VERSION "created by canmatrix"

NS_ :

BS_:

BU_: BDC_Body CHC DME1 EME FLA NiVi ZGW Kombi Kombi_Basis Diagnosetool_FA_CAN CDC_ZGW DME2 ELV Gliwa_T1_Host FA_CAN_Dummy

BO_ 672 CTR_ZV: 8 ZGW
 SG_ CTR_CLSY_DRD : 0|4@1+ (1,0) [0|15] "" EME
 SG_ CTR_CLSY_BTL : 16|4@1+ (1,0) [0|15] "" EME

BO_ 1942 ComponentTheftProtectionRequestK: 8 BDC_Body

BO_ 1943 ComponentTheftProtectionResponse: 8 Kombi

BO_ 1069 ConfigurationHUD2: 8 Kombi
 SG_ ListEntryAdditionalDisplayHUD : 56|8@1+ (1,0) [0|255] "" ZGW

BO_ 622 ConfigurationSChargeRemoteComman: 2 ZGW
 SG_ OperationChargeControlPlugRemote : 4|2@1+ (1,0) [0|3] "" EME

BO_ 439 ControlDisplayDrift: 8 ZGW
 SG_ ControlDriftAssistLampFrequency : 0|4@1+ (0.25,0.5) [0.625|1.375] "Hz" Kombi
 SG_ ControlDriftAssist : 6|2@1+ (1,0) [0|3] "" Kombi

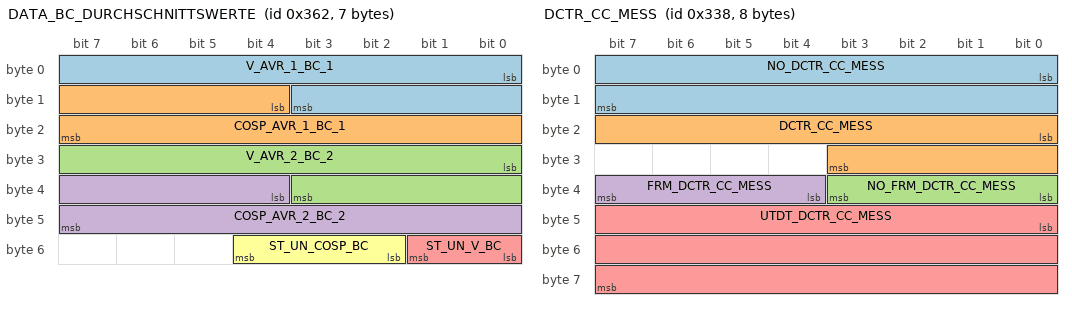
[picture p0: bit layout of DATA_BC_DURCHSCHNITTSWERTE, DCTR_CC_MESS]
BO_ 866 DATA_BC_DURCHSCHNITTSWERTE: 7 Kombi
 SG_ V_AVR_1_BC_1 : 0|12@1+ (0.1,0) [0|40.94] "This unit fulfills the required AUTOSAR reference to a unit. No real unit is defined." ZGW
 SG_ COSP_AVR_1_BC_1 : 12|12@1+ (0.1,0) [0|40.94] "This unit fulfills the required AUTOSAR reference to a unit. No real unit is defined." ZGW
 SG_ V_AVR_2_BC_2 : 24|12@1+ (0.1,0) [0|40.94] "This unit fulfills the required AUTOSAR reference to a unit. No real unit is defined." ZGW
 SG_ COSP_AVR_2_BC_2 : 36|12@1+ (0.1,0) [0|40.94] "This unit fulfills the required AUTOSAR reference to a unit. No real unit is defined." ZGW
 SG_ ST_UN_V_BC : 48|2@1+ (1,0) [0|3] "" ZGW
 SG_ ST_UN_COSP_BC : 50|3@1+ (1,0) [0|7] "" ZGW

BO_ 864 DATA_BC_FAHRTBEGINN: 7 Kombi
 SG_ HR_DPRT_BC : 0|8@1+ (1,0) [0|254] "h" ZGW
 SG_ MN_DPRT_BC : 8|8@1+ (1,0) [0|254] "min" ZGW
 SG_ DAY_DPRT_BC : 24|8@1+ (1,0) [1|254] "This unit fulfills the required AUTOSAR reference to a unit. No real unit is defined." ZGW
 SG_ MON_DPRT_BC : 36|4@1+ (1,0) [1|14] "This unit fulfills the required AUTOSAR reference to a unit. No real unit is defined." ZGW
 SG_ YR_DPRT_BC : 40|16@1+ (1,0) [0|65534] "This unit fulfills the required AUTOSAR reference to a unit. No real unit is defined." ZGW

BO_ 862 DATA_BC_REISEDATEN: 8 Kombi
 SG_ RDDUR_HRS : 0|12@1+ (1,0) [0|4094] "h" ZGW
 SG_ RDDUR_MNTS : 16|8@1+ (1,0) [0|254] "min" ZGW
 SG_ WAY_PSSD : 24|16@1+ (1,0) [0|65534] "This unit fulfills the required AUTOSAR reference to a unit. No real unit is defined." ZGW

BO_ 824 DCTR_CC_MESS: 8 Kombi_Basis
 SG_ NO_DCTR_CC_MESS : 0|16@1+ (1,0) [0|65534] "This unit fulfills the required AUTOSAR reference to a unit. No real unit is defined." ZGW
 SG_ DCTR_CC_MESS : 16|12@1+ (1,0) [0|4095] "" ZGW
 SG_ NO_FRM_DCTR_CC_MESS : 32|4@1+ (1,0) [0|14] "This unit fulfills the required AUTOSAR reference to a unit. No real unit is defined." ZGW
 SG_ FRM_DCTR_CC_MESS : 36|4@1+ (1,0) [0|14] "This unit fulfills the required AUTOSAR reference to a unit. No real unit is defined." ZGW
 SG_ UTDT_DCTR_CC_MESS : 40|24@1+ (1,0) [0|16777215] "This unit fulfills the required AUTOSAR reference to a unit. No real unit is defined." ZGW

BO_ 1022 DCTR_EOI_1: 8 DME1
 SG_ SU_PREV : 0|8@1+ (1,0) [0|255] "" ZGW
 SG_ SU_ST : 8|8@1+ (1,0) [0|255] "" ZGW
 SG_ SU_MEASMT : 16|8@1+ (1,0) [0|255] "" ZGW
 SG_ SU_RSLT : 24|8@1+ (1,0) [0|255] "" ZGW
 SG_ SU_FRC : 32|8@1+ (1,0) [0|255] "" ZGW

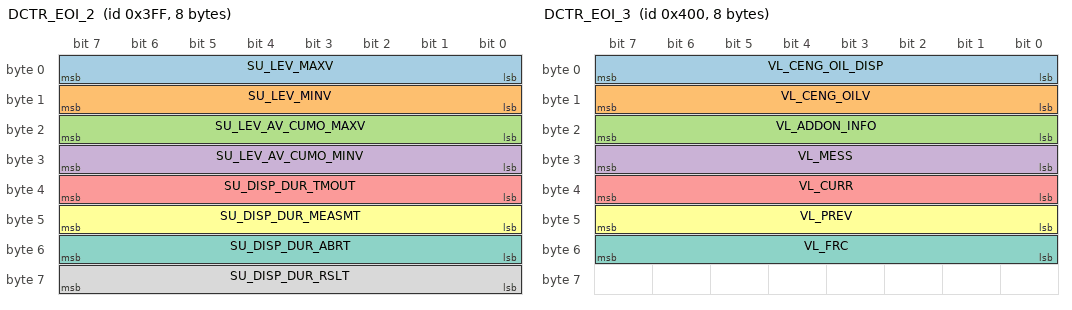
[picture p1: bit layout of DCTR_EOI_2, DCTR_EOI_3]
BO_ 1023 DCTR_EOI_2: 8 DME1
 SG_ SU_LEV_MAXV : 0|8@1+ (1,0) [0|250] "This unit fulfills the required AUTOSAR reference to a unit. No real unit is defined." ZGW
 SG_ SU_LEV_MINV : 8|8@1+ (1,0) [0|250] "This unit fulfills the required AUTOSAR reference to a unit. No real unit is defined." ZGW
 SG_ SU_LEV_AV_CUMO_MAXV : 16|8@1+ (1,0) [0|250] "This unit fulfills the required AUTOSAR reference to a unit. No real unit is defined." ZGW
 SG_ SU_LEV_AV_CUMO_MINV : 24|8@1+ (1,0) [0|250] "This unit fulfills the required AUTOSAR reference to a unit. No real unit is defined." ZGW
 SG_ SU_DISP_DUR_TMOUT : 32|8@1+ (1,0) [0|250] "s" ZGW
 SG_ SU_DISP_DUR_MEASMT : 40|8@1+ (1,0) [0|250] "s" ZGW
 SG_ SU_DISP_DUR_ABRT : 48|8@1+ (1,0) [0|250] "min" ZGW
 SG_ SU_DISP_DUR_RSLT : 56|8@1+ (1,0) [0|250] "min" ZGW

BO_ 1024 DCTR_EOI_3: 8 DME1
 SG_ VL_CENG_OIL_DISP : 0|8@1+ (1,0) [0|255] "" ZGW
 SG_ VL_CENG_OILV : 8|8@1+ (1,0) [0|250] "This unit fulfills the required AUTOSAR reference to a unit. No real unit is defined." ZGW
 SG_ VL_ADDON_INFO : 16|8@1+ (1,0) [0|250] "This unit fulfills the required AUTOSAR reference to a unit. No real unit is defined." ZGW
 SG_ VL_MESS : 24|8@1+ (1,0) [0|255] "" ZGW
 SG_ VL_CURR : 32|8@1+ (1,0) [0|250] "This unit fulfills the required AUTOSAR reference to a unit. No real unit is defined." ZGW
 SG_ VL_PREV : 40|8@1+ (1,0) [0|255] "" ZGW
 SG_ VL_FRC : 48|8@1+ (1,0) [0|250] "min" ZGW

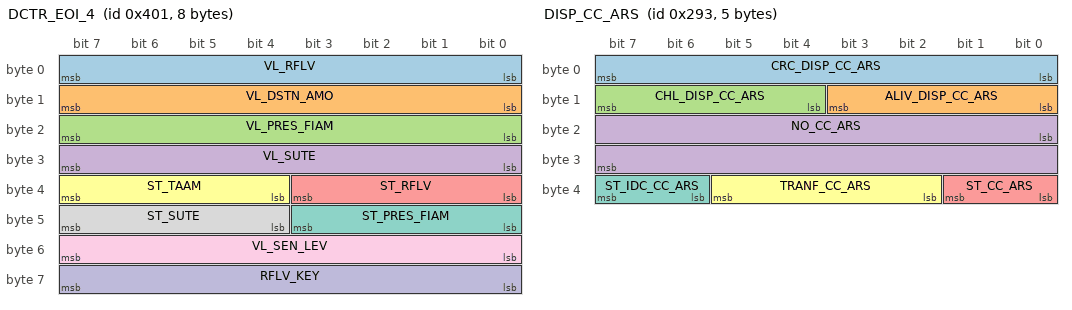
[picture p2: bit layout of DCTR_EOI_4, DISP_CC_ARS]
BO_ 1025 DCTR_EOI_4: 8 DME1
 SG_ VL_RFLV : 0|8@1+ (0.1,0) [0|2.5] "This unit fulfills the required AUTOSAR reference to a unit. No real unit is defined." ZGW
 SG_ VL_DSTN_AMO : 8|8@1+ (0.1,0) [0|2.5] "This unit fulfills the required AUTOSAR reference to a unit. No real unit is defined." ZGW
 SG_ VL_PRES_FIAM : 16|8@1+ (0.1,0) [0|2.5] "This unit fulfills the required AUTOSAR reference to a unit. No real unit is defined." ZGW
 SG_ VL_SUTE : 24|8@1+ (1,0) [0|250] "°C" ZGW
 SG_ ST_RFLV : 32|4@1+ (1,0) [0|15] "" ZGW
 SG_ ST_TAAM : 36|4@1+ (1,0) [0|15] "" ZGW
 SG_ ST_PRES_FIAM : 40|4@1+ (1,0) [0|15] "" ZGW
 SG_ ST_SUTE : 44|4@1+ (1,0) [0|15] "" ZGW
 SG_ VL_SEN_LEV : 48|8@1+ (1,0) [0|250] "mm" ZGW
 SG_ RFLV_KEY : 56|8@1+ (0.1,-12.8) [-14.08|-11.56] "l" BDC_Body

BO_ 919 DIAG_OBD_ENG: 7 ZGW
 SG_ ST_OBD_CYC : 0|6@1+ (1,0) [0|63] "" BDC_Body,CHC

BO_ 1000 DIAG_OBD_ENGMG_EL: 2 EME
 SG_ RQ_MIL_DIAG_OBD_ENGMG_EL : 0|2@1+ (1,0) [0|3] "" Vector__XXX
 SG_ RQ_RST_OBD_DIAG : 2|2@1+ (1,0) [0|3] "" ZGW

BO_ 514 DIMMUNG: 2 BDC_Body
 SG_ CTR_ILUM_SW : 0|8@1+ (1,0) [0|254] "This unit fulfills the required AUTOSAR reference to a unit. No real unit is defined." ZGW,Kombi,Kombi_Basis,DME1

BO_ 659 DISP_CC_ARS: 5 ZGW
 SG_ CRC_DISP_CC_ARS : 0|8@1+ (1,0) [0|255] "This unit fulfills the required AUTOSAR reference to a unit. No real unit is defined." Vector__XXX
 SG_ ALIV_DISP_CC_ARS : 8|4@1+ (1,0) [0|14] "This unit fulfills the required AUTOSAR reference to a unit. No real unit is defined." Vector__XXX
 SG_ CHL_DISP_CC_ARS : 12|4@1+ (1,0) [0|14] "This unit fulfills the required AUTOSAR reference to a unit. No real unit is defined." Vector__XXX
 SG_ NO_CC_ARS : 16|16@1+ (1,0) [0|65534] "This unit fulfills the required AUTOSAR reference to a unit. No real unit is defined." Vector__XXX
 SG_ ST_CC_ARS : 32|2@1+ (1,0) [0|3] "" Vector__XXX
 SG_ TRANF_CC_ARS : 34|4@1+ (1,0) [0|14] "s" Vector__XXX
 SG_ ST_IDC_CC_ARS : 38|2@1+ (1,0) [0|3] "" Vector__XXX

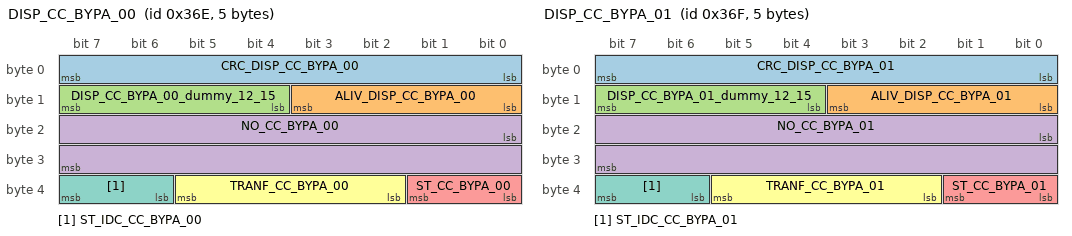
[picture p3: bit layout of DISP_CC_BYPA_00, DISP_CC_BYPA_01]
BO_ 878 DISP_CC_BYPA_00: 5 ZGW
 SG_ CRC_DISP_CC_BYPA_00 : 0|8@1+ (1,0) [0|255] "This unit fulfills the required AUTOSAR reference to a unit. No real unit is defined." Vector__XXX
 SG_ ALIV_DISP_CC_BYPA_00 : 8|4@1+ (1,0) [0|14] "This unit fulfills the required AUTOSAR reference to a unit. No real unit is defined." Vector__XXX
 SG_ DISP_CC_BYPA_00_dummy_12_15 : 12|4@1+ (1,0) [-8|7] "" Vector__XXX
 SG_ NO_CC_BYPA_00 : 16|16@1+ (1,0) [0|65534] "This unit fulfills the required AUTOSAR reference to a unit. No real unit is defined." Vector__XXX
 SG_ ST_CC_BYPA_00 : 32|2@1+ (1,0) [0|3] "" Vector__XXX
 SG_ TRANF_CC_BYPA_00 : 34|4@1+ (1,0) [0|14] "This unit fulfills the required AUTOSAR reference to a unit. No real unit is defined." Vector__XXX
 SG_ ST_IDC_CC_BYPA_00 : 38|2@1+ (1,0) [0|3] "" Vector__XXX

BO_ 879 DISP_CC_BYPA_01: 5 ZGW
 SG_ CRC_DISP_CC_BYPA_01 : 0|8@1+ (1,0) [0|255] "This unit fulfills the required AUTOSAR reference to a unit. No real unit is defined." Vector__XXX
 SG_ ALIV_DISP_CC_BYPA_01 : 8|4@1+ (1,0) [0|14] "This unit fulfills the required AUTOSAR reference to a unit. No real unit is defined." Vector__XXX
 SG_ DISP_CC_BYPA_01_dummy_12_15 : 12|4@1+ (1,0) [-8|7] "" Vector__XXX
 SG_ NO_CC_BYPA_01 : 16|16@1+ (1,0) [0|65534] "This unit fulfills the required AUTOSAR reference to a unit. No real unit is defined." Vector__XXX
 SG_ ST_CC_BYPA_01 : 32|2@1+ (1,0) [0|3] "" Vector__XXX
 SG_ TRANF_CC_BYPA_01 : 34|4@1+ (1,0) [0|14] "This unit fulfills the required AUTOSAR reference to a unit. No real unit is defined." Vector__XXX
 SG_ ST_IDC_CC_BYPA_01 : 38|2@1+ (1,0) [0|3] "" Vector__XXX

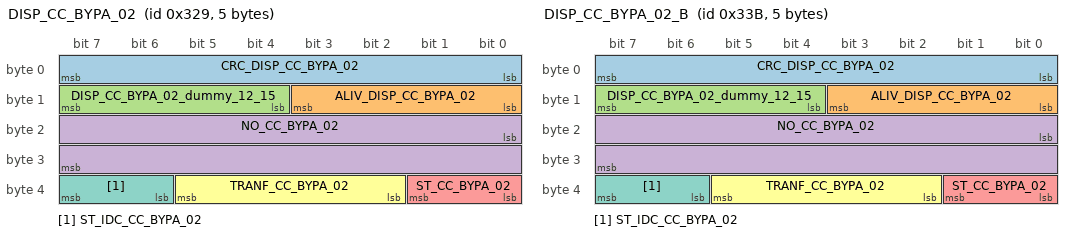
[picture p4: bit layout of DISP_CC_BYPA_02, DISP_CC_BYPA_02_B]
BO_ 809 DISP_CC_BYPA_02: 5 ZGW
 SG_ CRC_DISP_CC_BYPA_02 : 0|8@1+ (1,0) [0|255] "This unit fulfills the required AUTOSAR reference to a unit. No real unit is defined." Vector__XXX
 SG_ ALIV_DISP_CC_BYPA_02 : 8|4@1+ (1,0) [0|14] "This unit fulfills the required AUTOSAR reference to a unit. No real unit is defined." Vector__XXX
 SG_ DISP_CC_BYPA_02_dummy_12_15 : 12|4@1+ (1,0) [-8|7] "" Vector__XXX
 SG_ NO_CC_BYPA_02 : 16|16@1+ (1,0) [0|65534] "This unit fulfills the required AUTOSAR reference to a unit. No real unit is defined." Vector__XXX
 SG_ ST_CC_BYPA_02 : 32|2@1+ (1,0) [0|3] "" Vector__XXX
 SG_ TRANF_CC_BYPA_02 : 34|4@1+ (1,0) [1|14] "s" Vector__XXX
 SG_ ST_IDC_CC_BYPA_02 : 38|2@1+ (1,0) [0|3] "" Vector__XXX

BO_ 827 DISP_CC_BYPA_02_B: 5 ZGW
 SG_ CRC_DISP_CC_BYPA_02 : 0|8@1+ (1,0) [0|255] "This unit fulfills the required AUTOSAR reference to a unit. No real unit is defined." Vector__XXX
 SG_ ALIV_DISP_CC_BYPA_02 : 8|4@1+ (1,0) [0|14] "This unit fulfills the required AUTOSAR reference to a unit. No real unit is defined." Vector__XXX
 SG_ DISP_CC_BYPA_02_dummy_12_15 : 12|4@1+ (1,0) [-8|7] "" Vector__XXX
 SG_ NO_CC_BYPA_02 : 16|16@1+ (1,0) [0|65534] "This unit fulfills the required AUTOSAR reference to a unit. No real unit is defined." Vector__XXX
 SG_ ST_CC_BYPA_02 : 32|2@1+ (1,0) [0|3] "" Vector__XXX
 SG_ TRANF_CC_BYPA_02 : 34|4@1+ (1,0) [1|14] "s" Vector__XXX
 SG_ ST_IDC_CC_BYPA_02 : 38|2@1+ (1,0) [0|3] "" Vector__XXX

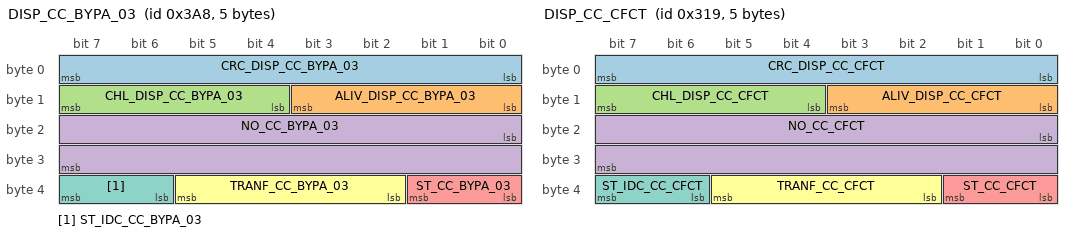
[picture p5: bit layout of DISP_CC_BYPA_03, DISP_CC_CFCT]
BO_ 936 DISP_CC_BYPA_03: 5 ZGW
 SG_ CRC_DISP_CC_BYPA_03 : 0|8@1+ (1,0) [0|255] "This unit fulfills the required AUTOSAR reference to a unit. No real unit is defined." Vector__XXX
 SG_ ALIV_DISP_CC_BYPA_03 : 8|4@1+ (1,0) [0|14] "This unit fulfills the required AUTOSAR reference to a unit. No real unit is defined." Vector__XXX
 SG_ CHL_DISP_CC_BYPA_03 : 12|4@1+ (1,0) [0|14] "This unit fulfills the required AUTOSAR reference to a unit. No real unit is defined." Vector__XXX
 SG_ NO_CC_BYPA_03 : 16|16@1+ (1,0) [0|65534] "This unit fulfills the required AUTOSAR reference to a unit. No real unit is defined." Vector__XXX
 SG_ ST_CC_BYPA_03 : 32|2@1+ (1,0) [0|3] "" Vector__XXX
 SG_ TRANF_CC_BYPA_03 : 34|4@1+ (1,0) [1|14] "s" Vector__XXX
 SG_ ST_IDC_CC_BYPA_03 : 38|2@1+ (1,0) [0|3] "" Vector__XXX

BO_ 793 DISP_CC_CFCT: 5 BDC_Body
 SG_ CRC_DISP_CC_CFCT : 0|8@1+ (1,0) [0|255] "This unit fulfills the required AUTOSAR reference to a unit. No real unit is defined." Vector__XXX
 SG_ ALIV_DISP_CC_CFCT : 8|4@1+ (1,0) [0|14] "This unit fulfills the required AUTOSAR reference to a unit. No real unit is defined." Vector__XXX
 SG_ CHL_DISP_CC_CFCT : 12|4@1+ (1,0) [0|14] "This unit fulfills the required AUTOSAR reference to a unit. No real unit is defined." Vector__XXX
 SG_ NO_CC_CFCT : 16|16@1+ (1,0) [0|65534] "This unit fulfills the required AUTOSAR reference to a unit. No real unit is defined." Vector__XXX
 SG_ ST_CC_CFCT : 32|2@1+ (1,0) [0|3] "" Vector__XXX
 SG_ TRANF_CC_CFCT : 34|4@1+ (1,0) [0|14] "This unit fulfills the required AUTOSAR reference to a unit. No real unit is defined." Vector__XXX
 SG_ ST_IDC_CC_CFCT : 38|2@1+ (1,0) [0|3] "" Vector__XXX

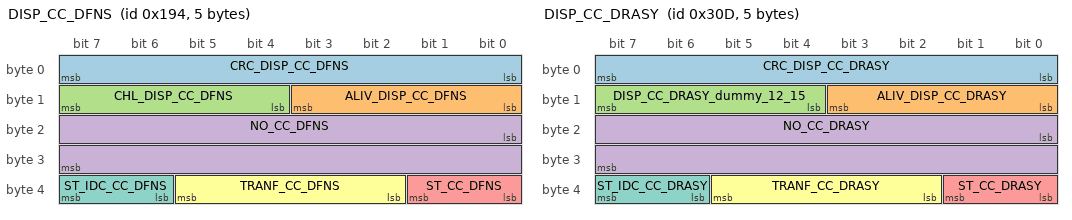
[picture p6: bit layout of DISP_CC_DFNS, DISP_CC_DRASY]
BO_ 404 DISP_CC_DFNS: 5 DME1
 SG_ CRC_DISP_CC_DFNS : 0|8@1+ (1,0) [0|255] "This unit fulfills the required AUTOSAR reference to a unit. No real unit is defined." Vector__XXX
 SG_ ALIV_DISP_CC_DFNS : 8|4@1+ (1,0) [0|14] "This unit fulfills the required AUTOSAR reference to a unit. No real unit is defined." Vector__XXX
 SG_ CHL_DISP_CC_DFNS : 12|4@1+ (1,0) [0|14] "This unit fulfills the required AUTOSAR reference to a unit. No real unit is defined." Vector__XXX
 SG_ NO_CC_DFNS : 16|16@1+ (1,0) [0|65534] "This unit fulfills the required AUTOSAR reference to a unit. No real unit is defined." Vector__XXX
 SG_ ST_CC_DFNS : 32|2@1+ (1,0) [0|3] "" Vector__XXX
 SG_ TRANF_CC_DFNS : 34|4@1+ (1,0) [0|14] "s" Vector__XXX
 SG_ ST_IDC_CC_DFNS : 38|2@1+ (1,0) [0|3] "" Vector__XXX

BO_ 781 DISP_CC_DRASY: 5 ZGW
 SG_ CRC_DISP_CC_DRASY : 0|8@1+ (1,0) [0|255] "This unit fulfills the required AUTOSAR reference to a unit. No real unit is defined." Vector__XXX
 SG_ ALIV_DISP_CC_DRASY : 8|4@1+ (1,0) [0|14] "This unit fulfills the required AUTOSAR reference to a unit. No real unit is defined." Vector__XXX
 SG_ DISP_CC_DRASY_dummy_12_15 : 12|4@1+ (1,0) [-8|7] "" Vector__XXX
 SG_ NO_CC_DRASY : 16|16@1+ (1,0) [0|65534] "This unit fulfills the required AUTOSAR reference to a unit. No real unit is defined." Vector__XXX
 SG_ ST_CC_DRASY : 32|2@1+ (1,0) [0|3] "" Vector__XXX
 SG_ TRANF_CC_DRASY : 34|4@1+ (1,0) [1|14] "s" Vector__XXX
 SG_ ST_IDC_CC_DRASY : 38|2@1+ (1,0) [0|3] "" Vector__XXX

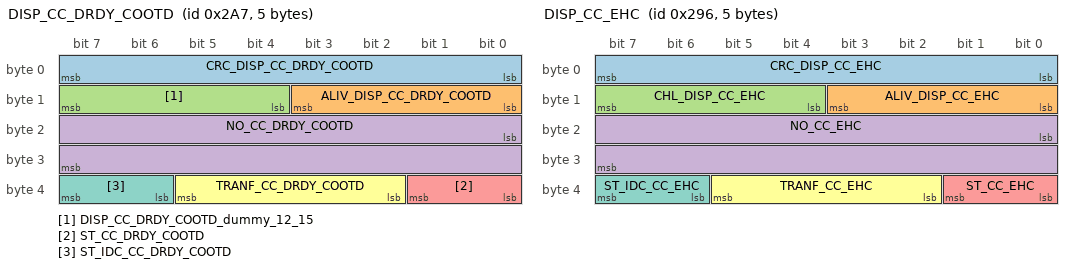
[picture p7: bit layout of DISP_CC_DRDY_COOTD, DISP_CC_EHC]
BO_ 679 DISP_CC_DRDY_COOTD: 5 ZGW
 SG_ CRC_DISP_CC_DRDY_COOTD : 0|8@1+ (1,0) [0|255] "This unit fulfills the required AUTOSAR reference to a unit. No real unit is defined." Vector__XXX
 SG_ ALIV_DISP_CC_DRDY_COOTD : 8|4@1+ (1,0) [0|14] "This unit fulfills the required AUTOSAR reference to a unit. No real unit is defined." Vector__XXX
 SG_ DISP_CC_DRDY_COOTD_dummy_12_15 : 12|4@1+ (1,0) [-8|7] "" Vector__XXX
 SG_ NO_CC_DRDY_COOTD : 16|16@1+ (1,0) [0|65534] "This unit fulfills the required AUTOSAR reference to a unit. No real unit is defined." Vector__XXX
 SG_ ST_CC_DRDY_COOTD : 32|2@1+ (1,0) [0|3] "" Vector__XXX
 SG_ TRANF_CC_DRDY_COOTD : 34|4@1+ (1,0) [0|14] "This unit fulfills the required AUTOSAR reference to a unit. No real unit is defined." Vector__XXX
 SG_ ST_IDC_CC_DRDY_COOTD : 38|2@1+ (1,0) [0|3] "" Vector__XXX

BO_ 662 DISP_CC_EHC: 5 CHC
 SG_ CRC_DISP_CC_EHC : 0|8@1+ (1,0) [0|255] "This unit fulfills the required AUTOSAR reference to a unit. No real unit is defined." Vector__XXX
 SG_ ALIV_DISP_CC_EHC : 8|4@1+ (1,0) [0|14] "This unit fulfills the required AUTOSAR reference to a unit. No real unit is defined." Vector__XXX
 SG_ CHL_DISP_CC_EHC : 12|4@1+ (1,0) [0|14] "This unit fulfills the required AUTOSAR reference to a unit. No real unit is defined." Vector__XXX
 SG_ NO_CC_EHC : 16|16@1+ (1,0) [0|65534] "This unit fulfills the required AUTOSAR reference to a unit. No real unit is defined." Vector__XXX
 SG_ ST_CC_EHC : 32|2@1+ (1,0) [0|3] "" Vector__XXX
 SG_ TRANF_CC_EHC : 34|4@1+ (1,0) [0|14] "s" Vector__XXX
 SG_ ST_IDC_CC_EHC : 38|2@1+ (1,0) [0|3] "" Vector__XXX

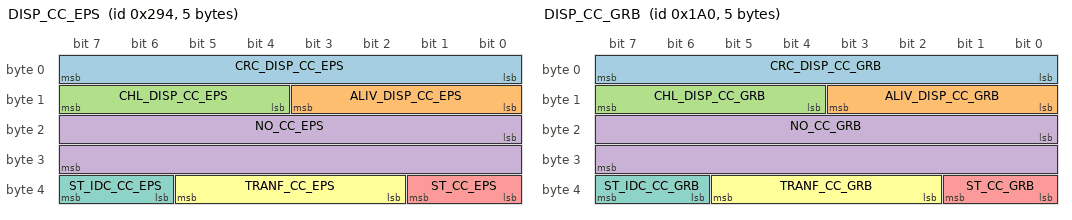
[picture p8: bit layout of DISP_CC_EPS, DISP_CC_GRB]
BO_ 660 DISP_CC_EPS: 5 ZGW
 SG_ CRC_DISP_CC_EPS : 0|8@1+ (1,0) [0|255] "This unit fulfills the required AUTOSAR reference to a unit. No real unit is defined." Vector__XXX
 SG_ ALIV_DISP_CC_EPS : 8|4@1+ (1,0) [0|14] "This unit fulfills the required AUTOSAR reference to a unit. No real unit is defined." Vector__XXX
 SG_ CHL_DISP_CC_EPS : 12|4@1+ (1,0) [0|14] "This unit fulfills the required AUTOSAR reference to a unit. No real unit is defined." Vector__XXX
 SG_ NO_CC_EPS : 16|16@1+ (1,0) [0|65534] "This unit fulfills the required AUTOSAR reference to a unit. No real unit is defined." Vector__XXX
 SG_ ST_CC_EPS : 32|2@1+ (1,0) [0|3] "" Vector__XXX
 SG_ TRANF_CC_EPS : 34|4@1+ (1,0) [0|14] "s" Vector__XXX
 SG_ ST_IDC_CC_EPS : 38|2@1+ (1,0) [0|3] "" Vector__XXX

BO_ 416 DISP_CC_GRB: 5 DME1
 SG_ CRC_DISP_CC_GRB : 0|8@1+ (1,0) [0|255] "This unit fulfills the required AUTOSAR reference to a unit. No real unit is defined." Vector__XXX
 SG_ ALIV_DISP_CC_GRB : 8|4@1+ (1,0) [0|14] "This unit fulfills the required AUTOSAR reference to a unit. No real unit is defined." Vector__XXX
 SG_ CHL_DISP_CC_GRB : 12|4@1+ (1,0) [0|14] "This unit fulfills the required AUTOSAR reference to a unit. No real unit is defined." Vector__XXX
 SG_ NO_CC_GRB : 16|16@1+ (1,0) [0|65532] "This unit fulfills the required AUTOSAR reference to a unit. No real unit is defined." Vector__XXX
 SG_ ST_CC_GRB : 32|2@1+ (1,0) [0|3] "" Vector__XXX
 SG_ TRANF_CC_GRB : 34|4@1+ (1,0) [0|12] "s" Vector__XXX
 SG_ ST_IDC_CC_GRB : 38|2@1+ (1,0) [0|3] "" Vector__XXX

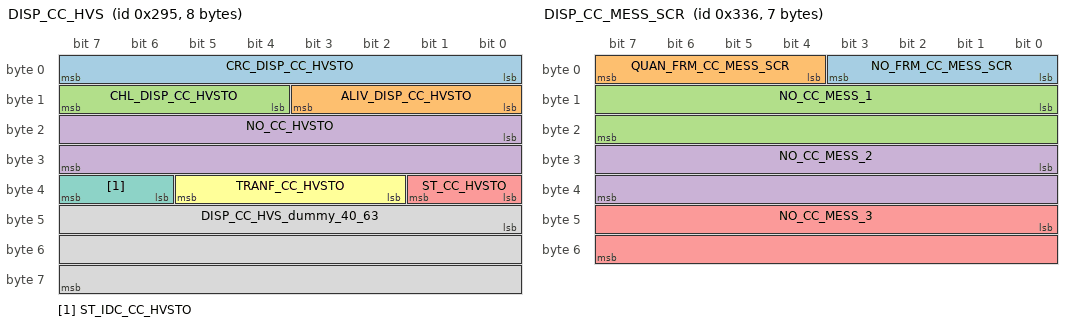
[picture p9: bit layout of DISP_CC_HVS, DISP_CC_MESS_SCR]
BO_ 661 DISP_CC_HVS: 8 EME
 SG_ CRC_DISP_CC_HVSTO : 0|8@1+ (1,0) [0|255] "This unit fulfills the required AUTOSAR reference to a unit. No real unit is defined." Vector__XXX
 SG_ ALIV_DISP_CC_HVSTO : 8|4@1+ (1,0) [0|14] "This unit fulfills the required AUTOSAR reference to a unit. No real unit is defined." Vector__XXX
 SG_ CHL_DISP_CC_HVSTO : 12|4@1+ (1,0) [0|14] "This unit fulfills the required AUTOSAR reference to a unit. No real unit is defined." Vector__XXX
 SG_ NO_CC_HVSTO : 16|16@1+ (1,0) [0|65534] "This unit fulfills the required AUTOSAR reference to a unit. No real unit is defined." Vector__XXX
 SG_ ST_CC_HVSTO : 32|2@1+ (1,0) [0|3] "" Vector__XXX
 SG_ TRANF_CC_HVSTO : 34|4@1+ (1,0) [0|14] "This unit fulfills the required AUTOSAR reference to a unit. No real unit is defined." Vector__XXX
 SG_ ST_IDC_CC_HVSTO : 38|2@1+ (1,0) [0|3] "" Vector__XXX
 SG_ DISP_CC_HVS_dummy_40_63 : 40|24@1+ (1,0) [-8388608|8388607] "" Vector__XXX

BO_ 822 DISP_CC_MESS_SCR: 7 Kombi
 SG_ NO_FRM_CC_MESS_SCR : 0|4@1+ (1,0) [0|14] "This unit fulfills the required AUTOSAR reference to a unit. No real unit is defined." ZGW
 SG_ QUAN_FRM_CC_MESS_SCR : 4|4@1+ (1,0) [0|14] "This unit fulfills the required AUTOSAR reference to a unit. No real unit is defined." ZGW
 SG_ NO_CC_MESS_1 : 8|16@1+ (1,0) [0|65534] "This unit fulfills the required AUTOSAR reference to a unit. No real unit is defined." ZGW
 SG_ NO_CC_MESS_2 : 24|16@1+ (1,0) [0|65534] "This unit fulfills the required AUTOSAR reference to a unit. No real unit is defined." ZGW
 SG_ NO_CC_MESS_3 : 40|16@1+ (1,0) [0|65534] "This unit fulfills the required AUTOSAR reference to a unit. No real unit is defined." ZGW

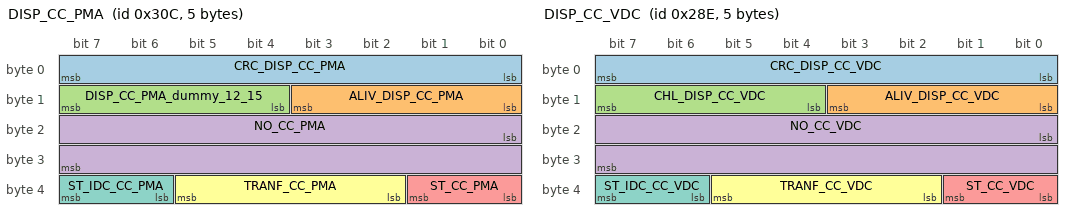
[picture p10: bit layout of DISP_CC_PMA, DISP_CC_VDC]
BO_ 780 DISP_CC_PMA: 5 ZGW
 SG_ CRC_DISP_CC_PMA : 0|8@1+ (1,0) [0|255] "This unit fulfills the required AUTOSAR reference to a unit. No real unit is defined." Vector__XXX
 SG_ ALIV_DISP_CC_PMA : 8|4@1+ (1,0) [0|14] "This unit fulfills the required AUTOSAR reference to a unit. No real unit is defined." Vector__XXX
 SG_ DISP_CC_PMA_dummy_12_15 : 12|4@1+ (1,0) [-8|7] "" Vector__XXX
 SG_ NO_CC_PMA : 16|16@1+ (1,0) [0|65534] "This unit fulfills the required AUTOSAR reference to a unit. No real unit is defined." Vector__XXX
 SG_ ST_CC_PMA : 32|2@1+ (1,0) [0|3] "" Vector__XXX
 SG_ TRANF_CC_PMA : 34|4@1+ (1,0) [1|14] "s" Vector__XXX
 SG_ ST_IDC_CC_PMA : 38|2@1+ (1,0) [0|3] "" Vector__XXX

BO_ 654 DISP_CC_VDC: 5 ZGW
 SG_ CRC_DISP_CC_VDC : 0|8@1+ (1,0) [0|255] "This unit fulfills the required AUTOSAR reference to a unit. No real unit is defined." Vector__XXX
 SG_ ALIV_DISP_CC_VDC : 8|4@1+ (1,0) [0|14] "This unit fulfills the required AUTOSAR reference to a unit. No real unit is defined." Vector__XXX
 SG_ CHL_DISP_CC_VDC : 12|4@1+ (1,0) [0|14] "This unit fulfills the required AUTOSAR reference to a unit. No real unit is defined." Vector__XXX
 SG_ NO_CC_VDC : 16|16@1+ (1,0) [0|65534] "This unit fulfills the required AUTOSAR reference to a unit. No real unit is defined." Vector__XXX
 SG_ ST_CC_VDC : 32|2@1+ (1,0) [0|3] "" Vector__XXX
 SG_ TRANF_CC_VDC : 34|4@1+ (1,0) [0|14] "s" Vector__XXX
 SG_ ST_IDC_CC_VDC : 38|2@1+ (1,0) [0|3] "" Vector__XXX

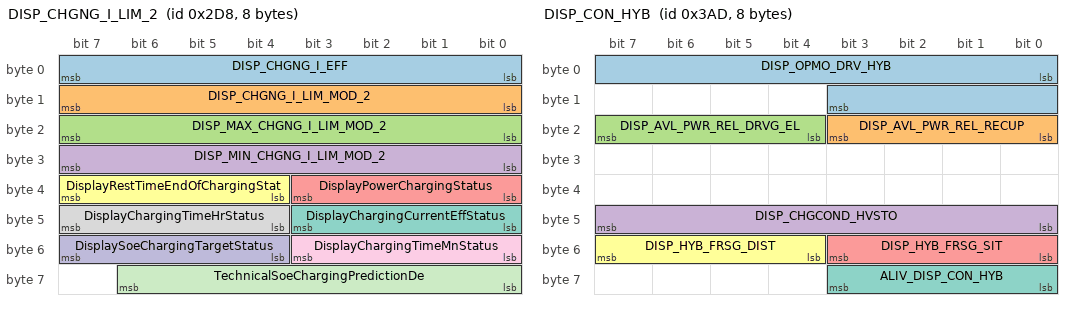
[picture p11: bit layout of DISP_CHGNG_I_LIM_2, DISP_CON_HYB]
BO_ 728 DISP_CHGNG_I_LIM_2: 8 EME
 SG_ DISP_CHGNG_I_EFF : 0|8@1+ (1,0) [0|250] "A" ZGW,Kombi,Kombi_Basis
 SG_ DISP_CHGNG_I_LIM_MOD_2 : 8|8@1+ (1,0) [0|250] "A" ZGW
 SG_ DISP_MAX_CHGNG_I_LIM_MOD_2 : 16|8@1+ (1,0) [0|250] "A" ZGW
 SG_ DISP_MIN_CHGNG_I_LIM_MOD_2 : 24|8@1+ (1,0) [0|250] "A" ZGW
 SG_ DisplayPowerChargingStatus : 32|4@1+ (1,0) [0|15] "" ZGW,Kombi
 SG_ DisplayRestTimeEndOfChargingStat : 36|4@1+ (1,0) [0|15] "" Kombi
 SG_ DisplayChargingCurrentEffStatus : 40|4@1+ (1,0) [0|15] "" Kombi
 SG_ DisplayChargingTimeHrStatus : 44|4@1+ (1,0) [0|15] "" Kombi
 SG_ DisplayChargingTimeMnStatus : 48|4@1+ (1,0) [0|15] "" Kombi
 SG_ DisplaySoeChargingTargetStatus : 52|4@1+ (1,0) [0|15] "" Kombi
 SG_ TechnicalSoeChargingPredictionDe : 56|7@1+ (1,0) [0|100] "%" Kombi

BO_ 941 DISP_CON_HYB: 8 DME1
 SG_ DISP_OPMO_DRV_HYB : 0|12@1+ (1,0) [0|4095] "" ZGW,Kombi,Kombi_Basis
 SG_ DISP_AVL_PWR_REL_RECUP : 16|4@1+ (10,0) [0|1000] "%" ZGW
 SG_ DISP_AVL_PWR_REL_DRVG_EL : 20|4@1+ (10,0) [0|1000] "%" ZGW
 SG_ DISP_CHGCOND_HVSTO : 40|8@1+ (0.5,0) [0|50] "%" CDC_ZGW,Kombi,BDC_Body,ZGW
 SG_ DISP_HYB_FRSG_SIT : 48|4@1+ (1,0) [0|15] "" ZGW
 SG_ DISP_HYB_FRSG_DIST : 52|4@1+ (1,0) [0|15] "" ZGW
 SG_ ALIV_DISP_CON_HYB : 56|4@1+ (1,0) [0|14] "This unit fulfills the required AUTOSAR reference to a unit. No real unit is defined." Kombi,Kombi_Basis

BO_ 1036 DISP_COSA_HYB: 5 EME
 SG_ DISP_EFFS_HYB : 8|8@1+ (1,0) [0|100] "%" ZGW,Kombi

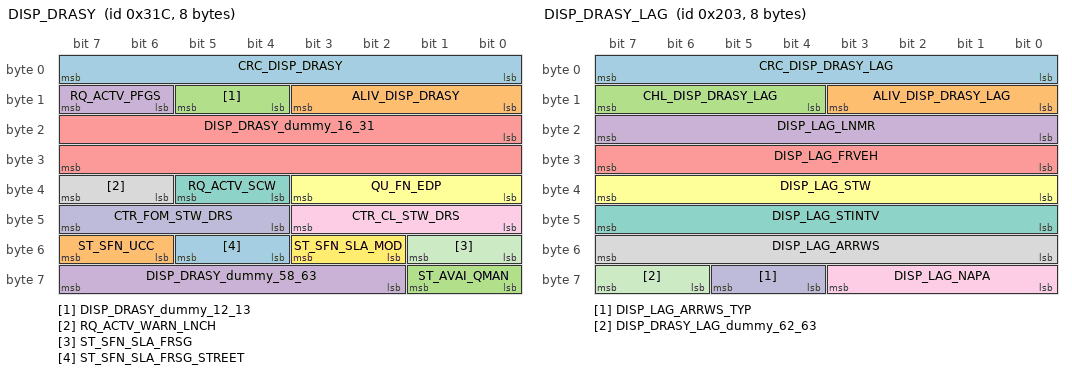
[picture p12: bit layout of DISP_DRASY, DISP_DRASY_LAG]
BO_ 796 DISP_DRASY: 8 ZGW
 SG_ CRC_DISP_DRASY : 0|8@1+ (1,0) [0|255] "This unit fulfills the required AUTOSAR reference to a unit. No real unit is defined." Vector__XXX
 SG_ ALIV_DISP_DRASY : 8|4@1+ (1,0) [0|14] "This unit fulfills the required AUTOSAR reference to a unit. No real unit is defined." Vector__XXX
 SG_ DISP_DRASY_dummy_12_13 : 12|2@1+ (1,0) [-2|1] "" Vector__XXX
 SG_ RQ_ACTV_PFGS : 14|2@1+ (1,0) [0|3] "" Vector__XXX
 SG_ DISP_DRASY_dummy_16_31 : 16|16@1+ (1,0) [-32768|32767] "" Vector__XXX
 SG_ QU_FN_EDP : 32|4@1+ (1,0) [0|15] "" Vector__XXX
 SG_ RQ_ACTV_SCW : 36|2@1+ (1,0) [0|3] "" Vector__XXX
 SG_ RQ_ACTV_WARN_LNCH : 38|2@1+ (1,0) [0|3] "" Vector__XXX
 SG_ CTR_CL_STW_DRS : 40|4@1+ (1,0) [0|15] "" Vector__XXX
 SG_ CTR_FOM_STW_DRS : 44|4@1+ (1,0) [0|15] "" Vector__XXX
 SG_ ST_SFN_SLA_FRSG : 48|2@1+ (1,0) [0|3] "" Vector__XXX
 SG_ ST_SFN_SLA_MOD : 50|2@1+ (1,0) [0|3] "" Vector__XXX
 SG_ ST_SFN_SLA_FRSG_STREET : 52|2@1+ (1,0) [0|3] "" Vector__XXX
 SG_ ST_SFN_UCC : 54|2@1+ (1,0) [0|3] "" Vector__XXX
 SG_ ST_AVAI_QMAN : 56|2@1+ (1,0) [0|3] "" Vector__XXX
 SG_ DISP_DRASY_dummy_58_63 : 58|6@1+ (1,0) [-32|31] "" Vector__XXX

BO_ 515 DISP_DRASY_LAG: 8 ZGW
 SG_ CRC_DISP_DRASY_LAG : 0|8@1+ (1,0) [0|255] "This unit fulfills the required AUTOSAR reference to a unit. No real unit is defined." Vector__XXX
 SG_ ALIV_DISP_DRASY_LAG : 8|4@1+ (1,0) [0|14] "This unit fulfills the required AUTOSAR reference to a unit. No real unit is defined." Vector__XXX
 SG_ CHL_DISP_DRASY_LAG : 12|4@1+ (1,0) [0|14] "This unit fulfills the required AUTOSAR reference to a unit. No real unit is defined." Vector__XXX
 SG_ DISP_LAG_LNMR : 16|8@1+ (1,0) [0|255] "" Vector__XXX
 SG_ DISP_LAG_FRVEH : 24|8@1+ (1,0) [0|255] "" Vector__XXX
 SG_ DISP_LAG_STW : 32|8@1+ (1,0) [0|255] "" Vector__XXX
 SG_ DISP_LAG_STINTV : 40|8@1+ (1,0) [0|255] "" Vector__XXX
 SG_ DISP_LAG_ARRWS : 48|8@1+ (1,0) [0|255] "" Vector__XXX
 SG_ DISP_LAG_NAPA : 56|4@1+ (1,0) [0|15] "" Vector__XXX
 SG_ DISP_LAG_ARRWS_TYP : 60|2@1+ (1,0) [0|3] "" Vector__XXX
 SG_ DISP_DRASY_LAG_dummy_62_63 : 62|2@1+ (1,0) [-2|1] "" Vector__XXX

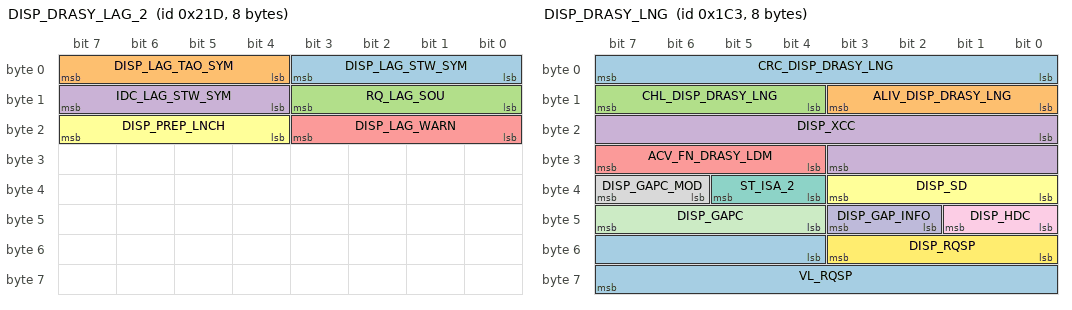
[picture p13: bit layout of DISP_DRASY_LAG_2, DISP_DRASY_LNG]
BO_ 541 DISP_DRASY_LAG_2: 8 ZGW
 SG_ DISP_LAG_STW_SYM : 0|4@1+ (1,0) [0|15] "" Kombi,Kombi_Basis
 SG_ DISP_LAG_TAO_SYM : 4|4@1+ (1,0) [0|15] "" Kombi,Kombi_Basis
 SG_ RQ_LAG_SOU : 8|4@1+ (1,0) [0|15] "" Kombi,Kombi_Basis
 SG_ IDC_LAG_STW_SYM : 12|4@1+ (1,0) [0|15] "" Kombi,Kombi_Basis
 SG_ DISP_LAG_WARN : 16|4@1+ (1,0) [0|15] "" Kombi,Kombi_Basis
 SG_ DISP_PREP_LNCH : 20|4@1+ (1,0) [0|15] "" Kombi,Kombi_Basis

BO_ 451 DISP_DRASY_LNG: 8 ZGW
 SG_ CRC_DISP_DRASY_LNG : 0|8@1+ (1,0) [0|255] "This unit fulfills the required AUTOSAR reference to a unit. No real unit is defined." Vector__XXX
 SG_ ALIV_DISP_DRASY_LNG : 8|4@1+ (1,0) [0|14] "This unit fulfills the required AUTOSAR reference to a unit. No real unit is defined." Vector__XXX
 SG_ CHL_DISP_DRASY_LNG : 12|4@1+ (1,0) [0|14] "This unit fulfills the required AUTOSAR reference to a unit. No real unit is defined." Vector__XXX
 SG_ DISP_XCC : 16|12@1+ (1,0) [0|4095] "" Vector__XXX
 SG_ ACV_FN_DRASY_LDM : 28|4@1+ (1,0) [0|15] "" Vector__XXX
 SG_ DISP_SD : 32|4@1+ (1,0) [0|15] "" Vector__XXX
 SG_ ST_ISA_2 : 36|2@1+ (1,0) [0|3] "" Vector__XXX
 SG_ DISP_GAPC_MOD : 38|2@1+ (1,0) [0|3] "" Vector__XXX
 SG_ DISP_HDC : 40|2@1+ (1,0) [0|3] "" Vector__XXX
 SG_ DISP_GAP_INFO : 42|2@1+ (1,0) [0|3] "" Vector__XXX
 SG_ DISP_GAPC : 44|4@1+ (1,0) [0|15] "" Vector__XXX
 SG_ DISP_RQSP : 48|4@1+ (1,0) [0|15] "" Vector__XXX
 SG_ VL_RQSP : 52|12@1+ (1,0) [0|350] "This unit fulfills the required AUTOSAR reference to a unit. No real unit is defined." Vector__XXX

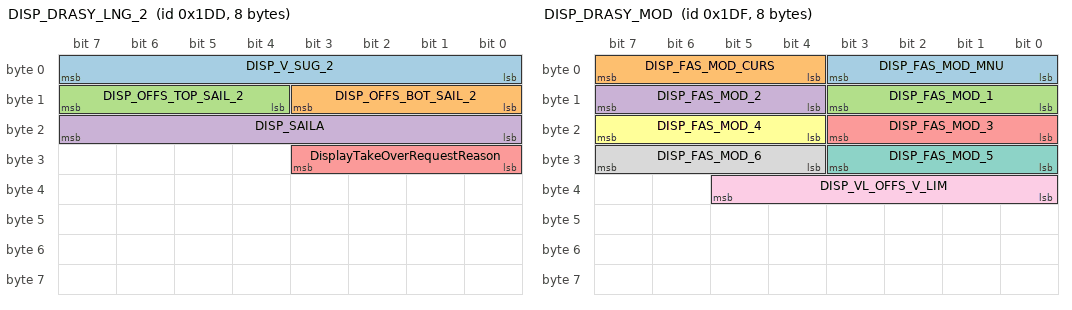
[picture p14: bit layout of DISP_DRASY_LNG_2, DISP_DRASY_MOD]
BO_ 477 DISP_DRASY_LNG_2: 8 ZGW
 SG_ DISP_V_SUG_2 : 0|8@1+ (1,0) [1|252] "This unit fulfills the required AUTOSAR reference to a unit. No real unit is defined." Kombi,Kombi_Basis
 SG_ DISP_OFFS_BOT_SAIL_2 : 8|4@1+ (1,0) [0|12] "This unit fulfills the required AUTOSAR reference to a unit. No real unit is defined." Kombi,Kombi_Basis
 SG_ DISP_OFFS_TOP_SAIL_2 : 12|4@1+ (1,0) [0|12] "This unit fulfills the required AUTOSAR reference to a unit. No real unit is defined." Kombi,Kombi_Basis
 SG_ DISP_SAILA : 16|8@1+ (1,0) [0|255] "" Kombi,Kombi_Basis
 SG_ DisplayTakeOverRequestReason : 24|4@1+ (1,0) [0|15] "" Kombi,Kombi_Basis

BO_ 479 DISP_DRASY_MOD: 8 ZGW
 SG_ DISP_FAS_MOD_MNU : 0|4@1+ (1,0) [0|15] "" Kombi,Kombi_Basis
 SG_ DISP_FAS_MOD_CURS : 4|4@1+ (1,0) [0|15] "" Kombi,Kombi_Basis
 SG_ DISP_FAS_MOD_1 : 8|4@1+ (1,0) [0|15] "" Kombi,Kombi_Basis
 SG_ DISP_FAS_MOD_2 : 12|4@1+ (1,0) [0|15] "" Kombi,Kombi_Basis
 SG_ DISP_FAS_MOD_3 : 16|4@1+ (1,0) [0|15] "" Kombi,Kombi_Basis
 SG_ DISP_FAS_MOD_4 : 20|4@1+ (1,0) [0|15] "" Kombi,Kombi_Basis
 SG_ DISP_FAS_MOD_5 : 24|4@1+ (1,0) [0|15] "" Kombi,Kombi_Basis
 SG_ DISP_FAS_MOD_6 : 28|4@1+ (1,0) [0|15] "" Kombi,Kombi_Basis
 SG_ DISP_VL_OFFS_V_LIM : 32|6@1+ (1,-30) [-60|0] "This unit fulfills the required AUTOSAR reference to a unit. No real unit is defined." Kombi,Kombi_Basis

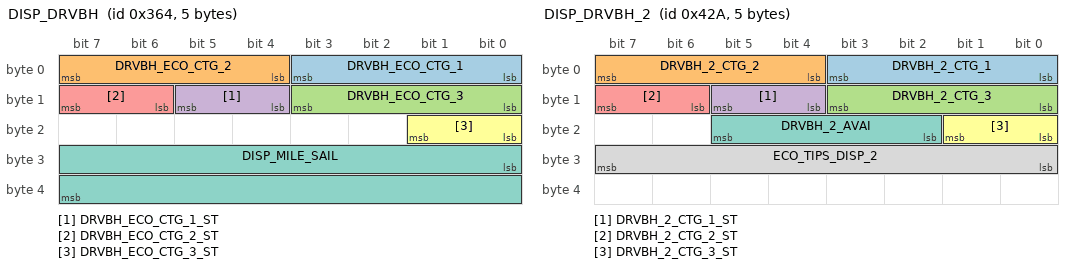
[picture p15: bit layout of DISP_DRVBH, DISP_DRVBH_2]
BO_ 868 DISP_DRVBH: 5 Kombi
 SG_ DRVBH_ECO_CTG_1 : 0|4@1+ (0.5,0) [0|2.5] "This unit fulfills the required AUTOSAR reference to a unit. No real unit is defined." ZGW
 SG_ DRVBH_ECO_CTG_2 : 4|4@1+ (0.5,0) [0|2.5] "This unit fulfills the required AUTOSAR reference to a unit. No real unit is defined." ZGW
 SG_ DRVBH_ECO_CTG_3 : 8|4@1+ (0.5,0) [0|2.5] "This unit fulfills the required AUTOSAR reference to a unit. No real unit is defined." ZGW
 SG_ DRVBH_ECO_CTG_1_ST : 12|2@1+ (1,0) [0|3] "" ZGW
 SG_ DRVBH_ECO_CTG_2_ST : 14|2@1+ (1,0) [0|3] "" ZGW
 SG_ DRVBH_ECO_CTG_3_ST : 16|2@1+ (1,0) [0|3] "" ZGW
 SG_ DISP_MILE_SAIL : 24|16@1+ (10,0) [0|6553400] "This unit fulfills the required AUTOSAR reference to a unit. No real unit is defined." ZGW

BO_ 1066 DISP_DRVBH_2: 5 Kombi
 SG_ DRVBH_2_CTG_1 : 0|4@1+ (10,0) [0|1000] "%" ZGW
 SG_ DRVBH_2_CTG_2 : 4|4@1+ (10,0) [0|1000] "%" ZGW
 SG_ DRVBH_2_CTG_3 : 8|4@1+ (10,0) [0|1000] "%" ZGW
 SG_ DRVBH_2_CTG_1_ST : 12|2@1+ (1,0) [0|3] "" ZGW
 SG_ DRVBH_2_CTG_2_ST : 14|2@1+ (1,0) [0|3] "" ZGW
 SG_ DRVBH_2_CTG_3_ST : 16|2@1+ (1,0) [0|3] "" ZGW
 SG_ DRVBH_2_AVAI : 18|4@1+ (1,0) [0|15] "" ZGW
 SG_ ECO_TIPS_DISP_2 : 24|8@1+ (1,0) [0|255] "" ZGW

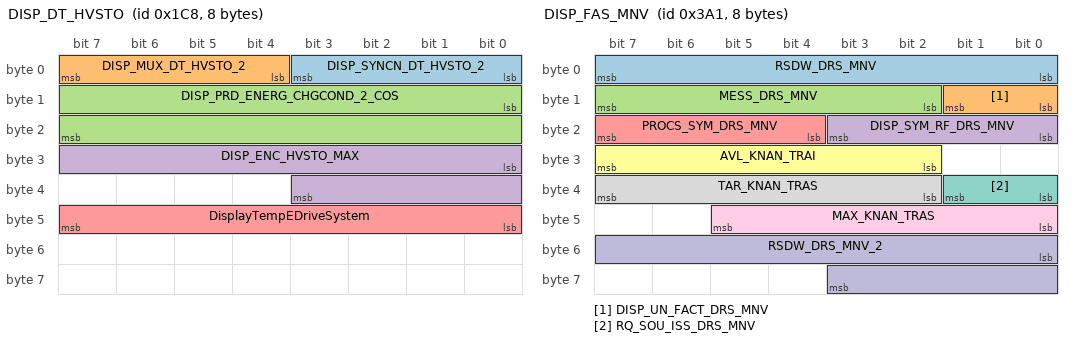
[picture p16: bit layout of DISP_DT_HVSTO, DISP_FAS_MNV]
BO_ 456 DISP_DT_HVSTO: 8 Diagnosetool_FA_CAN
 SG_ DISP_SYNCN_DT_HVSTO_2 : 0|4@1+ (1,0) [0|14] "This unit fulfills the required AUTOSAR reference to a unit. No real unit is defined." Kombi
 SG_ DISP_MUX_DT_HVSTO_2 : 4|4@1+ (1,0) [0|15] "" Kombi
 SG_ DISP_PRD_ENERG_CHGCOND_2_COS : 8|16@1+ (1,0) [0|65534] "Wh" ZGW,Kombi
 SG_ DISP_ENC_HVSTO_MAX : 24|12@1+ (0.02,0) [0.00|1.6376] "kWh" ZGW,Kombi
 SG_ DisplayTempEDriveSystem : 40|8@1+ (1,0) [0|100] "%" Kombi

BO_ 893 DISP_DT_SCR: 5 DME1
 SG_ DISP_RMMI_SCRA : 0|16@1+ (1,0) [0|65534] "This unit fulfills the required AUTOSAR reference to a unit. No real unit is defined." ZGW,BDC_Body
 SG_ DISP_RFLV_SCRA : 16|8@1+ (0.1,0) [0|2.5] "l" ZGW,BDC_Body
 SG_ DISP_FLLV_SCRA : 24|4@1+ (10,0) [0|1200] "%" ZGW,BDC_Body

BO_ 929 DISP_FAS_MNV: 8 ZGW
 SG_ RSDW_DRS_MNV : 0|8@1+ (0.25,0) [0.00|15.75] "This unit fulfills the required AUTOSAR reference to a unit. No real unit is defined." Kombi
 SG_ DISP_UN_FACT_DRS_MNV : 8|2@1+ (1,0) [0|3] "" Kombi
 SG_ MESS_DRS_MNV : 10|6@1+ (1,0) [0|63] "" Kombi
 SG_ DISP_SYM_RF_DRS_MNV : 16|4@1+ (1,0) [0|15] "" Kombi
 SG_ PROCS_SYM_DRS_MNV : 20|4@1+ (1,0) [0|15] "" Kombi
 SG_ AVL_KNAN_TRAI : 26|6@1+ (2,-60) [-180|60] "°" Kombi
 SG_ RQ_SOU_ISS_DRS_MNV : 32|2@1+ (1,0) [0|3] "" Kombi
 SG_ TAR_KNAN_TRAS : 34|6@1+ (2,-60) [-180|60] "°" Kombi
 SG_ MAX_KNAN_TRAS : 40|6@1+ (2,-60) [-180|60] "°" Kombi
 SG_ RSDW_DRS_MNV_2 : 48|12@1+ (0.1,0) [0|40.9] "This unit fulfills the required AUTOSAR reference to a unit. No real unit is defined." Kombi

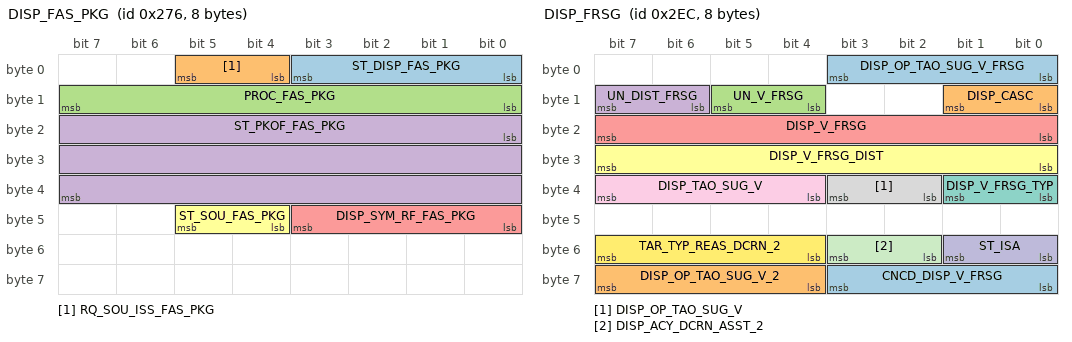
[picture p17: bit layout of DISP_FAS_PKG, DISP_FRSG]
BO_ 630 DISP_FAS_PKG: 8 ZGW
 SG_ ST_DISP_FAS_PKG : 0|4@1+ (1,0) [0|15] "" Kombi
 SG_ RQ_SOU_ISS_FAS_PKG : 4|2@1+ (1,0) [0|3] "" Kombi
 SG_ PROC_FAS_PKG : 8|8@1+ (1,0) [0|255] "" Kombi
 SG_ ST_PKOF_FAS_PKG : 16|24@1+ (1,0) [0|16777215] "" Kombi
 SG_ DISP_SYM_RF_FAS_PKG : 40|4@1+ (1,0) [0|15] "" Kombi
 SG_ ST_SOU_FAS_PKG : 44|2@1+ (1,0) [0|3] "" Kombi

BO_ 748 DISP_FRSG: 8 ZGW
 SG_ DISP_OP_TAO_SUG_V_FRSG : 0|4@1+ (1,0) [0|15] "" Kombi,Kombi_Basis
 SG_ DISP_CASC : 8|2@1+ (1,0) [0|3] "" Kombi,Kombi_Basis
 SG_ UN_V_FRSG : 12|2@1+ (1,0) [0|3] "" Kombi,Kombi_Basis
 SG_ UN_DIST_FRSG : 14|2@1+ (1,0) [0|3] "" Kombi,Kombi_Basis
 SG_ DISP_V_FRSG : 16|8@1+ (1,0) [0|255] "" Kombi,Kombi_Basis
 SG_ DISP_V_FRSG_DIST : 24|8@1+ (10,0) [0|25200] "This unit fulfills the required AUTOSAR reference to a unit. No real unit is defined." Kombi
 SG_ DISP_V_FRSG_TYP : 32|2@1+ (1,0) [0|3] "" Kombi,Kombi_Basis
 SG_ DISP_OP_TAO_SUG_V : 34|2@1+ (1,0) [0|3] "" Kombi,Kombi_Basis
 SG_ DISP_TAO_SUG_V : 36|4@1+ (1,0) [0|15] "" Kombi,Kombi_Basis
 SG_ ST_ISA : 48|2@1+ (1,0) [0|3] "" Kombi,Kombi_Basis
 SG_ DISP_ACY_DCRN_ASST_2 : 50|2@1+ (1,0) [0|3] "" Kombi,Kombi_Basis
 SG_ TAR_TYP_REAS_DCRN_2 : 52|4@1+ (1,0) [0|15] "" Kombi
 SG_ CNCD_DISP_V_FRSG : 56|4@1+ (1,0) [0|15] "" Kombi,Kombi_Basis
 SG_ DISP_OP_TAO_SUG_V_2 : 60|4@1+ (1,0) [0|15] "" Kombi,Kombi_Basis

BO_ 755 DISP_FRSG_2: 8 ZGW
 SG_ DISP_V_SUG : 0|8@1+ (1,0) [1|252] "This unit fulfills the required AUTOSAR reference to a unit. No real unit is defined." Kombi,Kombi_Basis
 SG_ DISP_OFFS_BOT_SAIL : 8|4@1+ (1,0) [0|12] "This unit fulfills the required AUTOSAR reference to a unit. No real unit is defined." Kombi,Kombi_Basis
 SG_ DISP_OFFS_TOP_SAIL : 12|4@1+ (1,0) [0|12] "This unit fulfills the required AUTOSAR reference to a unit. No real unit is defined." Kombi,Kombi_Basis
 SG_ TAR_TYP_REAS_DCRN_3 : 16|8@1+ (1,0) [0|255] "" Kombi

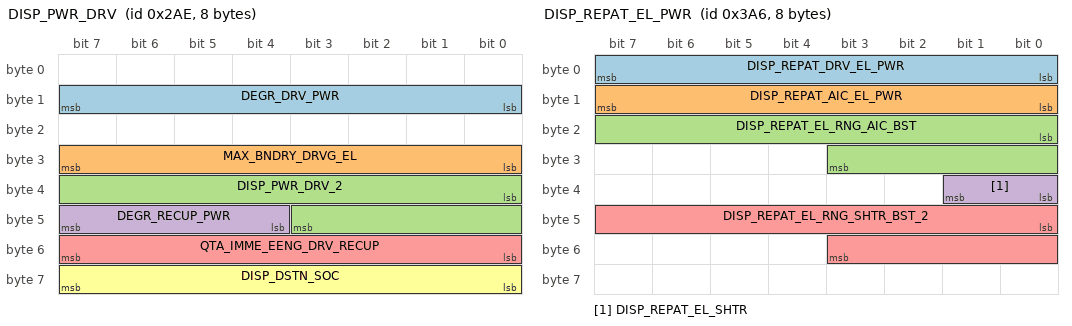
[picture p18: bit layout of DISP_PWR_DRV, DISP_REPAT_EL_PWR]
BO_ 686 DISP_PWR_DRV: 8 DME1
 SG_ DEGR_DRV_PWR : 8|8@1+ (1,0) [0|100] "%" Kombi,Kombi_Basis
 SG_ MAX_BNDRY_DRVG_EL : 24|8@1+ (1,0) [0|100] "%" Kombi,Kombi_Basis
 SG_ DISP_PWR_DRV_2 : 32|12@1+ (0.1,-100) [-110|-88] "%" ZGW,Kombi,Kombi_Basis,EME
 SG_ DEGR_RECUP_PWR : 44|4@1+ (10,-100) [-1100|-100] "%" ZGW,Kombi,Kombi_Basis
 SG_ QTA_IMME_EENG_DRV_RECUP : 48|8@1+ (1,-100) [-200|0] "%" ZGW,Kombi
 SG_ DISP_DSTN_SOC : 56|8@1+ (1,0) [0|100] "%" Kombi

BO_ 934 DISP_REPAT_EL_PWR: 8 Kombi
 SG_ DISP_REPAT_DRV_EL_PWR : 0|8@1+ (0.5,0) [0|50] "%" ZGW
 SG_ DISP_REPAT_AIC_EL_PWR : 8|8@1+ (0.5,0) [0|50] "%" ZGW
 SG_ DISP_REPAT_EL_RNG_AIC_BST : 16|12@1+ (0.1,0) [0|40.94] "This unit fulfills the required AUTOSAR reference to a unit. No real unit is defined." ZGW
 SG_ DISP_REPAT_EL_SHTR : 32|2@1+ (1,0) [0|3] "" ZGW
 SG_ DISP_REPAT_EL_RNG_SHTR_BST_2 : 40|12@1+ (0.1,0) [0|40.92] "This unit fulfills the required AUTOSAR reference to a unit. No real unit is defined." ZGW

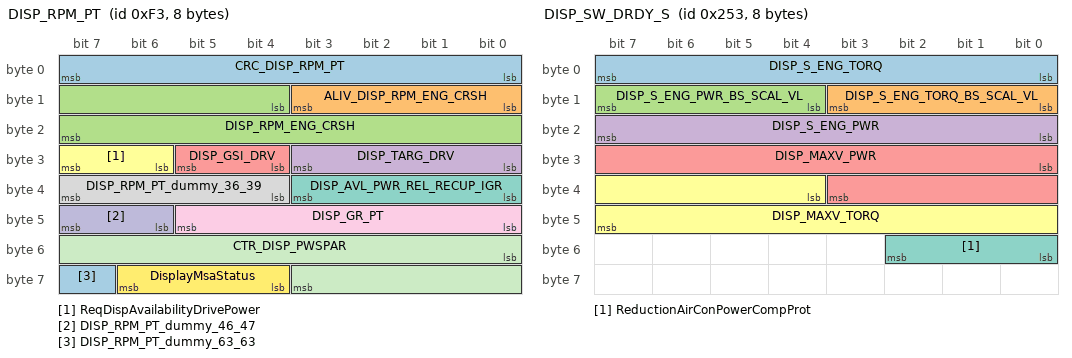
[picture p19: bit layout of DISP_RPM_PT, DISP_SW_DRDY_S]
BO_ 243 DISP_RPM_PT: 8 DME1
 SG_ CRC_DISP_RPM_PT : 0|8@1+ (1,0) [0|255] "This unit fulfills the required AUTOSAR reference to a unit. No real unit is defined." Vector__XXX
 SG_ ALIV_DISP_RPM_ENG_CRSH : 8|4@1+ (1,0) [0|14] "This unit fulfills the required AUTOSAR reference to a unit. No real unit is defined." Vector__XXX
 SG_ DISP_RPM_ENG_CRSH : 12|12@1+ (10,0) [0|120000] "1/min" Vector__XXX
 SG_ DISP_TARG_DRV : 24|4@1+ (1,0) [0|15] "" Vector__XXX
 SG_ DISP_GSI_DRV : 28|2@1+ (1,0) [0|3] "" Vector__XXX
 SG_ ReqDispAvailabilityDrivePower : 30|2@1+ (1,0) [0|3] "" Vector__XXX
 SG_ DISP_AVL_PWR_REL_RECUP_IGR : 32|4@1+ (10,0) [0|1000] "%" Vector__XXX
 SG_ DISP_RPM_PT_dummy_36_39 : 36|4@1+ (1,0) [-8|7] "" Vector__XXX
 SG_ DISP_GR_PT : 40|6@1+ (1,0) [0|63] "" Vector__XXX
 SG_ DISP_RPM_PT_dummy_46_47 : 46|2@1+ (1,0) [-2|1] "" Vector__XXX
 SG_ CTR_DISP_PWSPAR : 48|12@1+ (0.025,0) [0.000|2.500] "%" Vector__XXX
 SG_ DisplayMsaStatus : 60|3@1+ (1,0) [0|7] "" Vector__XXX
 SG_ DISP_RPM_PT_dummy_63_63 : 63|1@1+ (1,0) [-1|0] "" Vector__XXX

BO_ 595 DISP_SW_DRDY_S: 8 DME1
 SG_ DISP_S_ENG_TORQ : 0|8@1+ (1,0) [0|100] "%" ZGW
 SG_ DISP_S_ENG_TORQ_BS_SCAL_VL : 8|4@1+ (1,0) [0|15] "" ZGW
 SG_ DISP_S_ENG_PWR_BS_SCAL_VL : 12|4@1+ (1,0) [0|15] "" ZGW
 SG_ DISP_S_ENG_PWR : 16|8@1+ (1,0) [0|100] "%" ZGW
 SG_ DISP_MAXV_PWR : 24|12@1+ (1,0) [0|4094] "This unit fulfills the required AUTOSAR reference to a unit. No real unit is defined." ZGW
 SG_ DISP_MAXV_TORQ : 36|12@1+ (1,0) [0|4094] "This unit fulfills the required AUTOSAR reference to a unit. No real unit is defined." ZGW
 SG_ ReductionAirConPowerCompProt : 48|3@1+ (1,0) [0|7] "" ZGW

BO_TX_BU_ 1069 : Kombi,Kombi_Basis;
BO_TX_BU_ 866 : Kombi,Kombi_Basis;
BO_TX_BU_ 864 : Kombi,Kombi_Basis;
BO_TX_BU_ 862 : Kombi,Kombi_Basis;
BO_TX_BU_ 662 : CHC,ZGW;
BO_TX_BU_ 822 : Kombi,Kombi_Basis;
BO_TX_BU_ 941 : DME1,EME;
BO_TX_BU_ 868 : Kombi,Kombi_Basis;
BO_TX_BU_ 1066 : Kombi,Kombi_Basis;
BO_TX_BU_ 456 : Diagnosetool_FA_CAN,EME;
BO_TX_BU_ 934 : Kombi,Kombi_Basis;
CM_ BO_ 1942  "In dieser Nachricht werden Daten f�r den Request eines Prozesses (z.B. Authentisierung) im Rahmen des  Komponentendiebstahlschutzes (KDS) vom KDS Master an den KDS Client \"Kombi\" gesendet. Wegen der L�nge der Nachrichten wird ISO-TP (gem�� ISO 15765-2 bzw. CAN Transportprotokoll, LH 10000235; Kapitel 3.3.2.2.2) verwendet.
==========
In this message, data for the request of a process (e.g. authentication) is sent from the KDS master to the KDS client \"instrument cluster\" as part of the component theft protection (KDS). Due to the length of the messages, ISO-TP (in accordance with ISO�15765-2 or CAN transport protocol, LH 10000235; section 3.3.2.2.2) is used.";
CM_ BO_ 1943  "In dieser Nachricht werden Daten f�r den Response eines Prozesses (z.B. Authentisierung) im Rahmen des  Komponentendiebstahlschutzes (KDS) vom KDS Client \"Kombi\" an den KDS Master gesendet. Wegen der L�nge der Nachrichten wird ISO-TP (gem�� ISO 15765-2 bzw. CAN Transportprotokoll, LH 10000235; Kapitel 3.3.2.2.2) verwendet.
==========
In this message, data for the response of a process (e.g. authentication) is sent from the KDS client \"instrument cluster\" to the KDS master as part of the component theft protection (KDS). Due to the length of the messages, ISO-TP (in accordance with ISO�15765-2 or CAN transport protocol, LH 10000235; section 3.3.2.2.2) is used.";
CM_ BO_ 659  "Abgesicherte Checkcontrol Meldungen der ARS-Funktion an das Kombi Instrument.
Um eine Alive-�berwachung des Sendersteuerger�ts zu erm�glichen ist die Botschaft mit Alive-Z�hler und CRC ausgestattet.
Die Funktionsidentifikation \"ARS\" entspricht der Senderfunktion \"Aktive Roll�berwachung\".
Soll eine CC Meldung auf dem zyklischen Kanal versendet werden, so wird die entsprechende CC ID als NO_CC_ARS, mit dem Wert \"Setzen\" als ST_CC_ARS und mit einer im Signal TRANF_CC_ARS festgelegten \"Wiederholrate\" in Sekunden versendet. Die folgenden Botschaften bis zum Ablauf der als \"Wiederholrate\" festgelegten Zeitspanne werden mit dem Wert \"0xFFFE\" als NO_CC_ARS und dem Wert \"R�cksetzen\" als ST_CC_ARS versendet.
==========
Validated Check Control messages of the ARS function to the instrument cluster.
To enable Alive monitoring of the electronic sender ECU, the message is equipped with an Alive counter and a CRC.
The function identification \"ARS\" corresponds to the sender function \"active rolling monitoring\".
If a CC message is to be sent on the cyclical channel, the corresponding CC ID shall be sent as NO_CC_ARS, with the value \"Setzen\" as ST_CC_ARS and with a \"repetition rate\" defined in seconds in the signal TRANF_CC_ARS. The following messages up to the end of the time period defined as \"repetition rate\" shall be sent with the value \"0xFFFE\" as NO_CC_ARS and the value \"R�cksetzen\" as ST_CC_ARS.";
CM_ BO_ 662  "Abgesicherte Checkcontrol Meldungen der EHC-Funktion an das Kombi Instrument.
Um eine Alive-�berwachung des Sendersteuerger�ts zu erm�glichen ist die Botschaft mit Alive-Z�hler und CRC ausgestattet.
Die Funktionsidentifikation \"EHC\" entspricht der Senderfunktion \"Luftfeder\".
Soll eine CC Meldung auf dem zyklischen Kanal versendet werden, so wird die entsprechende CC ID als NO_CC_EHC, mit dem Wert \"Setzen\" als ST_CC_EHC und mit einer im Signal TRANF_CC_EHC festgelegten \"Wiederholrate\" in Sekunden versendet. Die folgenden Botschaften bis zum Ablauf der als \"Wiederholrate\" festgelegten Zeitspanne werden mit dem Wert \"0xFFFE\" als NO_CC_EHC und dem Wert \"R�cksetzen\" als ST_CC_EHC versendet.
Bei verbautem CHC wird die Botschaft ausschlie�lich vom CHC versendet.
==========
Validated Check Control messages of the EHC function to the instrument cluster.
To enable Alive monitoring of the electronic sender ECU, the message is equipped with an Alive counter and a CRC.
The function identification \"EHC\" corresponds to the sender function \"air spring\".
If a CC message is to be sent on the cyclical channel, the corresponding CC ID shall be sent as NO_CC_EHC, with the value \"Setzen\" as ST_CC_EHC and with a \"repetition rate\" defined in seconds in the signal TRANF_CC_EHC. The following messages up to the end of the time period defined as \"repetition rate\" are sent with the value \"0xFFFE\" as NO_CC_EHC and the value \"R�cksetzen\" as ST_CC_EHC.
If a CHC is installed, the message is exclusively sent by the CHC.";
CM_ BO_ 660  "Abgesicherte Checkcontrol Meldungen der EPS-Funktion an das Kombi Instrument.
Um eine Alive-�berwachung des Sendersteuerger�ts zu erm�glichen ist die Botschaft mit Alive-Z�hler und CRC ausgestattet.
Die Funktionsidentifikation \"EPS\" entspricht der Senderfunktion \"Elektrische Lenkung Vorderachse\".
Soll eine CC Meldung auf dem zyklischen Kanal versendet werden, so wird die entsprechende CC ID als NO_CC_EPS, mit dem Wert \"Setzen\" als ST_CC_EPS und mit einer im Signal TRANF_CC_EPS festgelegten \"Wiederholrate\" in Sekunden versendet. Die folgenden Botschaften bis zum Ablauf der als \"Wiederholrate\" festgelegten Zeitspanne werden mit dem Wert \"0xFFFE\" als NO_CC_EPS und dem Wert \"R�cksetzen\" als ST_CC_EPS versendet.
==========
Validated Check Control messages of the EPS function to the instrument cluster.
To enable Alive monitoring of the electronic sender ECU, the message is equipped with an Alive counter and a CRC.
The function identification \"EPS\" corresponds to the sender function \"electrical front axle steering\".
If a CC message is to be sent on the cyclical channel, the corresponding CC ID shall be sent as NO_CC_EPS, with the value \"Setzen\" as ST_CC_EPS and with a \"repetition rate\" defined in seconds in the signal TRANF_CC_EPS. The following messages up to the end of the time period defined as \"repetition rate\" are sent with the value \"0xFFFE\" as NO_CC_EPS and the value \"R�cksetzen\" as ST_CC_EPS.";
CM_ BO_ 654  "Abgesicherte Checkcontrol Meldungen der VDC-Funktion an das Kombi Instrument.
Um eine Alive-�berwachung des Sendersteuerger�ts zu erm�glichen ist die Botschaft mit Alive-Z�hler und CRC ausgestattet.
Die Funktionsidentifikation \"VDC\" entspricht der Senderfunktion \"Verstelld�mpfung\".
Soll eine CC Meldung auf dem zyklischen Kanal versendet werden, so wird die entsprechende CC ID als NO_CC_VDC, mit dem Wert \"Setzen\" als ST_CC_VDC und mit einer im Signal TRANF_CC_VDC festgelegten \"Wiederholrate\" in Sekunden versendet. Die folgenden Botschaften bis zum Ablauf der als \"Wiederholrate\" festgelegten Zeitspanne werden mit dem Wert \"0xFFFE\" als NO_CC_VDC und dem Wert \"R�cksetzen\" als ST_CC_VDC versendet.
==========
Validated Check Control messages of the VDC function to the instrument cluster.
To enable Alive monitoring of the electronic sender ECU, the message is equipped with an Alive counter and a CRC.
The function identification \"VDC\" corresponds to the sender function \"adjustable damping\".
If a CC message is to be sent on the cyclical channel, the corresponding CC ID shall be sent as NO_CC_VDC, with the value \"Setzen\" as ST_CC_VDC and with a \"repetition rate\" defined in seconds in the signal TRANF_CC_VDC. The following messages up to the end of the time period defined as \"repetition rate\" are sent with the value \"0xFFFE\" as NO_CC_VDC and the value \"R�cksetzen\" as ST_CC_VDC.";

BA_DEF_ BO_ "FrameTriggeringName" STRING;
BA_DEF_ BO_ "GenMsgCycleTime" INT 0 65535;
BA_DEF_ BO_ "GenMsgDelayTime" INT 0 65535;
BA_DEF_ BO_ "GenMsgSendType" ENUM  "cyclicX","spontanX","cyclicIfActiveX","spontanWithDelay","cyclicAndSpontanX","cyclicAndSpontanWithDelay","spontanWithRepitition","cyclicIfActiveAndSpontanWD","cyclicIfActiveFast","cyclicWithRepeatOnDemand","none";
BA_DEF_ BO_ "GenMsgStartValue" STRING;
BA_DEF_ BO_ "PduName" STRING;
BA_DEF_ BO_ "SystemMessageLongSymbol" STRING;
BA_DEF_ SG_ "CompuMethodName" STRING;
BA_DEF_ SG_ "GenSigStartValue" FLOAT 0 100000000000;
BA_DEF_ SG_ "ISignalName" STRING;
BA_DEF_ SG_ "LongName" STRING;
BA_DEF_ SG_ "SysSignalName" STRING;
BA_DEF_ SG_ "SystemSignalLongSymbol" STRING;
BA_ "FrameTriggeringName" BO_ 672 "frTrig_CAN_963411816_672_963402584_963411732_963424759_FA_CAN";
BA_ "GenMsgCycleTime" BO_ 672 5000;
BA_ "GenMsgDelayTime" BO_ 672 100;
BA_ "GenMsgSendType" BO_ 672 4;
BA_ "GenMsgStartValue" BO_ 672 "0000000000000000";
BA_ "PduName" BO_ 672 "CTR_ZV";
BA_ "FrameTriggeringName" BO_ 1942 "frTrig_CAN_963412122_1942_963405643_963411732_963424759_FA_CAN";
BA_ "GenMsgSendType" BO_ 1942 1;
BA_ "GenMsgStartValue" BO_ 1942 "0000000000000000";
BA_ "PduName" BO_ 1942 "ComponentTheftProtectionRequestKombi";
BA_ "SystemMessageLongSymbol" BO_ 1942 "ComponentTheftProtectionRequestKombi";
BA_ "FrameTriggeringName" BO_ 1943 "frTrig_CAN_963412123_1943_963405852_963411732_963424759_FA_CAN";
BA_ "GenMsgSendType" BO_ 1943 1;
BA_ "GenMsgStartValue" BO_ 1943 "0000000000000000";
BA_ "PduName" BO_ 1943 "ComponentTheftProtectionResponseKombi";
BA_ "SystemMessageLongSymbol" BO_ 1943 "ComponentTheftProtectionResponseKombi";
BA_ "FrameTriggeringName" BO_ 1069 "frTrig_CAN_963411850_1069_963394174_963411732_963424759_FA_CAN";
BA_ "GenMsgCycleTime" BO_ 1069 5000;
BA_ "GenMsgDelayTime" BO_ 1069 200;
BA_ "GenMsgSendType" BO_ 1069 4;
BA_ "GenMsgStartValue" BO_ 1069 "0000000000000000";
BA_ "PduName" BO_ 1069 "ConfigurationHUD2";
BA_ "FrameTriggeringName" BO_ 622 "frTrig_CAN_963411735_622_963405591_963411732_963424759_FA_CAN";
BA_ "GenMsgDelayTime" BO_ 622 100;
BA_ "GenMsgSendType" BO_ 622 1;
BA_ "GenMsgStartValue" BO_ 622 "0000";
BA_ "PduName" BO_ 622 "ConfigurationSChargeRemoteCommand";
BA_ "SystemMessageLongSymbol" BO_ 622 "ConfigurationSChargeRemoteCommand";
BA_ "FrameTriggeringName" BO_ 439 "frTrig_CAN_963411912_439_963396274_963411732_963424759_FA_CAN";
BA_ "GenMsgDelayTime" BO_ 439 40;
BA_ "GenMsgSendType" BO_ 439 1;
BA_ "GenMsgStartValue" BO_ 439 "0000000000000000";
BA_ "PduName" BO_ 439 "ControlDisplayDrift";
BA_ "FrameTriggeringName" BO_ 866 "frTrig_CAN_963411968_866_963389478_963411732_963424759_FA_CAN";
BA_ "GenMsgCycleTime" BO_ 866 5000;
BA_ "GenMsgDelayTime" BO_ 866 200;
BA_ "GenMsgSendType" BO_ 866 4;
BA_ "GenMsgStartValue" BO_ 866 "00000000000000";
BA_ "PduName" BO_ 866 "DATA_BC_DURCHSCHNITTSWERTE";
BA_ "FrameTriggeringName" BO_ 864 "frTrig_CAN_963412058_864_963403282_963411732_963424759_FA_CAN";
BA_ "GenMsgCycleTime" BO_ 864 5000;
BA_ "GenMsgDelayTime" BO_ 864 200;
BA_ "GenMsgSendType" BO_ 864 4;
BA_ "GenMsgStartValue" BO_ 864 "00000001100000";
BA_ "PduName" BO_ 864 "DATA_BC_FAHRTBEGINN";
BA_ "FrameTriggeringName" BO_ 862 "frTrig_CAN_963411844_862_963398903_963411732_963424759_FA_CAN";
BA_ "GenMsgCycleTime" BO_ 862 5000;
BA_ "GenMsgDelayTime" BO_ 862 200;
BA_ "GenMsgSendType" BO_ 862 4;
BA_ "GenMsgStartValue" BO_ 862 "0000000000000000";
BA_ "PduName" BO_ 862 "DATA_BC_REISEDATEN";
BA_ "FrameTriggeringName" BO_ 824 "frTrig_CAN_963411751_824_963401066_963411732_963424759_FA_CAN";
BA_ "GenMsgCycleTime" BO_ 824 5000;
BA_ "GenMsgDelayTime" BO_ 824 50;
BA_ "GenMsgSendType" BO_ 824 4;
BA_ "GenMsgStartValue" BO_ 824 "0000000000000000";
BA_ "PduName" BO_ 824 "DCTR_CC_MESS";
BA_ "FrameTriggeringName" BO_ 1022 "frTrig_CAN_963411871_1022_963403235_963411732_963424759_FA_CAN";
BA_ "GenMsgDelayTime" BO_ 1022 200;
BA_ "GenMsgSendType" BO_ 1022 1;
BA_ "GenMsgStartValue" BO_ 1022 "0000000000000000";
BA_ "PduName" BO_ 1022 "DCTR_EOI_1";
BA_ "FrameTriggeringName" BO_ 1023 "frTrig_CAN_963411961_1023_963401187_963411732_963424759_FA_CAN";
BA_ "GenMsgDelayTime" BO_ 1023 200;
BA_ "GenMsgSendType" BO_ 1023 1;
BA_ "GenMsgStartValue" BO_ 1023 "0000000000000000";
BA_ "PduName" BO_ 1023 "DCTR_EOI_2";
BA_ "FrameTriggeringName" BO_ 1024 "frTrig_CAN_963412017_1024_963403421_963411732_963424759_FA_CAN";
BA_ "GenMsgDelayTime" BO_ 1024 200;
BA_ "GenMsgSendType" BO_ 1024 1;
BA_ "GenMsgStartValue" BO_ 1024 "0000000000000000";
BA_ "PduName" BO_ 1024 "DCTR_EOI_3";
BA_ "FrameTriggeringName" BO_ 1025 "frTrig_CAN_963412107_1025_963399094_963411732_963424759_FA_CAN";
BA_ "GenMsgDelayTime" BO_ 1025 200;
BA_ "GenMsgSendType" BO_ 1025 1;
BA_ "GenMsgStartValue" BO_ 1025 "00000000000000f3";
BA_ "PduName" BO_ 1025 "DCTR_EOI_4";
BA_ "FrameTriggeringName" BO_ 919 "frTrig_CAN_963412060_919_963402552_963411732_963424759_FA_CAN";
BA_ "GenMsgCycleTime" BO_ 919 1000;
BA_ "GenMsgDelayTime" BO_ 919 50;
BA_ "GenMsgSendType" BO_ 919 4;
BA_ "GenMsgStartValue" BO_ 919 "00000000000000";
BA_ "PduName" BO_ 919 "DIAG_OBD_ENG";
BA_ "FrameTriggeringName" BO_ 1000 "frTrig_CAN_963411738_1000_963396469_963411732_963424759_FA_CAN";
BA_ "GenMsgCycleTime" BO_ 1000 1000;
BA_ "GenMsgDelayTime" BO_ 1000 50;
BA_ "GenMsgSendType" BO_ 1000 4;
BA_ "GenMsgStartValue" BO_ 1000 "0000";
BA_ "PduName" BO_ 1000 "DIAG_OBD_ENGMG_EL";
BA_ "FrameTriggeringName" BO_ 514 "frTrig_CAN_963411807_514_963393591_963411732_963424759_FA_CAN";
BA_ "GenMsgCycleTime" BO_ 514 5000;
BA_ "GenMsgDelayTime" BO_ 514 50;
BA_ "GenMsgSendType" BO_ 514 4;
BA_ "GenMsgStartValue" BO_ 514 "0000";
BA_ "PduName" BO_ 514 "DIMMUNG";
BA_ "FrameTriggeringName" BO_ 659 "frTrig_CAN_963412100_659_963396246_963411732_963424759_FA_CAN";
BA_ "GenMsgCycleTime" BO_ 659 320;
BA_ "GenMsgDelayTime" BO_ 659 60;
BA_ "GenMsgSendType" BO_ 659 4;
BA_ "GenMsgStartValue" BO_ 659 "0000000000";
BA_ "PduName" BO_ 659 "DISP_CC_ARS";
BA_ "FrameTriggeringName" BO_ 878 "frTrig_CAN_963412024_878_963402954_963411732_963424759_FA_CAN";
BA_ "GenMsgCycleTime" BO_ 878 160;
BA_ "GenMsgSendType" BO_ 878 0;
BA_ "GenMsgStartValue" BO_ 878 "0080000000";
BA_ "PduName" BO_ 878 "DISP_CC_BYPA_00";
BA_ "FrameTriggeringName" BO_ 879 "frTrig_CAN_963411772_879_963393894_963411732_963424759_FA_CAN";
BA_ "GenMsgCycleTime" BO_ 879 160;
BA_ "GenMsgSendType" BO_ 879 0;
BA_ "GenMsgStartValue" BO_ 879 "0080000000";
BA_ "PduName" BO_ 879 "DISP_CC_BYPA_01";
BA_ "FrameTriggeringName" BO_ 809 "frTrig_CAN_963412152_809_963395938_963411732_963424759_FA_CAN";
BA_ "GenMsgCycleTime" BO_ 809 300;
BA_ "GenMsgSendType" BO_ 809 0;
BA_ "GenMsgStartValue" BO_ 809 "0080000004";
BA_ "PduName" BO_ 809 "DISP_CC_BYPA_02";
BA_ "FrameTriggeringName" BO_ 827 "frTrig_CAN_963412115_827_963391964_963411732_963424759_FA_CAN";
BA_ "GenMsgCycleTime" BO_ 827 300;
BA_ "GenMsgSendType" BO_ 827 0;
BA_ "GenMsgStartValue" BO_ 827 "0080000004";
BA_ "PduName" BO_ 827 "DISP_CC_BYPA_02";
BA_ "FrameTriggeringName" BO_ 936 "frTrig_CAN_963412053_936_963400661_963411732_963424759_FA_CAN";
BA_ "GenMsgCycleTime" BO_ 936 1000;
BA_ "GenMsgDelayTime" BO_ 936 100;
BA_ "GenMsgSendType" BO_ 936 4;
BA_ "GenMsgStartValue" BO_ 936 "0000000004";
BA_ "PduName" BO_ 936 "DISP_CC_BYPA_03";
BA_ "FrameTriggeringName" BO_ 793 "frTrig_CAN_963412113_793_963396704_963411732_963424759_FA_CAN";
BA_ "GenMsgCycleTime" BO_ 793 5000;
BA_ "GenMsgDelayTime" BO_ 793 300;
BA_ "GenMsgSendType" BO_ 793 4;
BA_ "GenMsgStartValue" BO_ 793 "0000000000";
BA_ "PduName" BO_ 793 "DISP_CC_CFCT";
BA_ "FrameTriggeringName" BO_ 404 "frTrig_CAN_963411783_404_963396480_963411732_963424759_FA_CAN";
BA_ "GenMsgCycleTime" BO_ 404 2000;
BA_ "GenMsgDelayTime" BO_ 404 50;
BA_ "GenMsgSendType" BO_ 404 4;
BA_ "GenMsgStartValue" BO_ 404 "0000000000";
BA_ "PduName" BO_ 404 "DISP_CC_DFNS";
BA_ "FrameTriggeringName" BO_ 781 "frTrig_CAN_963411862_781_963398518_963411732_963424759_FA_CAN";
BA_ "GenMsgCycleTime" BO_ 781 160;
BA_ "GenMsgSendType" BO_ 781 0;
BA_ "GenMsgStartValue" BO_ 781 "0080000004";
BA_ "PduName" BO_ 781 "DISP_CC_DRASY";
BA_ "FrameTriggeringName" BO_ 679 "frTrig_CAN_963411849_679_963402928_963411732_963424759_FA_CAN";
BA_ "GenMsgCycleTime" BO_ 679 80;
BA_ "GenMsgSendType" BO_ 679 0;
BA_ "GenMsgStartValue" BO_ 679 "0080000000";
BA_ "PduName" BO_ 679 "DISP_CC_DRDY_COOTD";
BA_ "FrameTriggeringName" BO_ 662 "frTrig_CAN_963412129_662_963389133_963411732_963424759_FA_CAN";
BA_ "GenMsgCycleTime" BO_ 662 320;
BA_ "GenMsgDelayTime" BO_ 662 60;
BA_ "GenMsgSendType" BO_ 662 4;
BA_ "GenMsgStartValue" BO_ 662 "0000000000";
BA_ "PduName" BO_ 662 "DISP_CC_EHC";
BA_ "FrameTriggeringName" BO_ 660 "frTrig_CAN_963411992_660_963389085_963411732_963424759_FA_CAN";
BA_ "GenMsgCycleTime" BO_ 660 320;
BA_ "GenMsgDelayTime" BO_ 660 60;
BA_ "GenMsgSendType" BO_ 660 4;
BA_ "GenMsgStartValue" BO_ 660 "0000000000";
BA_ "PduName" BO_ 660 "DISP_CC_EPS";
BA_ "FrameTriggeringName" BO_ 416 "frTrig_CAN_963412125_416_963389578_963411732_963424759_FA_CAN";
BA_ "GenMsgCycleTime" BO_ 416 2000;
BA_ "GenMsgDelayTime" BO_ 416 50;
BA_ "GenMsgSendType" BO_ 416 4;
BA_ "GenMsgStartValue" BO_ 416 "0000000000";
BA_ "PduName" BO_ 416 "DISP_CC_GRB";
BA_ "FrameTriggeringName" BO_ 661 "frTrig_CAN_963411914_661_963398940_963411732_963424759_FA_CAN";
BA_ "GenMsgCycleTime" BO_ 661 1000;
BA_ "GenMsgDelayTime" BO_ 661 100;
BA_ "GenMsgSendType" BO_ 661 4;
BA_ "GenMsgStartValue" BO_ 661 "0000000000000080";
BA_ "PduName" BO_ 661 "DISP_CC_HVS";
BA_ "FrameTriggeringName" BO_ 822 "frTrig_CAN_963412031_822_963403278_963411732_963424759_FA_CAN";
BA_ "GenMsgDelayTime" BO_ 822 50;
BA_ "GenMsgSendType" BO_ 822 1;
BA_ "GenMsgStartValue" BO_ 822 "00000000000000";
BA_ "PduName" BO_ 822 "DISP_CC_MESS_SCR";
BA_ "FrameTriggeringName" BO_ 780 "frTrig_CAN_963412005_780_963393862_963411732_963424759_FA_CAN";
BA_ "GenMsgCycleTime" BO_ 780 160;
BA_ "GenMsgSendType" BO_ 780 0;
BA_ "GenMsgStartValue" BO_ 780 "0080000004";
BA_ "PduName" BO_ 780 "DISP_CC_PMA";
BA_ "FrameTriggeringName" BO_ 654 "frTrig_CAN_963411870_654_963402870_963411732_963424759_FA_CAN";
BA_ "GenMsgCycleTime" BO_ 654 320;
BA_ "GenMsgDelayTime" BO_ 654 60;
BA_ "GenMsgSendType" BO_ 654 4;
BA_ "GenMsgStartValue" BO_ 654 "0000000000";
BA_ "PduName" BO_ 654 "DISP_CC_VDC";
BA_ "FrameTriggeringName" BO_ 728 "frTrig_CAN_963411948_728_963401085_963411732_963424759_FA_CAN";
BA_ "GenMsgCycleTime" BO_ 728 1000;
BA_ "GenMsgDelayTime" BO_ 728 100;
BA_ "GenMsgSendType" BO_ 728 4;
BA_ "GenMsgStartValue" BO_ 728 "0000000000000000";
BA_ "PduName" BO_ 728 "DISP_CHGNG_I_LIM_2";
BA_ "FrameTriggeringName" BO_ 941 "frTrig_CAN_963411748_941_963389405_963411732_963424759_FA_CAN";
BA_ "GenMsgCycleTime" BO_ 941 1000;
BA_ "GenMsgDelayTime" BO_ 941 50;
BA_ "GenMsgSendType" BO_ 941 4;
BA_ "GenMsgStartValue" BO_ 941 "0000000000000000";
BA_ "PduName" BO_ 941 "DISP_CON_HYB";
BA_ "FrameTriggeringName" BO_ 1036 "frTrig_CAN_963411864_1036_963394178_963411732_963424759_FA_CAN";
BA_ "GenMsgCycleTime" BO_ 1036 1000;
BA_ "GenMsgSendType" BO_ 1036 0;
BA_ "GenMsgStartValue" BO_ 1036 "0000000000";
BA_ "PduName" BO_ 1036 "DISP_COSA_HYB";
BA_ "FrameTriggeringName" BO_ 796 "frTrig_CAN_963411910_796_963399064_963411732_963424759_FA_CAN";
BA_ "GenMsgCycleTime" BO_ 796 200;
BA_ "GenMsgDelayTime" BO_ 796 60;
BA_ "GenMsgSendType" BO_ 796 4;
BA_ "GenMsgStartValue" BO_ 796 "0020008000000080";
BA_ "PduName" BO_ 796 "DISP_DRASY";
BA_ "FrameTriggeringName" BO_ 515 "frTrig_CAN_963411954_515_963394236_963411732_963424759_FA_CAN";
BA_ "GenMsgCycleTime" BO_ 515 200;
BA_ "GenMsgDelayTime" BO_ 515 40;
BA_ "GenMsgSendType" BO_ 515 4;
BA_ "GenMsgStartValue" BO_ 515 "0000000000000080";
BA_ "PduName" BO_ 515 "DISP_DRASY_LAG";
BA_ "FrameTriggeringName" BO_ 541 "frTrig_CAN_963411887_541_963399050_963411732_963424759_FA_CAN";
BA_ "GenMsgCycleTime" BO_ 541 200;
BA_ "GenMsgDelayTime" BO_ 541 40;
BA_ "GenMsgSendType" BO_ 541 4;
BA_ "GenMsgStartValue" BO_ 541 "0000000000000000";
BA_ "PduName" BO_ 541 "DISP_DRASY_LAG_2";
BA_ "FrameTriggeringName" BO_ 451 "frTrig_CAN_963411741_451_963389402_963411732_963424759_FA_CAN";
BA_ "GenMsgCycleTime" BO_ 451 200;
BA_ "GenMsgDelayTime" BO_ 451 40;
BA_ "GenMsgSendType" BO_ 451 4;
BA_ "GenMsgStartValue" BO_ 451 "0000000000000000";
BA_ "PduName" BO_ 451 "DISP_DRASY_LNG";
BA_ "FrameTriggeringName" BO_ 477 "frTrig_CAN_963411899_477_963399057_963411732_963424759_FA_CAN";
BA_ "GenMsgCycleTime" BO_ 477 200;
BA_ "GenMsgDelayTime" BO_ 477 40;
BA_ "GenMsgSendType" BO_ 477 4;
BA_ "GenMsgStartValue" BO_ 477 "0100000000000000";
BA_ "PduName" BO_ 477 "DISP_DRASY_LNG_2";
BA_ "FrameTriggeringName" BO_ 479 "frTrig_CAN_963411965_479_963398546_963411732_963424759_FA_CAN";
BA_ "GenMsgCycleTime" BO_ 479 1000;
BA_ "GenMsgDelayTime" BO_ 479 40;
BA_ "GenMsgSendType" BO_ 479 4;
BA_ "GenMsgStartValue" BO_ 479 "000000001e000000";
BA_ "PduName" BO_ 479 "DISP_DRASY_MOD";
BA_ "FrameTriggeringName" BO_ 868 "frTrig_CAN_963412099_868_963396700_963411732_963424759_FA_CAN";
BA_ "GenMsgDelayTime" BO_ 868 500;
BA_ "GenMsgSendType" BO_ 868 1;
BA_ "GenMsgStartValue" BO_ 868 "0000000000";
BA_ "PduName" BO_ 868 "DISP_DRVBH";
BA_ "FrameTriggeringName" BO_ 1066 "frTrig_CAN_963412030_1066_963403253_963411732_963424759_FA_CAN";
BA_ "GenMsgDelayTime" BO_ 1066 100;
BA_ "GenMsgSendType" BO_ 1066 1;
BA_ "GenMsgStartValue" BO_ 1066 "0000000000";
BA_ "PduName" BO_ 1066 "DISP_DRVBH_2";
BA_ "FrameTriggeringName" BO_ 456 "frTrig_CAN_963411855_456_963394051_963411732_963424759_FA_CAN";
BA_ "GenMsgCycleTime" BO_ 456 200;
BA_ "GenMsgDelayTime" BO_ 456 40;
BA_ "GenMsgSendType" BO_ 456 4;
BA_ "GenMsgStartValue" BO_ 456 "0000000000000000";
BA_ "PduName" BO_ 456 "DISP_DT_HVSTO";
BA_ "FrameTriggeringName" BO_ 893 "frTrig_CAN_963411925_893_963389275_963411732_963424759_FA_CAN";
BA_ "GenMsgCycleTime" BO_ 893 5000;
BA_ "GenMsgDelayTime" BO_ 893 500;
BA_ "GenMsgSendType" BO_ 893 4;
BA_ "GenMsgStartValue" BO_ 893 "0000000000";
BA_ "PduName" BO_ 893 "DISP_DT_SCR";
BA_ "FrameTriggeringName" BO_ 929 "frTrig_CAN_963412173_929_963398933_963411732_963424759_FA_CAN";
BA_ "GenMsgCycleTime" BO_ 929 200;
BA_ "GenMsgDelayTime" BO_ 929 20;
BA_ "GenMsgSendType" BO_ 929 4;
BA_ "GenMsgStartValue" BO_ 929 "00000078781e0000";
BA_ "PduName" BO_ 929 "DISP_FAS_MNV";
BA_ "FrameTriggeringName" BO_ 630 "frTrig_CAN_963412174_630_963405861_963411732_963424759_FA_CAN";
BA_ "GenMsgCycleTime" BO_ 630 200;
BA_ "GenMsgDelayTime" BO_ 630 20;
BA_ "GenMsgSendType" BO_ 630 4;
BA_ "GenMsgStartValue" BO_ 630 "0000000000000000";
BA_ "PduName" BO_ 630 "DISP_FAS_PKG";
BA_ "FrameTriggeringName" BO_ 748 "frTrig_CAN_963411974_748_963391630_963411732_963424759_FA_CAN";
BA_ "GenMsgCycleTime" BO_ 748 1000;
BA_ "GenMsgDelayTime" BO_ 748 40;
BA_ "GenMsgSendType" BO_ 748 4;
BA_ "GenMsgStartValue" BO_ 748 "0000000000000000";
BA_ "PduName" BO_ 748 "DISP_FRSG";
BA_ "FrameTriggeringName" BO_ 755 "frTrig_CAN_963412004_755_963389571_963411732_963424759_FA_CAN";
BA_ "GenMsgCycleTime" BO_ 755 1000;
BA_ "GenMsgDelayTime" BO_ 755 40;
BA_ "GenMsgSendType" BO_ 755 4;
BA_ "GenMsgStartValue" BO_ 755 "0100000000000000";
BA_ "PduName" BO_ 755 "DISP_FRSG_2";
BA_ "FrameTriggeringName" BO_ 686 "frTrig_CAN_963411771_686_963394165_963411732_963424759_FA_CAN";
BA_ "GenMsgCycleTime" BO_ 686 20;
BA_ "GenMsgSendType" BO_ 686 0;
BA_ "GenMsgStartValue" BO_ 686 "000000009c4f6400";
BA_ "PduName" BO_ 686 "DISP_PWR_DRV";
BA_ "FrameTriggeringName" BO_ 934 "frTrig_CAN_963411861_934_963396513_963411732_963424759_FA_CAN";
BA_ "GenMsgDelayTime" BO_ 934 500;
BA_ "GenMsgSendType" BO_ 934 1;
BA_ "GenMsgStartValue" BO_ 934 "0000000000000000";
BA_ "PduName" BO_ 934 "DISP_REPAT_EL_PWR";
BA_ "FrameTriggeringName" BO_ 243 "frTrig_CAN_963411874_243_963398943_963411732_963424759_FA_CAN";
BA_ "GenMsgCycleTime" BO_ 243 20;
BA_ "GenMsgSendType" BO_ 243 0;
BA_ "GenMsgStartValue" BO_ 243 "0000000080800080";
BA_ "PduName" BO_ 243 "DISP_RPM_PT";
BA_ "FrameTriggeringName" BO_ 595 "frTrig_CAN_963412140_595_963405687_963411732_963424759_FA_CAN";
BA_ "GenMsgCycleTime" BO_ 595 100;
BA_ "GenMsgSendType" BO_ 595 0;
BA_ "GenMsgStartValue" BO_ 595 "0000000000000000";
BA_ "PduName" BO_ 595 "DISP_SW_DRDY_S";
BA_ "CompuMethodName" SG_ 672 CTR_CLSY_DRD "ENUM_4_noIniVal_noDflVal_15_noQuant_noOffs_typeBitField_noRng_24";
BA_ "ISignalName" SG_ 672 CTR_CLSY_DRD "CTR_CLSY_DRD";
BA_ "LongName" SG_ 672 CTR_CLSY_DRD "Steuerung_Zentralverriegelung_FAT";
BA_ "SysSignalName" SG_ 672 CTR_CLSY_DRD "CTR_CLSY_DRD";
BA_ "CompuMethodName" SG_ 672 CTR_CLSY_BTL "CTR_CLSY_BTL";
BA_ "ISignalName" SG_ 672 CTR_CLSY_BTL "CTR_CLSY_BTL";
BA_ "LongName" SG_ 672 CTR_CLSY_BTL "Steuerung_Zentralverriegelung_Heckklappe";
BA_ "SysSignalName" SG_ 672 CTR_CLSY_BTL "CTR_CLSY_BTL";
BA_ "CompuMethodName" SG_ 1069 ListEntryAdditionalDisplayHUD "ListEntryAdditionalDisplayHUD";
BA_ "ISignalName" SG_ 1069 ListEntryAdditionalDisplayHUD "ListEntryAdditionalDisplayHUD";
BA_ "LongName" SG_ 1069 ListEntryAdditionalDisplayHUD "ListEntryAdditionalDisplayHUD";
BA_ "SysSignalName" SG_ 1069 ListEntryAdditionalDisplayHUD "ListEntryAdditionalDisplayHUD";
BA_ "CompuMethodName" SG_ 622 OperationChargeControlPlugRemote "OperationChargeControlPlugRemote";
BA_ "ISignalName" SG_ 622 OperationChargeControlPlugRemote "OperationChargeControlPlugRemote";
BA_ "LongName" SG_ 622 OperationChargeControlPlugRemote "OperationChargeControlPlugRemote";
BA_ "SysSignalName" SG_ 622 OperationChargeControlPlugRemote "OperationChargeControlPlugRemote";
BA_ "CompuMethodName" SG_ 439 ControlDriftAssistLampFrequency "ControlDriftAssistLampFrequency";
BA_ "ISignalName" SG_ 439 ControlDriftAssistLampFrequency "ControlDriftAssistLampFrequency";
BA_ "LongName" SG_ 439 ControlDriftAssistLampFrequency "ControlDriftAssistLampFrequency";
BA_ "SysSignalName" SG_ 439 ControlDriftAssistLampFrequency "ControlDriftAssistLampFrequency";
BA_ "CompuMethodName" SG_ 439 ControlDriftAssist "ControlDriftAssist";
BA_ "ISignalName" SG_ 439 ControlDriftAssist "ControlDriftAssist";
BA_ "LongName" SG_ 439 ControlDriftAssist "ControlDriftAssist";
BA_ "SysSignalName" SG_ 439 ControlDriftAssist "ControlDriftAssist";
BA_ "CompuMethodName" SG_ 866 V_AVR_1_BC_1 "V_AVR_1_BC_1";
BA_ "ISignalName" SG_ 866 V_AVR_1_BC_1 "V_AVR_1_BC_1";
BA_ "LongName" SG_ 866 V_AVR_1_BC_1 "Geschwindigkeit_Durchschnitt_1_BC_1";
BA_ "SysSignalName" SG_ 866 V_AVR_1_BC_1 "V_AVR_1_BC_1";
BA_ "CompuMethodName" SG_ 866 COSP_AVR_1_BC_1 "COSP_AVR_1_BC_1";
BA_ "ISignalName" SG_ 866 COSP_AVR_1_BC_1 "COSP_AVR_1_BC_1";
BA_ "LongName" SG_ 866 COSP_AVR_1_BC_1 "Verbrauch_Durchschnitt_1_BC_1";
BA_ "SysSignalName" SG_ 866 COSP_AVR_1_BC_1 "COSP_AVR_1_BC_1";
BA_ "CompuMethodName" SG_ 866 V_AVR_2_BC_2 "V_AVR_2_BC_2";
BA_ "ISignalName" SG_ 866 V_AVR_2_BC_2 "V_AVR_2_BC_2";
BA_ "LongName" SG_ 866 V_AVR_2_BC_2 "Geschwindigkeit_Durchschnitt_2_BC_2";
BA_ "SysSignalName" SG_ 866 V_AVR_2_BC_2 "V_AVR_2_BC_2";
BA_ "CompuMethodName" SG_ 866 COSP_AVR_2_BC_2 "COSP_AVR_2_BC_2";
BA_ "ISignalName" SG_ 866 COSP_AVR_2_BC_2 "COSP_AVR_2_BC_2";
BA_ "LongName" SG_ 866 COSP_AVR_2_BC_2 "Verbrauch_Durchschnitt_2_BC_2";
BA_ "SysSignalName" SG_ 866 COSP_AVR_2_BC_2 "COSP_AVR_2_BC_2";
BA_ "CompuMethodName" SG_ 866 ST_UN_V_BC "ST_UN_V_BC";
BA_ "ISignalName" SG_ 866 ST_UN_V_BC "ST_UN_V_BC";
BA_ "LongName" SG_ 866 ST_UN_V_BC "status_unit-of-measurement_speed_BC";
BA_ "SysSignalName" SG_ 866 ST_UN_V_BC "ST_UN_V_BC";
BA_ "CompuMethodName" SG_ 866 ST_UN_COSP_BC "ST_UN_COSP_BC";
BA_ "ISignalName" SG_ 866 ST_UN_COSP_BC "ST_UN_COSP_BC";
BA_ "LongName" SG_ 866 ST_UN_COSP_BC "Status_Einheit_Verbrauch_BC";
BA_ "SysSignalName" SG_ 866 ST_UN_COSP_BC "ST_UN_COSP_BC";
BA_ "CompuMethodName" SG_ 864 HR_DPRT_BC "HR_DPRT_BC";
BA_ "ISignalName" SG_ 864 HR_DPRT_BC "HR_DPRT_BC";
BA_ "LongName" SG_ 864 HR_DPRT_BC "Stunde_Abfahrt_BC";
BA_ "SysSignalName" SG_ 864 HR_DPRT_BC "HR_DPRT_BC";
BA_ "CompuMethodName" SG_ 864 MN_DPRT_BC "MN_DPRT_BC";
BA_ "ISignalName" SG_ 864 MN_DPRT_BC "MN_DPRT_BC";
BA_ "LongName" SG_ 864 MN_DPRT_BC "minute_departure_BC";
BA_ "SysSignalName" SG_ 864 MN_DPRT_BC "MN_DPRT_BC";
BA_ "CompuMethodName" SG_ 864 DAY_DPRT_BC "DAY_DPRT_BC";
BA_ "GenSigStartValue" SG_ 864 DAY_DPRT_BC 1;
BA_ "ISignalName" SG_ 864 DAY_DPRT_BC "DAY_DPRT_BC";
BA_ "LongName" SG_ 864 DAY_DPRT_BC "Tag_Abfahrt_BC";
BA_ "SysSignalName" SG_ 864 DAY_DPRT_BC "DAY_DPRT_BC";
BA_ "CompuMethodName" SG_ 864 MON_DPRT_BC "MON_DPRT_BC";
BA_ "GenSigStartValue" SG_ 864 MON_DPRT_BC 1;
BA_ "ISignalName" SG_ 864 MON_DPRT_BC "MON_DPRT_BC";
BA_ "LongName" SG_ 864 MON_DPRT_BC "Monat_Abfahrt_BC";
BA_ "SysSignalName" SG_ 864 MON_DPRT_BC "MON_DPRT_BC";
BA_ "CompuMethodName" SG_ 864 YR_DPRT_BC "YR_DPRT_BC";
BA_ "ISignalName" SG_ 864 YR_DPRT_BC "YR_DPRT_BC";
BA_ "LongName" SG_ 864 YR_DPRT_BC "Jahr_Abfahrt_BC";
BA_ "SysSignalName" SG_ 864 YR_DPRT_BC "YR_DPRT_BC";
BA_ "CompuMethodName" SG_ 862 RDDUR_HRS "RDDUR_HRS";
BA_ "ISignalName" SG_ 862 RDDUR_HRS "RDDUR_HRS";
BA_ "LongName" SG_ 862 RDDUR_HRS "Fahrtdauer_Stunden";
BA_ "SysSignalName" SG_ 862 RDDUR_HRS "RDDUR_HRS";
BA_ "CompuMethodName" SG_ 862 RDDUR_MNTS "RDDUR_MNTS";
BA_ "ISignalName" SG_ 862 RDDUR_MNTS "RDDUR_MNTS";
BA_ "LongName" SG_ 862 RDDUR_MNTS "Fahrtdauer_Minuten";
BA_ "SysSignalName" SG_ 862 RDDUR_MNTS "RDDUR_MNTS";
BA_ "CompuMethodName" SG_ 862 WAY_PSSD "WAY_PSSD";
BA_ "ISignalName" SG_ 862 WAY_PSSD "WAY_PSSD";
BA_ "LongName" SG_ 862 WAY_PSSD "Weg_zurückliegend";
BA_ "SysSignalName" SG_ 862 WAY_PSSD "WAY_PSSD";
BA_ "CompuMethodName" SG_ 824 NO_DCTR_CC_MESS "NO_DCTR_CC_MESS";
BA_ "ISignalName" SG_ 824 NO_DCTR_CC_MESS "NO_DCTR_CC_MESS";
BA_ "LongName" SG_ 824 NO_DCTR_CC_MESS "Nummer_Anzeigesteuerung_Checkcontrol_Meldung";
BA_ "SysSignalName" SG_ 824 NO_DCTR_CC_MESS "NO_DCTR_CC_MESS";
BA_ "CompuMethodName" SG_ 824 DCTR_CC_MESS "DCTR_CC_MESS";
BA_ "ISignalName" SG_ 824 DCTR_CC_MESS "DCTR_CC_MESS";
BA_ "LongName" SG_ 824 DCTR_CC_MESS "Anzeigesteuerung_Checkcontrol_Meldung";
BA_ "SysSignalName" SG_ 824 DCTR_CC_MESS "DCTR_CC_MESS";
BA_ "CompuMethodName" SG_ 824 NO_FRM_DCTR_CC_MESS "NO_FRM_DCTR_CC_MESS";
BA_ "ISignalName" SG_ 824 NO_FRM_DCTR_CC_MESS "NO_FRM_DCTR_CC_MESS";
BA_ "LongName" SG_ 824 NO_FRM_DCTR_CC_MESS "Nummer_Rahmen_Anzeigesteuerung_Checkcontrol_Meldung";
BA_ "SysSignalName" SG_ 824 NO_FRM_DCTR_CC_MESS "NO_FRM_DCTR_CC_MESS";
BA_ "CompuMethodName" SG_ 824 FRM_DCTR_CC_MESS "FRM_DCTR_CC_MESS";
BA_ "ISignalName" SG_ 824 FRM_DCTR_CC_MESS "FRM_DCTR_CC_MESS";
BA_ "LongName" SG_ 824 FRM_DCTR_CC_MESS "Rahmen_Anzeigesteuerung_Checkcontrol_Meldung";
BA_ "SysSignalName" SG_ 824 FRM_DCTR_CC_MESS "FRM_DCTR_CC_MESS";
BA_ "CompuMethodName" SG_ 824 UTDT_DCTR_CC_MESS "UTDT_DCTR_CC_MESS";
BA_ "ISignalName" SG_ 824 UTDT_DCTR_CC_MESS "UTDT_DCTR_CC_MESS";
BA_ "LongName" SG_ 824 UTDT_DCTR_CC_MESS "Nutzdaten_Anzeigesteuerung_Checkcontrol_Meldung";
BA_ "SysSignalName" SG_ 824 UTDT_DCTR_CC_MESS "UTDT_DCTR_CC_MESS";
BA_ "CompuMethodName" SG_ 1022 SU_PREV "SU_PREV";
BA_ "ISignalName" SG_ 1022 SU_PREV "SU_PREV";
BA_ "LongName" SG_ 1022 SU_PREV "Konfiguration_Verhinderung";
BA_ "SysSignalName" SG_ 1022 SU_PREV "SU_PREV";
BA_ "CompuMethodName" SG_ 1022 SU_ST "SU_ST";
BA_ "ISignalName" SG_ 1022 SU_ST "SU_ST";
BA_ "LongName" SG_ 1022 SU_ST "Konfiguration_Status";
BA_ "SysSignalName" SG_ 1022 SU_ST "SU_ST";
BA_ "CompuMethodName" SG_ 1022 SU_MEASMT "SU_MEASMT";
BA_ "ISignalName" SG_ 1022 SU_MEASMT "SU_MEASMT";
BA_ "LongName" SG_ 1022 SU_MEASMT "Konfiguration_Messung";
BA_ "SysSignalName" SG_ 1022 SU_MEASMT "SU_MEASMT";
BA_ "CompuMethodName" SG_ 1022 SU_RSLT "SU_ST";
BA_ "ISignalName" SG_ 1022 SU_RSLT "SU_RSLT";
BA_ "LongName" SG_ 1022 SU_RSLT "Konfiguration_Ergebnis";
BA_ "SysSignalName" SG_ 1022 SU_RSLT "SU_RSLT";
BA_ "CompuMethodName" SG_ 1022 SU_FRC "SU_FRC";
BA_ "ISignalName" SG_ 1022 SU_FRC "SU_FRC";
BA_ "LongName" SG_ 1022 SU_FRC "Konfiguration_Prognose";
BA_ "SysSignalName" SG_ 1022 SU_FRC "SU_FRC";
BA_ "CompuMethodName" SG_ 1023 SU_LEV_MAXV "SU_LEV";
BA_ "ISignalName" SG_ 1023 SU_LEV_MAXV "SU_LEV_MAXV";
BA_ "LongName" SG_ 1023 SU_LEV_MAXV "Konfiguration_Niveau_Maximalwert";
BA_ "SysSignalName" SG_ 1023 SU_LEV_MAXV "SU_LEV_MAXV";
BA_ "CompuMethodName" SG_ 1023 SU_LEV_MINV "SU_LEV";
BA_ "ISignalName" SG_ 1023 SU_LEV_MINV "SU_LEV_MINV";
BA_ "LongName" SG_ 1023 SU_LEV_MINV "Konfiguration_Niveau_Minimalwert";
BA_ "SysSignalName" SG_ 1023 SU_LEV_MINV "SU_LEV_MINV";
BA_ "CompuMethodName" SG_ 1023 SU_LEV_AV_CUMO_MAXV "SU_LEV";
BA_ "ISignalName" SG_ 1023 SU_LEV_AV_CUMO_MAXV "SU_LEV_AV_CUMO_MAXV";
BA_ "LongName" SG_ 1023 SU_LEV_AV_CUMO_MAXV "Konfiguration_Niveau_Alternativ_Kundenmodus_Maximalwert";
BA_ "SysSignalName" SG_ 1023 SU_LEV_AV_CUMO_MAXV "SU_LEV_AV_CUMO_MAXV";
BA_ "CompuMethodName" SG_ 1023 SU_LEV_AV_CUMO_MINV "SU_LEV";
BA_ "ISignalName" SG_ 1023 SU_LEV_AV_CUMO_MINV "SU_LEV_AV_CUMO_MINV";
BA_ "LongName" SG_ 1023 SU_LEV_AV_CUMO_MINV "Konfiguration_Niveau_Alternativ_Kundenmodus_Minimalwert";
BA_ "SysSignalName" SG_ 1023 SU_LEV_AV_CUMO_MINV "SU_LEV_AV_CUMO_MINV";
BA_ "CompuMethodName" SG_ 1023 SU_DISP_DUR_TMOUT "SU_DUR";
BA_ "ISignalName" SG_ 1023 SU_DISP_DUR_TMOUT "SU_DISP_DUR_TMOUT";
BA_ "LongName" SG_ 1023 SU_DISP_DUR_TMOUT "Konfiguration_Anzeige_Dauer_Timeout";
BA_ "SysSignalName" SG_ 1023 SU_DISP_DUR_TMOUT "SU_DISP_DUR_TMOUT";
BA_ "CompuMethodName" SG_ 1023 SU_DISP_DUR_MEASMT "SU_DUR";
BA_ "ISignalName" SG_ 1023 SU_DISP_DUR_MEASMT "SU_DISP_DUR_MEASMT";
BA_ "LongName" SG_ 1023 SU_DISP_DUR_MEASMT "Konfiguration_Anzeige_Dauer_Messung";
BA_ "SysSignalName" SG_ 1023 SU_DISP_DUR_MEASMT "SU_DISP_DUR_MEASMT";
BA_ "CompuMethodName" SG_ 1023 SU_DISP_DUR_ABRT "SU_DUR_MNTS";
BA_ "ISignalName" SG_ 1023 SU_DISP_DUR_ABRT "SU_DISP_DUR_ABRT";
BA_ "LongName" SG_ 1023 SU_DISP_DUR_ABRT "Konfiguration_Anzeige_Dauer_Abbruch";
BA_ "SysSignalName" SG_ 1023 SU_DISP_DUR_ABRT "SU_DISP_DUR_ABRT";
BA_ "CompuMethodName" SG_ 1023 SU_DISP_DUR_RSLT "SU_DUR_MNTS";
BA_ "ISignalName" SG_ 1023 SU_DISP_DUR_RSLT "SU_DISP_DUR_RSLT";
BA_ "LongName" SG_ 1023 SU_DISP_DUR_RSLT "Konfiguration_Anzeige_Dauer_Ergebnis";
BA_ "SysSignalName" SG_ 1023 SU_DISP_DUR_RSLT "SU_DISP_DUR_RSLT";
BA_ "CompuMethodName" SG_ 1024 VL_CENG_OIL_DISP "VL_CENG_OIL_DISP";
BA_ "ISignalName" SG_ 1024 VL_CENG_OIL_DISP "VL_CENG_OIL_DISP";
BA_ "LongName" SG_ 1024 VL_CENG_OIL_DISP "Wert_Verbrennungsmotor_Öl_Anzeige";
BA_ "SysSignalName" SG_ 1024 VL_CENG_OIL_DISP "VL_CENG_OIL_DISP";
BA_ "CompuMethodName" SG_ 1024 VL_CENG_OILV "SU_LEV";
BA_ "ISignalName" SG_ 1024 VL_CENG_OILV "VL_CENG_OILV";
BA_ "LongName" SG_ 1024 VL_CENG_OILV "Wert_Verbrennungsmotor_Ölstand";
BA_ "SysSignalName" SG_ 1024 VL_CENG_OILV "VL_CENG_OILV";
BA_ "CompuMethodName" SG_ 1024 VL_ADDON_INFO "SU_LEV";
BA_ "ISignalName" SG_ 1024 VL_ADDON_INFO "VL_ADDON_INFO";
BA_ "LongName" SG_ 1024 VL_ADDON_INFO "Wert_Zusatz_Information";
BA_ "SysSignalName" SG_ 1024 VL_ADDON_INFO "VL_ADDON_INFO";
BA_ "CompuMethodName" SG_ 1024 VL_MESS "VL_MESS";
BA_ "ISignalName" SG_ 1024 VL_MESS "VL_MESS";
BA_ "LongName" SG_ 1024 VL_MESS "Wert_Meldung";
BA_ "SysSignalName" SG_ 1024 VL_MESS "VL_MESS";
BA_ "CompuMethodName" SG_ 1024 VL_CURR "SU_LEV";
BA_ "ISignalName" SG_ 1024 VL_CURR "VL_CURR";
BA_ "LongName" SG_ 1024 VL_CURR "Wert_Aktualitaet";
BA_ "SysSignalName" SG_ 1024 VL_CURR "VL_CURR";
BA_ "CompuMethodName" SG_ 1024 VL_PREV "VL_PREV";
BA_ "ISignalName" SG_ 1024 VL_PREV "VL_PREV";
BA_ "LongName" SG_ 1024 VL_PREV "Wert_Verhinderung";
BA_ "SysSignalName" SG_ 1024 VL_PREV "VL_PREV";
BA_ "CompuMethodName" SG_ 1024 VL_FRC "VL_FRC";
BA_ "ISignalName" SG_ 1024 VL_FRC "VL_FRC";
BA_ "LongName" SG_ 1024 VL_FRC "Wert_Prognose";
BA_ "SysSignalName" SG_ 1024 VL_FRC "VL_FRC";
BA_ "CompuMethodName" SG_ 1025 VL_RFLV "VL_RFLV";
BA_ "ISignalName" SG_ 1025 VL_RFLV "VL_RFLV";
BA_ "LongName" SG_ 1025 VL_RFLV "Wert_Nachfüllmenge";
BA_ "SysSignalName" SG_ 1025 VL_RFLV "VL_RFLV";
BA_ "CompuMethodName" SG_ 1025 VL_DSTN_AMO "VL_RFLV";
BA_ "ISignalName" SG_ 1025 VL_DSTN_AMO "VL_DSTN_AMO";
BA_ "LongName" SG_ 1025 VL_DSTN_AMO "Wert_Ziel_Menge";
BA_ "SysSignalName" SG_ 1025 VL_DSTN_AMO "VL_DSTN_AMO";
BA_ "CompuMethodName" SG_ 1025 VL_PRES_FIAM "VL_RFLV";
BA_ "ISignalName" SG_ 1025 VL_PRES_FIAM "VL_PRES_FIAM";
BA_ "LongName" SG_ 1025 VL_PRES_FIAM "Wert_Aktuelle_Fuellmenge";
BA_ "SysSignalName" SG_ 1025 VL_PRES_FIAM "VL_PRES_FIAM";
BA_ "CompuMethodName" SG_ 1025 VL_SUTE "VL_SUTE";
BA_ "ISignalName" SG_ 1025 VL_SUTE "VL_SUTE";
BA_ "LongName" SG_ 1025 VL_SUTE "Wert_Sumpftemperatur";
BA_ "SysSignalName" SG_ 1025 VL_SUTE "VL_SUTE";
BA_ "CompuMethodName" SG_ 1025 ST_RFLV "ST_RFLV";
BA_ "ISignalName" SG_ 1025 ST_RFLV "ST_RFLV";
BA_ "LongName" SG_ 1025 ST_RFLV "Status_Nachfüllmenge";
BA_ "SysSignalName" SG_ 1025 ST_RFLV "ST_RFLV";
BA_ "CompuMethodName" SG_ 1025 ST_TAAM "ST_TAAM";
BA_ "ISignalName" SG_ 1025 ST_TAAM "ST_TAAM";
BA_ "LongName" SG_ 1025 ST_TAAM "Status_Zielmenge";
BA_ "SysSignalName" SG_ 1025 ST_TAAM "ST_TAAM";
BA_ "CompuMethodName" SG_ 1025 ST_PRES_FIAM "ST_PRES_FIAM";
BA_ "ISignalName" SG_ 1025 ST_PRES_FIAM "ST_PRES_FIAM";
BA_ "LongName" SG_ 1025 ST_PRES_FIAM "Status_Aktuelle_Fuellmenge";
BA_ "SysSignalName" SG_ 1025 ST_PRES_FIAM "ST_PRES_FIAM";
BA_ "CompuMethodName" SG_ 1025 ST_SUTE "ST_SUTE";
BA_ "ISignalName" SG_ 1025 ST_SUTE "ST_SUTE";
BA_ "LongName" SG_ 1025 ST_SUTE "Status_Sumpftemperatur";
BA_ "SysSignalName" SG_ 1025 ST_SUTE "ST_SUTE";
BA_ "CompuMethodName" SG_ 1025 VL_SEN_LEV "VL_SEN_LEV";
BA_ "ISignalName" SG_ 1025 VL_SEN_LEV "VL_SEN_LEV";
BA_ "LongName" SG_ 1025 VL_SEN_LEV "Wert_Sensor_Niveau";
BA_ "SysSignalName" SG_ 1025 VL_SEN_LEV "VL_SEN_LEV";
BA_ "CompuMethodName" SG_ 1025 RFLV_KEY "RFLV_KEY";
BA_ "GenSigStartValue" SG_ 1025 RFLV_KEY -13;
BA_ "ISignalName" SG_ 1025 RFLV_KEY "RFLV_KEY";
BA_ "LongName" SG_ 1025 RFLV_KEY "Nachfüllmenge_Schlüssel";
BA_ "SysSignalName" SG_ 1025 RFLV_KEY "RFLV_KEY";
BA_ "CompuMethodName" SG_ 919 ST_OBD_CYC "ST_OBD_CYC";
BA_ "ISignalName" SG_ 919 ST_OBD_CYC "ST_OBD_CYC";
BA_ "LongName" SG_ 919 ST_OBD_CYC "Status_OBD_Zyklus";
BA_ "SysSignalName" SG_ 919 ST_OBD_CYC "ST_OBD_CYC";
BA_ "CompuMethodName" SG_ 1000 RQ_MIL_DIAG_OBD_ENGMG_EL "RQ_MIL_DIAG_OBD_GRB";
BA_ "ISignalName" SG_ 1000 RQ_MIL_DIAG_OBD_ENGMG_EL "RQ_MIL_DIAG_OBD_ENGMG_EL";
BA_ "LongName" SG_ 1000 RQ_MIL_DIAG_OBD_ENGMG_EL "Anforderung_MIL_Diagnose_OBD_Motorsteuerung_Elektrisch";
BA_ "SysSignalName" SG_ 1000 RQ_MIL_DIAG_OBD_ENGMG_EL "RQ_MIL_DIAG_OBD_ENGMG_EL";
BA_ "CompuMethodName" SG_ 1000 RQ_RST_OBD_DIAG "RQ_RST_OBD_DIAG";
BA_ "ISignalName" SG_ 1000 RQ_RST_OBD_DIAG "RQ_RST_OBD_DIAG";
BA_ "LongName" SG_ 1000 RQ_RST_OBD_DIAG "request_reset_OBD_diagnosis";
BA_ "SysSignalName" SG_ 1000 RQ_RST_OBD_DIAG "RQ_RST_OBD_DIAG";
BA_ "CompuMethodName" SG_ 514 CTR_ILUM_SW "CTR_ILUM_SW";
BA_ "ISignalName" SG_ 514 CTR_ILUM_SW "CTR_ILUM_SW";
BA_ "LongName" SG_ 514 CTR_ILUM_SW "Steuerung_Beleuchtung_Schalter";
BA_ "SysSignalName" SG_ 514 CTR_ILUM_SW "CTR_ILUM_SW";
BA_ "CompuMethodName" SG_ 659 CRC_DISP_CC_ARS "CRC8";
BA_ "ISignalName" SG_ 659 CRC_DISP_CC_ARS "CRC_DISP_CC_ARS";
BA_ "LongName" SG_ 659 CRC_DISP_CC_ARS "CRC_Anzeige_Checkcontrol_ARS";
BA_ "SysSignalName" SG_ 659 CRC_DISP_CC_ARS "CRC_DISP_CC_ARS";
BA_ "CompuMethodName" SG_ 659 ALIV_DISP_CC_ARS "ALIV_4_BIT_UInt";
BA_ "ISignalName" SG_ 659 ALIV_DISP_CC_ARS "ALIV_DISP_CC_ARS";
BA_ "LongName" SG_ 659 ALIV_DISP_CC_ARS "Alive_Anzeige_Checkcontrol_ARS";
BA_ "SysSignalName" SG_ 659 ALIV_DISP_CC_ARS "ALIV_DISP_CC_ARS";
BA_ "CompuMethodName" SG_ 659 CHL_DISP_CC_ARS "CHL_4_UInt";
BA_ "ISignalName" SG_ 659 CHL_DISP_CC_ARS "CHL_DISP_CC_ARS";
BA_ "LongName" SG_ 659 CHL_DISP_CC_ARS "CHL_Anzeige_Checkcontrol_ARS";
BA_ "SysSignalName" SG_ 659 CHL_DISP_CC_ARS "CHL_DISP_CC_ARS";
BA_ "CompuMethodName" SG_ 659 NO_CC_ARS "NO_CC_ARS";
BA_ "ISignalName" SG_ 659 NO_CC_ARS "NO_CC_ARS";
BA_ "LongName" SG_ 659 NO_CC_ARS "Nummer_Checkcontrol_ARS";
BA_ "SysSignalName" SG_ 659 NO_CC_ARS "NO_CC_ARS";
BA_ "CompuMethodName" SG_ 659 ST_CC_ARS "ST_CC_ARS";
BA_ "ISignalName" SG_ 659 ST_CC_ARS "ST_CC_ARS";
BA_ "LongName" SG_ 659 ST_CC_ARS "Status_Checkcontrol_ARS";
BA_ "SysSignalName" SG_ 659 ST_CC_ARS "ST_CC_ARS";
BA_ "CompuMethodName" SG_ 659 TRANF_CC_ARS "TRANF_CC_ARS";
BA_ "ISignalName" SG_ 659 TRANF_CC_ARS "TRANF_CC_ARS";
BA_ "LongName" SG_ 659 TRANF_CC_ARS "Sendeart_Checkcontrol_ARS";
BA_ "SysSignalName" SG_ 659 TRANF_CC_ARS "TRANF_CC_ARS";
BA_ "CompuMethodName" SG_ 659 ST_IDC_CC_ARS "ST_IDC_CC_ARS";
BA_ "ISignalName" SG_ 659 ST_IDC_CC_ARS "ST_IDC_CC_ARS";
BA_ "LongName" SG_ 659 ST_IDC_CC_ARS "Status_Blinken_Checkcontrol_ARS";
BA_ "SysSignalName" SG_ 659 ST_IDC_CC_ARS "ST_IDC_CC_ARS";
BA_ "CompuMethodName" SG_ 878 CRC_DISP_CC_BYPA_00 "CRC8";
BA_ "ISignalName" SG_ 878 CRC_DISP_CC_BYPA_00 "CRC_DISP_CC_BYPA_00";
BA_ "LongName" SG_ 878 CRC_DISP_CC_BYPA_00 "CRC_Anzeige_Checkcontrol_Bypass_00";
BA_ "SysSignalName" SG_ 878 CRC_DISP_CC_BYPA_00 "CRC_DISP_CC_BYPA_00";
BA_ "CompuMethodName" SG_ 878 ALIV_DISP_CC_BYPA_00 "Aliv_4";
BA_ "ISignalName" SG_ 878 ALIV_DISP_CC_BYPA_00 "ALIV_DISP_CC_BYPA_00";
BA_ "LongName" SG_ 878 ALIV_DISP_CC_BYPA_00 "Alive_Anzeige_Checkcontrol_Bypass_00";
BA_ "SysSignalName" SG_ 878 ALIV_DISP_CC_BYPA_00 "ALIV_DISP_CC_BYPA_00";
BA_ "ISignalName" SG_ 878 DISP_CC_BYPA_00_dummy_12_15 "DISP_CC_BYPA_00_dummy_12_15";
BA_ "LongName" SG_ 878 DISP_CC_BYPA_00_dummy_12_15 "DISP_CC_BYPA_00_dummy_12_15";
BA_ "SysSignalName" SG_ 878 DISP_CC_BYPA_00_dummy_12_15 "DISP_CC_BYPA_00_dummy_12_15";
BA_ "CompuMethodName" SG_ 878 NO_CC_BYPA_00 "NO_CC";
BA_ "ISignalName" SG_ 878 NO_CC_BYPA_00 "NO_CC_BYPA_00";
BA_ "LongName" SG_ 878 NO_CC_BYPA_00 "Nummer_Checkcontrol_Bypass_00";
BA_ "SysSignalName" SG_ 878 NO_CC_BYPA_00 "NO_CC_BYPA_00";
BA_ "CompuMethodName" SG_ 878 ST_CC_BYPA_00 "ST_CC";
BA_ "ISignalName" SG_ 878 ST_CC_BYPA_00 "ST_CC_BYPA_00";
BA_ "LongName" SG_ 878 ST_CC_BYPA_00 "Status_Checkcontrol_Bypass_00";
BA_ "SysSignalName" SG_ 878 ST_CC_BYPA_00 "ST_CC_BYPA_00";
BA_ "CompuMethodName" SG_ 878 TRANF_CC_BYPA_00 "TRANF_CC";
BA_ "ISignalName" SG_ 878 TRANF_CC_BYPA_00 "TRANF_CC_BYPA_00";
BA_ "LongName" SG_ 878 TRANF_CC_BYPA_00 "Sendeart_Checkcontrol_Bypass_00";
BA_ "SysSignalName" SG_ 878 TRANF_CC_BYPA_00 "TRANF_CC_BYPA_00";
BA_ "CompuMethodName" SG_ 878 ST_IDC_CC_BYPA_00 "ST_IDC_CC";
BA_ "ISignalName" SG_ 878 ST_IDC_CC_BYPA_00 "ST_IDC_CC_BYPA_00";
BA_ "LongName" SG_ 878 ST_IDC_CC_BYPA_00 "Status_Blinken_Checkcontrol_Bypass_00";
BA_ "SysSignalName" SG_ 878 ST_IDC_CC_BYPA_00 "ST_IDC_CC_BYPA_00";
BA_ "CompuMethodName" SG_ 879 CRC_DISP_CC_BYPA_01 "CRC8";
BA_ "ISignalName" SG_ 879 CRC_DISP_CC_BYPA_01 "CRC_DISP_CC_BYPA_01";
BA_ "LongName" SG_ 879 CRC_DISP_CC_BYPA_01 "CRC_Anzeige_Checkcontrol_Bypass_01";
BA_ "SysSignalName" SG_ 879 CRC_DISP_CC_BYPA_01 "CRC_DISP_CC_BYPA_01";
BA_ "CompuMethodName" SG_ 879 ALIV_DISP_CC_BYPA_01 "Aliv_4";
BA_ "ISignalName" SG_ 879 ALIV_DISP_CC_BYPA_01 "ALIV_DISP_CC_BYPA_01";
BA_ "LongName" SG_ 879 ALIV_DISP_CC_BYPA_01 "Alive_Anzeige_Checkcontrol_Bypass_01";
BA_ "SysSignalName" SG_ 879 ALIV_DISP_CC_BYPA_01 "ALIV_DISP_CC_BYPA_01";
BA_ "ISignalName" SG_ 879 DISP_CC_BYPA_01_dummy_12_15 "DISP_CC_BYPA_01_dummy_12_15";
BA_ "LongName" SG_ 879 DISP_CC_BYPA_01_dummy_12_15 "DISP_CC_BYPA_01_dummy_12_15";
BA_ "SysSignalName" SG_ 879 DISP_CC_BYPA_01_dummy_12_15 "DISP_CC_BYPA_01_dummy_12_15";
BA_ "CompuMethodName" SG_ 879 NO_CC_BYPA_01 "NO_CC";
BA_ "ISignalName" SG_ 879 NO_CC_BYPA_01 "NO_CC_BYPA_01";
BA_ "LongName" SG_ 879 NO_CC_BYPA_01 "Nummer_Checkcontrol_Bypass_01";
BA_ "SysSignalName" SG_ 879 NO_CC_BYPA_01 "NO_CC_BYPA_01";
BA_ "CompuMethodName" SG_ 879 ST_CC_BYPA_01 "ST_CC";
BA_ "ISignalName" SG_ 879 ST_CC_BYPA_01 "ST_CC_BYPA_01";
BA_ "LongName" SG_ 879 ST_CC_BYPA_01 "Status_Checkcontrol_Bypass_01";
BA_ "SysSignalName" SG_ 879 ST_CC_BYPA_01 "ST_CC_BYPA_01";
BA_ "CompuMethodName" SG_ 879 TRANF_CC_BYPA_01 "TRANF_CC";
BA_ "ISignalName" SG_ 879 TRANF_CC_BYPA_01 "TRANF_CC_BYPA_01";
BA_ "LongName" SG_ 879 TRANF_CC_BYPA_01 "Sendeart_Checkcontrol_Bypass_01";
BA_ "SysSignalName" SG_ 879 TRANF_CC_BYPA_01 "TRANF_CC_BYPA_01";
BA_ "CompuMethodName" SG_ 879 ST_IDC_CC_BYPA_01 "ST_IDC_CC";
BA_ "ISignalName" SG_ 879 ST_IDC_CC_BYPA_01 "ST_IDC_CC_BYPA_01";
BA_ "LongName" SG_ 879 ST_IDC_CC_BYPA_01 "Status_Blinken_Checkcontrol_Bypass_01";
BA_ "SysSignalName" SG_ 879 ST_IDC_CC_BYPA_01 "ST_IDC_CC_BYPA_01";
BA_ "CompuMethodName" SG_ 809 CRC_DISP_CC_BYPA_02 "CRC8";
BA_ "ISignalName" SG_ 809 CRC_DISP_CC_BYPA_02 "CRC_DISP_CC_BYPA_02";
BA_ "LongName" SG_ 809 CRC_DISP_CC_BYPA_02 "CRC_Anzeige_Checkcontrol_Bypass_02";
BA_ "SysSignalName" SG_ 809 CRC_DISP_CC_BYPA_02 "CRC_DISP_CC_BYPA_02";
BA_ "CompuMethodName" SG_ 809 ALIV_DISP_CC_BYPA_02 "ALIV_4_BIT_Unsigned_Integer";
BA_ "ISignalName" SG_ 809 ALIV_DISP_CC_BYPA_02 "ALIV_DISP_CC_BYPA_02";
BA_ "LongName" SG_ 809 ALIV_DISP_CC_BYPA_02 "Alive_Anzeige_Checkcontrol_Bypass_02";
BA_ "SysSignalName" SG_ 809 ALIV_DISP_CC_BYPA_02 "ALIV_DISP_CC_BYPA_02";
BA_ "ISignalName" SG_ 809 DISP_CC_BYPA_02_dummy_12_15 "DISP_CC_BYPA_02_dummy_12_15";
BA_ "LongName" SG_ 809 DISP_CC_BYPA_02_dummy_12_15 "DISP_CC_BYPA_02_dummy_12_15";
BA_ "SysSignalName" SG_ 809 DISP_CC_BYPA_02_dummy_12_15 "DISP_CC_BYPA_02_dummy_12_15";
BA_ "CompuMethodName" SG_ 809 NO_CC_BYPA_02 "NO_CC";
BA_ "ISignalName" SG_ 809 NO_CC_BYPA_02 "NO_CC_BYPA_02";
BA_ "LongName" SG_ 809 NO_CC_BYPA_02 "Nummer_Checkcontrol_Bypass_02";
BA_ "SysSignalName" SG_ 809 NO_CC_BYPA_02 "NO_CC_BYPA_02";
BA_ "CompuMethodName" SG_ 809 ST_CC_BYPA_02 "ST_CC";
BA_ "ISignalName" SG_ 809 ST_CC_BYPA_02 "ST_CC_BYPA_02";
BA_ "LongName" SG_ 809 ST_CC_BYPA_02 "Status_Checkcontrol_Bypass_02";
BA_ "SysSignalName" SG_ 809 ST_CC_BYPA_02 "ST_CC_BYPA_02";
BA_ "CompuMethodName" SG_ 809 TRANF_CC_BYPA_02 "TRANF_CC_2";
BA_ "GenSigStartValue" SG_ 809 TRANF_CC_BYPA_02 1;
BA_ "ISignalName" SG_ 809 TRANF_CC_BYPA_02 "TRANF_CC_BYPA_02";
BA_ "LongName" SG_ 809 TRANF_CC_BYPA_02 "Sendeart_Checkcontrol_Bypass_02";
BA_ "SysSignalName" SG_ 809 TRANF_CC_BYPA_02 "TRANF_CC_BYPA_02";
BA_ "CompuMethodName" SG_ 809 ST_IDC_CC_BYPA_02 "ST_IDC_CC";
BA_ "ISignalName" SG_ 809 ST_IDC_CC_BYPA_02 "ST_IDC_CC_BYPA_02";
BA_ "LongName" SG_ 809 ST_IDC_CC_BYPA_02 "Status_Blinken_Checkcontrol_Bypass_02";
BA_ "SysSignalName" SG_ 809 ST_IDC_CC_BYPA_02 "ST_IDC_CC_BYPA_02";
BA_ "CompuMethodName" SG_ 827 CRC_DISP_CC_BYPA_02 "CRC8";
BA_ "ISignalName" SG_ 827 CRC_DISP_CC_BYPA_02 "CRC_DISP_CC_BYPA_02";
BA_ "LongName" SG_ 827 CRC_DISP_CC_BYPA_02 "CRC_Anzeige_Checkcontrol_Bypass_02";
BA_ "SysSignalName" SG_ 827 CRC_DISP_CC_BYPA_02 "CRC_DISP_CC_BYPA_02";
BA_ "CompuMethodName" SG_ 827 ALIV_DISP_CC_BYPA_02 "ALIV_4_BIT_Unsigned_Integer";
BA_ "ISignalName" SG_ 827 ALIV_DISP_CC_BYPA_02 "ALIV_DISP_CC_BYPA_02";
BA_ "LongName" SG_ 827 ALIV_DISP_CC_BYPA_02 "Alive_Anzeige_Checkcontrol_Bypass_02";
BA_ "SysSignalName" SG_ 827 ALIV_DISP_CC_BYPA_02 "ALIV_DISP_CC_BYPA_02";
BA_ "ISignalName" SG_ 827 DISP_CC_BYPA_02_dummy_12_15 "DISP_CC_BYPA_02_dummy_12_15";
BA_ "LongName" SG_ 827 DISP_CC_BYPA_02_dummy_12_15 "DISP_CC_BYPA_02_dummy_12_15";
BA_ "SysSignalName" SG_ 827 DISP_CC_BYPA_02_dummy_12_15 "DISP_CC_BYPA_02_dummy_12_15";
BA_ "CompuMethodName" SG_ 827 NO_CC_BYPA_02 "NO_CC";
BA_ "ISignalName" SG_ 827 NO_CC_BYPA_02 "NO_CC_BYPA_02";
BA_ "LongName" SG_ 827 NO_CC_BYPA_02 "Nummer_Checkcontrol_Bypass_02";
BA_ "SysSignalName" SG_ 827 NO_CC_BYPA_02 "NO_CC_BYPA_02";
BA_ "CompuMethodName" SG_ 827 ST_CC_BYPA_02 "ST_CC";
BA_ "ISignalName" SG_ 827 ST_CC_BYPA_02 "ST_CC_BYPA_02";
BA_ "LongName" SG_ 827 ST_CC_BYPA_02 "Status_Checkcontrol_Bypass_02";
BA_ "SysSignalName" SG_ 827 ST_CC_BYPA_02 "ST_CC_BYPA_02";
BA_ "CompuMethodName" SG_ 827 TRANF_CC_BYPA_02 "TRANF_CC_2";
BA_ "GenSigStartValue" SG_ 827 TRANF_CC_BYPA_02 1;
BA_ "ISignalName" SG_ 827 TRANF_CC_BYPA_02 "TRANF_CC_BYPA_02";
BA_ "LongName" SG_ 827 TRANF_CC_BYPA_02 "Sendeart_Checkcontrol_Bypass_02";
BA_ "SysSignalName" SG_ 827 TRANF_CC_BYPA_02 "TRANF_CC_BYPA_02";
BA_ "CompuMethodName" SG_ 827 ST_IDC_CC_BYPA_02 "ST_IDC_CC";
BA_ "ISignalName" SG_ 827 ST_IDC_CC_BYPA_02 "ST_IDC_CC_BYPA_02";
BA_ "LongName" SG_ 827 ST_IDC_CC_BYPA_02 "Status_Blinken_Checkcontrol_Bypass_02";
BA_ "SysSignalName" SG_ 827 ST_IDC_CC_BYPA_02 "ST_IDC_CC_BYPA_02";
BA_ "CompuMethodName" SG_ 936 CRC_DISP_CC_BYPA_03 "CRC8";
BA_ "ISignalName" SG_ 936 CRC_DISP_CC_BYPA_03 "CRC_DISP_CC_BYPA_03";
BA_ "LongName" SG_ 936 CRC_DISP_CC_BYPA_03 "CRC_Anzeige_Checkcontrol_Bypass_03";
BA_ "SysSignalName" SG_ 936 CRC_DISP_CC_BYPA_03 "CRC_DISP_CC_BYPA_03";
BA_ "CompuMethodName" SG_ 936 ALIV_DISP_CC_BYPA_03 "ALIV_4_BIT_Unsigned_Integer";
BA_ "ISignalName" SG_ 936 ALIV_DISP_CC_BYPA_03 "ALIV_DISP_CC_BYPA_03";
BA_ "LongName" SG_ 936 ALIV_DISP_CC_BYPA_03 "Alive_Anzeige_Checkcontrol_Bypass_03";
BA_ "SysSignalName" SG_ 936 ALIV_DISP_CC_BYPA_03 "ALIV_DISP_CC_BYPA_03";
BA_ "CompuMethodName" SG_ 936 CHL_DISP_CC_BYPA_03 "CHL_4_UInt";
BA_ "ISignalName" SG_ 936 CHL_DISP_CC_BYPA_03 "CHL_DISP_CC_BYPA_03";
BA_ "LongName" SG_ 936 CHL_DISP_CC_BYPA_03 "CHL_Anzeige_Checkcontrol_Bypass_03";
BA_ "SysSignalName" SG_ 936 CHL_DISP_CC_BYPA_03 "CHL_DISP_CC_BYPA_03";
BA_ "CompuMethodName" SG_ 936 NO_CC_BYPA_03 "NO_CC";
BA_ "ISignalName" SG_ 936 NO_CC_BYPA_03 "NO_CC_BYPA_03";
BA_ "LongName" SG_ 936 NO_CC_BYPA_03 "Nummer_Checkcontrol_Bypass_03";
BA_ "SysSignalName" SG_ 936 NO_CC_BYPA_03 "NO_CC_BYPA_03";
BA_ "CompuMethodName" SG_ 936 ST_CC_BYPA_03 "ST_CC";
BA_ "ISignalName" SG_ 936 ST_CC_BYPA_03 "ST_CC_BYPA_03";
BA_ "LongName" SG_ 936 ST_CC_BYPA_03 "Status_Checkcontrol_Bypass_03";
BA_ "SysSignalName" SG_ 936 ST_CC_BYPA_03 "ST_CC_BYPA_03";
BA_ "CompuMethodName" SG_ 936 TRANF_CC_BYPA_03 "TRANF_CC_2";
BA_ "GenSigStartValue" SG_ 936 TRANF_CC_BYPA_03 1;
BA_ "ISignalName" SG_ 936 TRANF_CC_BYPA_03 "TRANF_CC_BYPA_03";
BA_ "LongName" SG_ 936 TRANF_CC_BYPA_03 "Sendeart_Checkcontrol_Bypass_03";
BA_ "SysSignalName" SG_ 936 TRANF_CC_BYPA_03 "TRANF_CC_BYPA_03";
BA_ "CompuMethodName" SG_ 936 ST_IDC_CC_BYPA_03 "ST_IDC_CC";
BA_ "ISignalName" SG_ 936 ST_IDC_CC_BYPA_03 "ST_IDC_CC_BYPA_03";
BA_ "LongName" SG_ 936 ST_IDC_CC_BYPA_03 "Status_Blinken_Checkcontrol_Bypass_03";
BA_ "SysSignalName" SG_ 936 ST_IDC_CC_BYPA_03 "ST_IDC_CC_BYPA_03";
BA_ "CompuMethodName" SG_ 793 CRC_DISP_CC_CFCT "CRC8";
BA_ "ISignalName" SG_ 793 CRC_DISP_CC_CFCT "CRC_DISP_CC_CFCT";
BA_ "LongName" SG_ 793 CRC_DISP_CC_CFCT "CRC_Anzeige_Checkcontrol_Zentralfunktionen";
BA_ "SysSignalName" SG_ 793 CRC_DISP_CC_CFCT "CRC_DISP_CC_CFCT";
BA_ "CompuMethodName" SG_ 793 ALIV_DISP_CC_CFCT "ALIV_4_BIT_Unsigned_Integer";
BA_ "ISignalName" SG_ 793 ALIV_DISP_CC_CFCT "ALIV_DISP_CC_CFCT";
BA_ "LongName" SG_ 793 ALIV_DISP_CC_CFCT "Alive_Anzeige_Checkcontrol_Zentralfunktionen";
BA_ "SysSignalName" SG_ 793 ALIV_DISP_CC_CFCT "ALIV_DISP_CC_CFCT";
BA_ "CompuMethodName" SG_ 793 CHL_DISP_CC_CFCT "CHL_4_UInt";
BA_ "ISignalName" SG_ 793 CHL_DISP_CC_CFCT "CHL_DISP_CC_CFCT";
BA_ "LongName" SG_ 793 CHL_DISP_CC_CFCT "CHL_Anzeige_Checkcontrol_Zentralfunktionen";
BA_ "SysSignalName" SG_ 793 CHL_DISP_CC_CFCT "CHL_DISP_CC_CFCT";
BA_ "CompuMethodName" SG_ 793 NO_CC_CFCT "NO_CC";
BA_ "ISignalName" SG_ 793 NO_CC_CFCT "NO_CC_CFCT";
BA_ "LongName" SG_ 793 NO_CC_CFCT "Nummer_Checkcontrol_Zentralfunktionen";
BA_ "SysSignalName" SG_ 793 NO_CC_CFCT "NO_CC_CFCT";
BA_ "CompuMethodName" SG_ 793 ST_CC_CFCT "ST_CC";
BA_ "ISignalName" SG_ 793 ST_CC_CFCT "ST_CC_CFCT";
BA_ "LongName" SG_ 793 ST_CC_CFCT "Status_Checkcontrol_Zentralfunktionen";
BA_ "SysSignalName" SG_ 793 ST_CC_CFCT "ST_CC_CFCT";
BA_ "CompuMethodName" SG_ 793 TRANF_CC_CFCT "TRANF_CC_CFCT";
BA_ "ISignalName" SG_ 793 TRANF_CC_CFCT "TRANF_CC_CFCT";
BA_ "LongName" SG_ 793 TRANF_CC_CFCT "Sendeart_Checkcontrol_Zentralfunktionen";
BA_ "SysSignalName" SG_ 793 TRANF_CC_CFCT "TRANF_CC_CFCT";
BA_ "CompuMethodName" SG_ 793 ST_IDC_CC_CFCT "ST_IDC_CC";
BA_ "ISignalName" SG_ 793 ST_IDC_CC_CFCT "ST_IDC_CC_CFCT";
BA_ "LongName" SG_ 793 ST_IDC_CC_CFCT "Status_Blinken_Checkcontrol_Zentralfunktionen";
BA_ "SysSignalName" SG_ 793 ST_IDC_CC_CFCT "ST_IDC_CC_CFCT";
BA_ "CompuMethodName" SG_ 404 CRC_DISP_CC_DFNS "CRC8";
BA_ "ISignalName" SG_ 404 CRC_DISP_CC_DFNS "CRC_DISP_CC_DFNS";
BA_ "LongName" SG_ 404 CRC_DISP_CC_DFNS "CRC_Anzeige_Checkcontrol_Antriebsfunktionen";
BA_ "SysSignalName" SG_ 404 CRC_DISP_CC_DFNS "CRC_DISP_CC_DFNS";
BA_ "CompuMethodName" SG_ 404 ALIV_DISP_CC_DFNS "ALIV_4_BIT_Unsigned_Integer";
BA_ "ISignalName" SG_ 404 ALIV_DISP_CC_DFNS "ALIV_DISP_CC_DFNS";
BA_ "LongName" SG_ 404 ALIV_DISP_CC_DFNS "alive_display_check-control_drive-functions";
BA_ "SysSignalName" SG_ 404 ALIV_DISP_CC_DFNS "ALIV_DISP_CC_DFNS";
BA_ "CompuMethodName" SG_ 404 CHL_DISP_CC_DFNS "CHL_4_UInt";
BA_ "ISignalName" SG_ 404 CHL_DISP_CC_DFNS "CHL_DISP_CC_DFNS";
BA_ "LongName" SG_ 404 CHL_DISP_CC_DFNS "CHL_Anzeige_Checkcontrol_Antriebsfunktionen";
BA_ "SysSignalName" SG_ 404 CHL_DISP_CC_DFNS "CHL_DISP_CC_DFNS";
BA_ "CompuMethodName" SG_ 404 NO_CC_DFNS "NO_CC_DFNS";
BA_ "ISignalName" SG_ 404 NO_CC_DFNS "NO_CC_DFNS";
BA_ "LongName" SG_ 404 NO_CC_DFNS "Nummer_Checkcontrol_Antriebsfunktionen";
BA_ "SysSignalName" SG_ 404 NO_CC_DFNS "NO_CC_DFNS";
BA_ "CompuMethodName" SG_ 404 ST_CC_DFNS "ST_CC_DFNS";
BA_ "ISignalName" SG_ 404 ST_CC_DFNS "ST_CC_DFNS";
BA_ "LongName" SG_ 404 ST_CC_DFNS "Status_Checkcontrol_Antriebsfunktionen";
BA_ "SysSignalName" SG_ 404 ST_CC_DFNS "ST_CC_DFNS";
BA_ "CompuMethodName" SG_ 404 TRANF_CC_DFNS "TRANF_CC_DFNS";
BA_ "ISignalName" SG_ 404 TRANF_CC_DFNS "TRANF_CC_DFNS";
BA_ "LongName" SG_ 404 TRANF_CC_DFNS "Sendeart_Checkcontrol_Antriebsfunktionen";
BA_ "SysSignalName" SG_ 404 TRANF_CC_DFNS "TRANF_CC_DFNS";
BA_ "CompuMethodName" SG_ 404 ST_IDC_CC_DFNS "ST_IDC_CC_DFNS";
BA_ "ISignalName" SG_ 404 ST_IDC_CC_DFNS "ST_IDC_CC_DFNS";
BA_ "LongName" SG_ 404 ST_IDC_CC_DFNS "Status_Blinken_Checkcontrol_Antriebsfunktionen";
BA_ "SysSignalName" SG_ 404 ST_IDC_CC_DFNS "ST_IDC_CC_DFNS";
BA_ "CompuMethodName" SG_ 781 CRC_DISP_CC_DRASY "CRC8";
BA_ "ISignalName" SG_ 781 CRC_DISP_CC_DRASY "CRC_DISP_CC_DRASY";
BA_ "LongName" SG_ 781 CRC_DISP_CC_DRASY "CRC_Anzeige_Checkcontrol_Fahrerassistenzsystem";
BA_ "SysSignalName" SG_ 781 CRC_DISP_CC_DRASY "CRC_DISP_CC_DRASY";
BA_ "CompuMethodName" SG_ 781 ALIV_DISP_CC_DRASY "ALIV_4_BIT_Unsigned_Integer";
BA_ "ISignalName" SG_ 781 ALIV_DISP_CC_DRASY "ALIV_DISP_CC_DRASY";
BA_ "LongName" SG_ 781 ALIV_DISP_CC_DRASY "Alive_Anzeige_Checkcontrol_Fahrerassistenzsystem";
BA_ "SysSignalName" SG_ 781 ALIV_DISP_CC_DRASY "ALIV_DISP_CC_DRASY";
BA_ "ISignalName" SG_ 781 DISP_CC_DRASY_dummy_12_15 "DISP_CC_DRASY_dummy_12_15";
BA_ "LongName" SG_ 781 DISP_CC_DRASY_dummy_12_15 "DISP_CC_DRASY_dummy_12_15";
BA_ "SysSignalName" SG_ 781 DISP_CC_DRASY_dummy_12_15 "DISP_CC_DRASY_dummy_12_15";
BA_ "CompuMethodName" SG_ 781 NO_CC_DRASY "NO_CC";
BA_ "ISignalName" SG_ 781 NO_CC_DRASY "NO_CC_DRASY";
BA_ "LongName" SG_ 781 NO_CC_DRASY "Nummer_Checkcontrol_Fahrerassistenzsystem";
BA_ "SysSignalName" SG_ 781 NO_CC_DRASY "NO_CC_DRASY";
BA_ "CompuMethodName" SG_ 781 ST_CC_DRASY "ST_CC";
BA_ "ISignalName" SG_ 781 ST_CC_DRASY "ST_CC_DRASY";
BA_ "LongName" SG_ 781 ST_CC_DRASY "Status_Checkcontrol_Fahrerassistenzsystem";
BA_ "SysSignalName" SG_ 781 ST_CC_DRASY "ST_CC_DRASY";
BA_ "CompuMethodName" SG_ 781 TRANF_CC_DRASY "TRANF_CC_2";
BA_ "GenSigStartValue" SG_ 781 TRANF_CC_DRASY 1;
BA_ "ISignalName" SG_ 781 TRANF_CC_DRASY "TRANF_CC_DRASY";
BA_ "LongName" SG_ 781 TRANF_CC_DRASY "Sendeart_Checkcontrol_Fahrerassistenzsystem";
BA_ "SysSignalName" SG_ 781 TRANF_CC_DRASY "TRANF_CC_DRASY";
BA_ "CompuMethodName" SG_ 781 ST_IDC_CC_DRASY "ST_IDC_CC";
BA_ "ISignalName" SG_ 781 ST_IDC_CC_DRASY "ST_IDC_CC_DRASY";
BA_ "LongName" SG_ 781 ST_IDC_CC_DRASY "Status_Blinken_Checkcontrol_Fahrerassistenzsystem";
BA_ "SysSignalName" SG_ 781 ST_IDC_CC_DRASY "ST_IDC_CC_DRASY";
BA_ "CompuMethodName" SG_ 679 CRC_DISP_CC_DRDY_COOTD "CRC8";
BA_ "ISignalName" SG_ 679 CRC_DISP_CC_DRDY_COOTD "CRC_DISP_CC_DRDY_COOTD";
BA_ "LongName" SG_ 679 CRC_DISP_CC_DRDY_COOTD "CRC_Anzeige_Checkcontrol_Fahrdynamik_Koordiniert";
BA_ "SysSignalName" SG_ 679 CRC_DISP_CC_DRDY_COOTD "CRC_DISP_CC_DRDY_COOTD";
BA_ "CompuMethodName" SG_ 679 ALIV_DISP_CC_DRDY_COOTD "Aliv_4";
BA_ "ISignalName" SG_ 679 ALIV_DISP_CC_DRDY_COOTD "ALIV_DISP_CC_DRDY_COOTD";
BA_ "LongName" SG_ 679 ALIV_DISP_CC_DRDY_COOTD "Alive_Anzeige_Checkcontrol_Fahrdynamik_Koordiniert";
BA_ "SysSignalName" SG_ 679 ALIV_DISP_CC_DRDY_COOTD "ALIV_DISP_CC_DRDY_COOTD";
BA_ "ISignalName" SG_ 679 DISP_CC_DRDY_COOTD_dummy_12_15 "DISP_CC_DRDY_COOTD_dummy_12_15";
BA_ "LongName" SG_ 679 DISP_CC_DRDY_COOTD_dummy_12_15 "DISP_CC_DRDY_COOTD_dummy_12_15";
BA_ "SysSignalName" SG_ 679 DISP_CC_DRDY_COOTD_dummy_12_15 "DISP_CC_DRDY_COOTD_dummy_12_15";
BA_ "CompuMethodName" SG_ 679 NO_CC_DRDY_COOTD "NO_CC";
BA_ "ISignalName" SG_ 679 NO_CC_DRDY_COOTD "NO_CC_DRDY_COOTD";
BA_ "LongName" SG_ 679 NO_CC_DRDY_COOTD "Nummer_Checkcontrol_Fahrdynamik_Koordiniert";
BA_ "SysSignalName" SG_ 679 NO_CC_DRDY_COOTD "NO_CC_DRDY_COOTD";
BA_ "CompuMethodName" SG_ 679 ST_CC_DRDY_COOTD "ST_CC";
BA_ "ISignalName" SG_ 679 ST_CC_DRDY_COOTD "ST_CC_DRDY_COOTD";
BA_ "LongName" SG_ 679 ST_CC_DRDY_COOTD "Status_Checkcontrol_Fahrdynamik_Koordiniert";
BA_ "SysSignalName" SG_ 679 ST_CC_DRDY_COOTD "ST_CC_DRDY_COOTD";
BA_ "CompuMethodName" SG_ 679 TRANF_CC_DRDY_COOTD "TRANF_CC";
BA_ "ISignalName" SG_ 679 TRANF_CC_DRDY_COOTD "TRANF_CC_DRDY_COOTD";
BA_ "LongName" SG_ 679 TRANF_CC_DRDY_COOTD "Sendeart_Checkcontrol_Fahrdynamik_Koordiniert";
BA_ "SysSignalName" SG_ 679 TRANF_CC_DRDY_COOTD "TRANF_CC_DRDY_COOTD";
BA_ "CompuMethodName" SG_ 679 ST_IDC_CC_DRDY_COOTD "ST_IDC_CC";
BA_ "ISignalName" SG_ 679 ST_IDC_CC_DRDY_COOTD "ST_IDC_CC_DRDY_COOTD";
BA_ "LongName" SG_ 679 ST_IDC_CC_DRDY_COOTD "Status_Blinken_Checkcontrol_Fahrdynamik_Koordiniert";
BA_ "SysSignalName" SG_ 679 ST_IDC_CC_DRDY_COOTD "ST_IDC_CC_DRDY_COOTD";
BA_ "CompuMethodName" SG_ 662 CRC_DISP_CC_EHC "CRC8";
BA_ "ISignalName" SG_ 662 CRC_DISP_CC_EHC "CRC_DISP_CC_EHC";
BA_ "LongName" SG_ 662 CRC_DISP_CC_EHC "CRC_Anzeige_Checkcontrol_EHC";
BA_ "SysSignalName" SG_ 662 CRC_DISP_CC_EHC "CRC_DISP_CC_EHC";
BA_ "CompuMethodName" SG_ 662 ALIV_DISP_CC_EHC "ALIV_4_BIT_UInt";
BA_ "ISignalName" SG_ 662 ALIV_DISP_CC_EHC "ALIV_DISP_CC_EHC";
BA_ "LongName" SG_ 662 ALIV_DISP_CC_EHC "Alive_Anzeige_Checkcontrol_EHC";
BA_ "SysSignalName" SG_ 662 ALIV_DISP_CC_EHC "ALIV_DISP_CC_EHC";
BA_ "CompuMethodName" SG_ 662 CHL_DISP_CC_EHC "CHL_4_UInt";
BA_ "ISignalName" SG_ 662 CHL_DISP_CC_EHC "CHL_DISP_CC_EHC";
BA_ "LongName" SG_ 662 CHL_DISP_CC_EHC "CHL_Anzeige_Checkcontrol_EHC";
BA_ "SysSignalName" SG_ 662 CHL_DISP_CC_EHC "CHL_DISP_CC_EHC";
BA_ "CompuMethodName" SG_ 662 NO_CC_EHC "NO_CC_EHC";
BA_ "ISignalName" SG_ 662 NO_CC_EHC "NO_CC_EHC";
BA_ "LongName" SG_ 662 NO_CC_EHC "Nummer_Checkcontrol_EHC";
BA_ "SysSignalName" SG_ 662 NO_CC_EHC "NO_CC_EHC";
BA_ "CompuMethodName" SG_ 662 ST_CC_EHC "ST_CC_EHC";
BA_ "ISignalName" SG_ 662 ST_CC_EHC "ST_CC_EHC";
BA_ "LongName" SG_ 662 ST_CC_EHC "Status_Checkcontrol_EHC";
BA_ "SysSignalName" SG_ 662 ST_CC_EHC "ST_CC_EHC";
BA_ "CompuMethodName" SG_ 662 TRANF_CC_EHC "TRANF_CC_EHC";
BA_ "ISignalName" SG_ 662 TRANF_CC_EHC "TRANF_CC_EHC";
BA_ "LongName" SG_ 662 TRANF_CC_EHC "Sendeart_Checkcontrol_EHC";
BA_ "SysSignalName" SG_ 662 TRANF_CC_EHC "TRANF_CC_EHC";
BA_ "CompuMethodName" SG_ 662 ST_IDC_CC_EHC "ST_IDC_CC_EHC";
BA_ "ISignalName" SG_ 662 ST_IDC_CC_EHC "ST_IDC_CC_EHC";
BA_ "LongName" SG_ 662 ST_IDC_CC_EHC "Status_Blinken_Checkcontrol_EHC";
BA_ "SysSignalName" SG_ 662 ST_IDC_CC_EHC "ST_IDC_CC_EHC";
BA_ "CompuMethodName" SG_ 660 CRC_DISP_CC_EPS "CRC8";
BA_ "ISignalName" SG_ 660 CRC_DISP_CC_EPS "CRC_DISP_CC_EPS";
BA_ "LongName" SG_ 660 CRC_DISP_CC_EPS "CRC_Anzeige_Checkcontrol_EPS";
BA_ "SysSignalName" SG_ 660 CRC_DISP_CC_EPS "CRC_DISP_CC_EPS";
BA_ "CompuMethodName" SG_ 660 ALIV_DISP_CC_EPS "ALIV_4_BIT_UInt";
BA_ "ISignalName" SG_ 660 ALIV_DISP_CC_EPS "ALIV_DISP_CC_EPS";
BA_ "LongName" SG_ 660 ALIV_DISP_CC_EPS "Alive_Anzeige_Checkcontrol_EPS";
BA_ "SysSignalName" SG_ 660 ALIV_DISP_CC_EPS "ALIV_DISP_CC_EPS";
BA_ "CompuMethodName" SG_ 660 CHL_DISP_CC_EPS "CHL_4_UInt";
BA_ "ISignalName" SG_ 660 CHL_DISP_CC_EPS "CHL_DISP_CC_EPS";
BA_ "LongName" SG_ 660 CHL_DISP_CC_EPS "CHL_Anzeige_Checkcontrol_EPS";
BA_ "SysSignalName" SG_ 660 CHL_DISP_CC_EPS "CHL_DISP_CC_EPS";
BA_ "CompuMethodName" SG_ 660 NO_CC_EPS "NO_CC_EPS";
BA_ "ISignalName" SG_ 660 NO_CC_EPS "NO_CC_EPS";
BA_ "LongName" SG_ 660 NO_CC_EPS "Nummer_Checkcontrol_EPS";
BA_ "SysSignalName" SG_ 660 NO_CC_EPS "NO_CC_EPS";
BA_ "CompuMethodName" SG_ 660 ST_CC_EPS "ST_CC_EPS";
BA_ "ISignalName" SG_ 660 ST_CC_EPS "ST_CC_EPS";
BA_ "LongName" SG_ 660 ST_CC_EPS "Status_Checkcontrol_EPS";
BA_ "SysSignalName" SG_ 660 ST_CC_EPS "ST_CC_EPS";
BA_ "CompuMethodName" SG_ 660 TRANF_CC_EPS "TRANF_CC_EPS";
BA_ "ISignalName" SG_ 660 TRANF_CC_EPS "TRANF_CC_EPS";
BA_ "LongName" SG_ 660 TRANF_CC_EPS "Sendeart_Checkcontrol_EPS";
BA_ "SysSignalName" SG_ 660 TRANF_CC_EPS "TRANF_CC_EPS";
BA_ "CompuMethodName" SG_ 660 ST_IDC_CC_EPS "ST_IDC_CC_EPS";
BA_ "ISignalName" SG_ 660 ST_IDC_CC_EPS "ST_IDC_CC_EPS";
BA_ "LongName" SG_ 660 ST_IDC_CC_EPS "Status_Blinken_Checkcontrol_EPS";
BA_ "SysSignalName" SG_ 660 ST_IDC_CC_EPS "ST_IDC_CC_EPS";
BA_ "CompuMethodName" SG_ 416 CRC_DISP_CC_GRB "CRC8";
BA_ "ISignalName" SG_ 416 CRC_DISP_CC_GRB "CRC_DISP_CC_GRB";
BA_ "LongName" SG_ 416 CRC_DISP_CC_GRB "CRC_Anzeige_Checkcontrol_Getriebe";
BA_ "SysSignalName" SG_ 416 CRC_DISP_CC_GRB "CRC_DISP_CC_GRB";
BA_ "CompuMethodName" SG_ 416 ALIV_DISP_CC_GRB "ALIV_4_BIT_Unsigned_Integer";
BA_ "ISignalName" SG_ 416 ALIV_DISP_CC_GRB "ALIV_DISP_CC_GRB";
BA_ "LongName" SG_ 416 ALIV_DISP_CC_GRB "Alive_Anzeige_Checkcontrol_Getriebe";
BA_ "SysSignalName" SG_ 416 ALIV_DISP_CC_GRB "ALIV_DISP_CC_GRB";
BA_ "CompuMethodName" SG_ 416 CHL_DISP_CC_GRB "CHL_4_UInt";
BA_ "ISignalName" SG_ 416 CHL_DISP_CC_GRB "CHL_DISP_CC_GRB";
BA_ "LongName" SG_ 416 CHL_DISP_CC_GRB "CHL_Anzeige_Checkcontrol_Getriebe";
BA_ "SysSignalName" SG_ 416 CHL_DISP_CC_GRB "CHL_DISP_CC_GRB";
BA_ "CompuMethodName" SG_ 416 NO_CC_GRB "NO_CC_GRB";
BA_ "ISignalName" SG_ 416 NO_CC_GRB "NO_CC_GRB";
BA_ "LongName" SG_ 416 NO_CC_GRB "Nummer_Checkcontrol_Getriebe";
BA_ "SysSignalName" SG_ 416 NO_CC_GRB "NO_CC_GRB";
BA_ "CompuMethodName" SG_ 416 ST_CC_GRB "ST_CC_GRB";
BA_ "ISignalName" SG_ 416 ST_CC_GRB "ST_CC_GRB";
BA_ "LongName" SG_ 416 ST_CC_GRB "Status_Checkcontrol_Getriebe";
BA_ "SysSignalName" SG_ 416 ST_CC_GRB "ST_CC_GRB";
BA_ "CompuMethodName" SG_ 416 TRANF_CC_GRB "TRANF_CC_GRB";
BA_ "ISignalName" SG_ 416 TRANF_CC_GRB "TRANF_CC_GRB";
BA_ "LongName" SG_ 416 TRANF_CC_GRB "Sendeart_Checkcontrol_Getriebe";
BA_ "SysSignalName" SG_ 416 TRANF_CC_GRB "TRANF_CC_GRB";
BA_ "CompuMethodName" SG_ 416 ST_IDC_CC_GRB "ST_IDC_CC_GRB";
BA_ "ISignalName" SG_ 416 ST_IDC_CC_GRB "ST_IDC_CC_GRB";
BA_ "LongName" SG_ 416 ST_IDC_CC_GRB "Status_Blinken_Checkcontrol_Getriebe";
BA_ "SysSignalName" SG_ 416 ST_IDC_CC_GRB "ST_IDC_CC_GRB";
BA_ "CompuMethodName" SG_ 661 CRC_DISP_CC_HVSTO "CRC8";
BA_ "ISignalName" SG_ 661 CRC_DISP_CC_HVSTO "CRC_DISP_CC_HVSTO";
BA_ "LongName" SG_ 661 CRC_DISP_CC_HVSTO "CRC_Anzeige_Checkcontrol_Hochvoltspeicher";
BA_ "SysSignalName" SG_ 661 CRC_DISP_CC_HVSTO "CRC_DISP_CC_HVSTO";
BA_ "CompuMethodName" SG_ 661 ALIV_DISP_CC_HVSTO "ALIV_4_BIT_Unsigned_Integer";
BA_ "ISignalName" SG_ 661 ALIV_DISP_CC_HVSTO "ALIV_DISP_CC_HVSTO";
BA_ "LongName" SG_ 661 ALIV_DISP_CC_HVSTO "Alive_Anzeige_Checkcontrol_Hochvoltspeicher";
BA_ "SysSignalName" SG_ 661 ALIV_DISP_CC_HVSTO "ALIV_DISP_CC_HVSTO";
BA_ "CompuMethodName" SG_ 661 CHL_DISP_CC_HVSTO "CHL_4_UInt";
BA_ "ISignalName" SG_ 661 CHL_DISP_CC_HVSTO "CHL_DISP_CC_HVSTO";
BA_ "LongName" SG_ 661 CHL_DISP_CC_HVSTO "CHL_Anzeige_Checkcontrol_Hochvoltspeicher";
BA_ "SysSignalName" SG_ 661 CHL_DISP_CC_HVSTO "CHL_DISP_CC_HVSTO";
BA_ "CompuMethodName" SG_ 661 NO_CC_HVSTO "NO_CC_HVSTO";
BA_ "ISignalName" SG_ 661 NO_CC_HVSTO "NO_CC_HVSTO";
BA_ "LongName" SG_ 661 NO_CC_HVSTO "Nummer_Checkcontrol_Hochvoltspeicher";
BA_ "SysSignalName" SG_ 661 NO_CC_HVSTO "NO_CC_HVSTO";
BA_ "CompuMethodName" SG_ 661 ST_CC_HVSTO "ST_CC_HVSTO";
BA_ "ISignalName" SG_ 661 ST_CC_HVSTO "ST_CC_HVSTO";
BA_ "LongName" SG_ 661 ST_CC_HVSTO "Status_Checkcontrol_Hochvoltspeicher";
BA_ "SysSignalName" SG_ 661 ST_CC_HVSTO "ST_CC_HVSTO";
BA_ "CompuMethodName" SG_ 661 TRANF_CC_HVSTO "TRANF_CC_HVSTO";
BA_ "ISignalName" SG_ 661 TRANF_CC_HVSTO "TRANF_CC_HVSTO";
BA_ "LongName" SG_ 661 TRANF_CC_HVSTO "Sendeart_Checkcontrol_Hochvoltspeicher";
BA_ "SysSignalName" SG_ 661 TRANF_CC_HVSTO "TRANF_CC_HVSTO";
BA_ "CompuMethodName" SG_ 661 ST_IDC_CC_HVSTO "ST_IDC_CC_HVSTO";
BA_ "ISignalName" SG_ 661 ST_IDC_CC_HVSTO "ST_IDC_CC_HVSTO";
BA_ "LongName" SG_ 661 ST_IDC_CC_HVSTO "Status_Blinken_Checkcontrol_Hochvoltspeicher";
BA_ "SysSignalName" SG_ 661 ST_IDC_CC_HVSTO "ST_IDC_CC_HVSTO";
BA_ "ISignalName" SG_ 661 DISP_CC_HVS_dummy_40_63 "DISP_CC_HVS_dummy_40_63";
BA_ "LongName" SG_ 661 DISP_CC_HVS_dummy_40_63 "DISP_CC_HVS_dummy_40_63";
BA_ "SysSignalName" SG_ 661 DISP_CC_HVS_dummy_40_63 "DISP_CC_HVS_dummy_40_63";
BA_ "CompuMethodName" SG_ 822 NO_FRM_CC_MESS_SCR "NO_FRM_CC_MESS_SCR";
BA_ "ISignalName" SG_ 822 NO_FRM_CC_MESS_SCR "NO_FRM_CC_MESS_SCR";
BA_ "LongName" SG_ 822 NO_FRM_CC_MESS_SCR "Nummer_Rahmen_Checkcontrol_Meldung_Rolle";
BA_ "SysSignalName" SG_ 822 NO_FRM_CC_MESS_SCR "NO_FRM_CC_MESS_SCR";
BA_ "CompuMethodName" SG_ 822 QUAN_FRM_CC_MESS_SCR "QUAN_FRM_CC_MESS_SCR";
BA_ "ISignalName" SG_ 822 QUAN_FRM_CC_MESS_SCR "QUAN_FRM_CC_MESS_SCR";
BA_ "LongName" SG_ 822 QUAN_FRM_CC_MESS_SCR "Anzahl_Rahmen_Checkcontrol_Meldung_Rolle";
BA_ "SysSignalName" SG_ 822 QUAN_FRM_CC_MESS_SCR "QUAN_FRM_CC_MESS_SCR";
BA_ "CompuMethodName" SG_ 822 NO_CC_MESS_1 "NO_CC_MESS_1";
BA_ "ISignalName" SG_ 822 NO_CC_MESS_1 "NO_CC_MESS_1";
BA_ "LongName" SG_ 822 NO_CC_MESS_1 "Nummer_Checkcontrol_Meldung_1";
BA_ "SysSignalName" SG_ 822 NO_CC_MESS_1 "NO_CC_MESS_1";
BA_ "CompuMethodName" SG_ 822 NO_CC_MESS_2 "NO_CC_MESS_2";
BA_ "ISignalName" SG_ 822 NO_CC_MESS_2 "NO_CC_MESS_2";
BA_ "LongName" SG_ 822 NO_CC_MESS_2 "Nummer_Checkcontrol_Meldung_2";
BA_ "SysSignalName" SG_ 822 NO_CC_MESS_2 "NO_CC_MESS_2";
BA_ "CompuMethodName" SG_ 822 NO_CC_MESS_3 "NO_CC_MESS_3";
BA_ "ISignalName" SG_ 822 NO_CC_MESS_3 "NO_CC_MESS_3";
BA_ "LongName" SG_ 822 NO_CC_MESS_3 "number_check-control_message_3";
BA_ "SysSignalName" SG_ 822 NO_CC_MESS_3 "NO_CC_MESS_3";
BA_ "CompuMethodName" SG_ 780 CRC_DISP_CC_PMA "CRC8";
BA_ "ISignalName" SG_ 780 CRC_DISP_CC_PMA "CRC_DISP_CC_PMA";
BA_ "LongName" SG_ 780 CRC_DISP_CC_PMA "CRC_Anzeige_Checkcontrol_Parkassistent";
BA_ "SysSignalName" SG_ 780 CRC_DISP_CC_PMA "CRC_DISP_CC_PMA";
BA_ "CompuMethodName" SG_ 780 ALIV_DISP_CC_PMA "ALIV_4_BIT_Unsigned_Integer";
BA_ "ISignalName" SG_ 780 ALIV_DISP_CC_PMA "ALIV_DISP_CC_PMA";
BA_ "LongName" SG_ 780 ALIV_DISP_CC_PMA "Alive_Anzeige_Checkcontrol_Parkassistent";
BA_ "SysSignalName" SG_ 780 ALIV_DISP_CC_PMA "ALIV_DISP_CC_PMA";
BA_ "ISignalName" SG_ 780 DISP_CC_PMA_dummy_12_15 "DISP_CC_PMA_dummy_12_15";
BA_ "LongName" SG_ 780 DISP_CC_PMA_dummy_12_15 "DISP_CC_PMA_dummy_12_15";
BA_ "SysSignalName" SG_ 780 DISP_CC_PMA_dummy_12_15 "DISP_CC_PMA_dummy_12_15";
BA_ "CompuMethodName" SG_ 780 NO_CC_PMA "NO_CC";
BA_ "ISignalName" SG_ 780 NO_CC_PMA "NO_CC_PMA";
BA_ "LongName" SG_ 780 NO_CC_PMA "Nummer_Checkcontrol_Parkassistent";
BA_ "SysSignalName" SG_ 780 NO_CC_PMA "NO_CC_PMA";
BA_ "CompuMethodName" SG_ 780 ST_CC_PMA "ST_CC";
BA_ "ISignalName" SG_ 780 ST_CC_PMA "ST_CC_PMA";
BA_ "LongName" SG_ 780 ST_CC_PMA "Status_Checkcontrol_Parkassistent";
BA_ "SysSignalName" SG_ 780 ST_CC_PMA "ST_CC_PMA";
BA_ "CompuMethodName" SG_ 780 TRANF_CC_PMA "TRANF_CC_2";
BA_ "GenSigStartValue" SG_ 780 TRANF_CC_PMA 1;
BA_ "ISignalName" SG_ 780 TRANF_CC_PMA "TRANF_CC_PMA";
BA_ "LongName" SG_ 780 TRANF_CC_PMA "Sendeart_Checkcontrol_Parkassistent";
BA_ "SysSignalName" SG_ 780 TRANF_CC_PMA "TRANF_CC_PMA";
BA_ "CompuMethodName" SG_ 780 ST_IDC_CC_PMA "ST_IDC_CC";
BA_ "ISignalName" SG_ 780 ST_IDC_CC_PMA "ST_IDC_CC_PMA";
BA_ "LongName" SG_ 780 ST_IDC_CC_PMA "Status_Blinken_Checkcontrol_Parkassistent";
BA_ "SysSignalName" SG_ 780 ST_IDC_CC_PMA "ST_IDC_CC_PMA";
BA_ "CompuMethodName" SG_ 654 CRC_DISP_CC_VDC "CRC8";
BA_ "ISignalName" SG_ 654 CRC_DISP_CC_VDC "CRC_DISP_CC_VDC";
BA_ "LongName" SG_ 654 CRC_DISP_CC_VDC "CRC_Anzeige_Checkcontrol_VDC";
BA_ "SysSignalName" SG_ 654 CRC_DISP_CC_VDC "CRC_DISP_CC_VDC";
BA_ "CompuMethodName" SG_ 654 ALIV_DISP_CC_VDC "ALIV_4_BIT_UInt";
BA_ "ISignalName" SG_ 654 ALIV_DISP_CC_VDC "ALIV_DISP_CC_VDC";
BA_ "LongName" SG_ 654 ALIV_DISP_CC_VDC "Alive_Anzeige_Checkcontrol_VDC";
BA_ "SysSignalName" SG_ 654 ALIV_DISP_CC_VDC "ALIV_DISP_CC_VDC";
BA_ "CompuMethodName" SG_ 654 CHL_DISP_CC_VDC "CHL_4_UInt";
BA_ "ISignalName" SG_ 654 CHL_DISP_CC_VDC "CHL_DISP_CC_VDC";
BA_ "LongName" SG_ 654 CHL_DISP_CC_VDC "CHL_Anzeige_Checkcontrol_VDC";
BA_ "SysSignalName" SG_ 654 CHL_DISP_CC_VDC "CHL_DISP_CC_VDC";
BA_ "CompuMethodName" SG_ 654 NO_CC_VDC "NO_CC_VDC";
BA_ "ISignalName" SG_ 654 NO_CC_VDC "NO_CC_VDC";
BA_ "LongName" SG_ 654 NO_CC_VDC "Nummer_Checkcontrol_VDC";
BA_ "SysSignalName" SG_ 654 NO_CC_VDC "NO_CC_VDC";
BA_ "CompuMethodName" SG_ 654 ST_CC_VDC "ST_CC_VDC";
BA_ "ISignalName" SG_ 654 ST_CC_VDC "ST_CC_VDC";
BA_ "LongName" SG_ 654 ST_CC_VDC "Status_Checkcontrol_VDC";
BA_ "SysSignalName" SG_ 654 ST_CC_VDC "ST_CC_VDC";
BA_ "CompuMethodName" SG_ 654 TRANF_CC_VDC "TRANF_CC_VDC";
BA_ "ISignalName" SG_ 654 TRANF_CC_VDC "TRANF_CC_VDC";
BA_ "LongName" SG_ 654 TRANF_CC_VDC "Sendeart_Checkcontrol_VDC";
BA_ "SysSignalName" SG_ 654 TRANF_CC_VDC "TRANF_CC_VDC";
BA_ "CompuMethodName" SG_ 654 ST_IDC_CC_VDC "ST_IDC_CC_VDC";
BA_ "ISignalName" SG_ 654 ST_IDC_CC_VDC "ST_IDC_CC_VDC";
BA_ "LongName" SG_ 654 ST_IDC_CC_VDC "Status_Blinken_Checkcontrol_VDC";
BA_ "SysSignalName" SG_ 654 ST_IDC_CC_VDC "ST_IDC_CC_VDC";
BA_ "CompuMethodName" SG_ 728 DISP_CHGNG_I_EFF "DISP_CHGNG_I_EFF";
BA_ "ISignalName" SG_ 728 DISP_CHGNG_I_EFF "DISP_CHGNG_I_EFF";
BA_ "LongName" SG_ 728 DISP_CHGNG_I_EFF "Anzeige_Laden_Strom_Effekt";
BA_ "SysSignalName" SG_ 728 DISP_CHGNG_I_EFF "DISP_CHGNG_I_EFF";
BA_ "CompuMethodName" SG_ 728 DISP_CHGNG_I_LIM_MOD_2 "DISP_CHGNG_I_LIM_MOD_2";
BA_ "ISignalName" SG_ 728 DISP_CHGNG_I_LIM_MOD_2 "DISP_CHGNG_I_LIM_MOD_2";
BA_ "LongName" SG_ 728 DISP_CHGNG_I_LIM_MOD_2 "Anzeige_Laden_Strom_Begrenzung_Modus_2";
BA_ "SysSignalName" SG_ 728 DISP_CHGNG_I_LIM_MOD_2 "DISP_CHGNG_I_LIM_MOD_2";
BA_ "CompuMethodName" SG_ 728 DISP_MAX_CHGNG_I_LIM_MOD_2 "DISP_CHGNG_I_LIM_MOD_2";
BA_ "ISignalName" SG_ 728 DISP_MAX_CHGNG_I_LIM_MOD_2 "DISP_MAX_CHGNG_I_LIM_MOD_2";
BA_ "LongName" SG_ 728 DISP_MAX_CHGNG_I_LIM_MOD_2 "Anzeige_Maximal_Laden_Strom_Begrenzung_Modus_2";
BA_ "SysSignalName" SG_ 728 DISP_MAX_CHGNG_I_LIM_MOD_2 "DISP_MAX_CHGNG_I_LIM_MOD_2";
BA_ "CompuMethodName" SG_ 728 DISP_MIN_CHGNG_I_LIM_MOD_2 "DISP_CHGNG_I_LIM_MOD_2";
BA_ "ISignalName" SG_ 728 DISP_MIN_CHGNG_I_LIM_MOD_2 "DISP_MIN_CHGNG_I_LIM_MOD_2";
BA_ "LongName" SG_ 728 DISP_MIN_CHGNG_I_LIM_MOD_2 "Anzeige_Minimal_Laden_Strom_Begrenzung_Modus_2";
BA_ "SysSignalName" SG_ 728 DISP_MIN_CHGNG_I_LIM_MOD_2 "DISP_MIN_CHGNG_I_LIM_MOD_2";
BA_ "CompuMethodName" SG_ 728 DisplayPowerChargingStatus "DisplayPowerChargingStatus2";
BA_ "ISignalName" SG_ 728 DisplayPowerChargingStatus "DisplayPowerChargingStatus";
BA_ "LongName" SG_ 728 DisplayPowerChargingStatus "DisplayPowerChargingStatus";
BA_ "SysSignalName" SG_ 728 DisplayPowerChargingStatus "DisplayPowerChargingStatus";
BA_ "CompuMethodName" SG_ 728 DisplayRestTimeEndOfChargingStat "DisplayPowerChargingStatus";
BA_ "ISignalName" SG_ 728 DisplayRestTimeEndOfChargingStat "DisplayRestTimeEndOfChargingStatus";
BA_ "LongName" SG_ 728 DisplayRestTimeEndOfChargingStat "DisplayRestTimeEndOfChargingStatus";
BA_ "SysSignalName" SG_ 728 DisplayRestTimeEndOfChargingStat "DisplayRestTimeEndOfChargingStatus";
BA_ "SystemSignalLongSymbol" SG_ 728 DisplayRestTimeEndOfChargingStat "DisplayRestTimeEndOfChargingStatus";
BA_ "CompuMethodName" SG_ 728 DisplayChargingCurrentEffStatus "DisplayPowerChargingStatus";
BA_ "ISignalName" SG_ 728 DisplayChargingCurrentEffStatus "DisplayChargingCurrentEffStatus";
BA_ "LongName" SG_ 728 DisplayChargingCurrentEffStatus "DisplayChargingCurrentEffStatus";
BA_ "SysSignalName" SG_ 728 DisplayChargingCurrentEffStatus "DisplayChargingCurrentEffStatus";
BA_ "CompuMethodName" SG_ 728 DisplayChargingTimeHrStatus "DisplayPowerChargingStatus";
BA_ "ISignalName" SG_ 728 DisplayChargingTimeHrStatus "DisplayChargingTimeHrStatus";
BA_ "LongName" SG_ 728 DisplayChargingTimeHrStatus "DisplayChargingTimeHrStatus";
BA_ "SysSignalName" SG_ 728 DisplayChargingTimeHrStatus "DisplayChargingTimeHrStatus";
BA_ "CompuMethodName" SG_ 728 DisplayChargingTimeMnStatus "DisplayPowerChargingStatus";
BA_ "ISignalName" SG_ 728 DisplayChargingTimeMnStatus "DisplayChargingTimeMnStatus";
BA_ "LongName" SG_ 728 DisplayChargingTimeMnStatus "DisplayChargingTimeMnStatus";
BA_ "SysSignalName" SG_ 728 DisplayChargingTimeMnStatus "DisplayChargingTimeMnStatus";
BA_ "CompuMethodName" SG_ 728 DisplaySoeChargingTargetStatus "DisplayPowerChargingStatus";
BA_ "ISignalName" SG_ 728 DisplaySoeChargingTargetStatus "DisplaySoeChargingTargetStatus";
BA_ "LongName" SG_ 728 DisplaySoeChargingTargetStatus "DisplaySoeChargingTargetStatus";
BA_ "SysSignalName" SG_ 728 DisplaySoeChargingTargetStatus "DisplaySoeChargingTargetStatus";
BA_ "CompuMethodName" SG_ 728 TechnicalSoeChargingPredictionDe "TechnicalSoeChargingPredictionDepartureTime";
BA_ "ISignalName" SG_ 728 TechnicalSoeChargingPredictionDe "TechnicalSoeChargingPredictionDepartureTime";
BA_ "LongName" SG_ 728 TechnicalSoeChargingPredictionDe "TechnicalSoeChargingPredictionDepartureTime";
BA_ "SysSignalName" SG_ 728 TechnicalSoeChargingPredictionDe "TechnicalSoeChargingPredictionDepartureTime";
BA_ "SystemSignalLongSymbol" SG_ 728 TechnicalSoeChargingPredictionDe "TechnicalSoeChargingPredictionDepartureTime";
BA_ "CompuMethodName" SG_ 941 DISP_OPMO_DRV_HYB "DISP_OPMO_DRV_HYB";
BA_ "ISignalName" SG_ 941 DISP_OPMO_DRV_HYB "DISP_OPMO_DRV_HYB";
BA_ "LongName" SG_ 941 DISP_OPMO_DRV_HYB "Anzeige_Betriebsart_Antrieb_Hybrid";
BA_ "SysSignalName" SG_ 941 DISP_OPMO_DRV_HYB "DISP_OPMO_DRV_HYB";
BA_ "CompuMethodName" SG_ 941 DISP_AVL_PWR_REL_RECUP "DISP_AVL_PWR_REL_RECUP";
BA_ "ISignalName" SG_ 941 DISP_AVL_PWR_REL_RECUP "DISP_AVL_PWR_REL_RECUP";
BA_ "LongName" SG_ 941 DISP_AVL_PWR_REL_RECUP "Anzeige_Ist_Leistung_Relativ_Rekuperation";
BA_ "SysSignalName" SG_ 941 DISP_AVL_PWR_REL_RECUP "DISP_AVL_PWR_REL_RECUP";
BA_ "CompuMethodName" SG_ 941 DISP_AVL_PWR_REL_DRVG_EL "DISP_AVL_PWR_REL_RECUP";
BA_ "ISignalName" SG_ 941 DISP_AVL_PWR_REL_DRVG_EL "DISP_AVL_PWR_REL_DRVG_EL";
BA_ "LongName" SG_ 941 DISP_AVL_PWR_REL_DRVG_EL "Anzeige_Ist_Leistung_Relativ_Fahren_Elektrisch";
BA_ "SysSignalName" SG_ 941 DISP_AVL_PWR_REL_DRVG_EL "DISP_AVL_PWR_REL_DRVG_EL";
BA_ "CompuMethodName" SG_ 941 DISP_CHGCOND_HVSTO "DISP_CHGCOND_HVSTO";
BA_ "ISignalName" SG_ 941 DISP_CHGCOND_HVSTO "DISP_CHGCOND_HVSTO";
BA_ "LongName" SG_ 941 DISP_CHGCOND_HVSTO "Anzeige_Ladezustand_Hochvoltspeicher";
BA_ "SysSignalName" SG_ 941 DISP_CHGCOND_HVSTO "DISP_CHGCOND_HVSTO";
BA_ "CompuMethodName" SG_ 941 DISP_HYB_FRSG_SIT "DISP_HYB_FRSG_SIT";
BA_ "ISignalName" SG_ 941 DISP_HYB_FRSG_SIT "DISP_HYB_FRSG_SIT";
BA_ "LongName" SG_ 941 DISP_HYB_FRSG_SIT "Anzeige_Hybrid_Vorausschau_Situation";
BA_ "SysSignalName" SG_ 941 DISP_HYB_FRSG_SIT "DISP_HYB_FRSG_SIT";
BA_ "CompuMethodName" SG_ 941 DISP_HYB_FRSG_DIST "DISP_HYB_FRSG_DIST";
BA_ "ISignalName" SG_ 941 DISP_HYB_FRSG_DIST "DISP_HYB_FRSG_DIST";
BA_ "LongName" SG_ 941 DISP_HYB_FRSG_DIST "Anzeige_Hybrid_Vorausschau_Distanz";
BA_ "SysSignalName" SG_ 941 DISP_HYB_FRSG_DIST "DISP_HYB_FRSG_DIST";
BA_ "CompuMethodName" SG_ 941 ALIV_DISP_CON_HYB "ALIV_4_BIT_Unsigned_Integer";
BA_ "ISignalName" SG_ 941 ALIV_DISP_CON_HYB "ALIV_DISP_CON_HYB";
BA_ "LongName" SG_ 941 ALIV_DISP_CON_HYB "Alive_Anzeige_Zustand_Hybrid";
BA_ "SysSignalName" SG_ 941 ALIV_DISP_CON_HYB "ALIV_DISP_CON_HYB";
BA_ "CompuMethodName" SG_ 1036 DISP_EFFS_HYB "DISP_EFFS_HYB";
BA_ "ISignalName" SG_ 1036 DISP_EFFS_HYB "DISP_EFFS_HYB";
BA_ "LongName" SG_ 1036 DISP_EFFS_HYB "Anzeige_Effektivität_Hybrid";
BA_ "SysSignalName" SG_ 1036 DISP_EFFS_HYB "DISP_EFFS_HYB";
BA_ "CompuMethodName" SG_ 796 CRC_DISP_DRASY "CRC8";
BA_ "ISignalName" SG_ 796 CRC_DISP_DRASY "CRC_DISP_DRASY";
BA_ "LongName" SG_ 796 CRC_DISP_DRASY "CRC_Anzeige_Fahrerassistenzsystem";
BA_ "SysSignalName" SG_ 796 CRC_DISP_DRASY "CRC_DISP_DRASY";
BA_ "CompuMethodName" SG_ 796 ALIV_DISP_DRASY "Aliv_4";
BA_ "ISignalName" SG_ 796 ALIV_DISP_DRASY "ALIV_DISP_DRASY";
BA_ "LongName" SG_ 796 ALIV_DISP_DRASY "Alive_Anzeige_Fahrerassistenzsystem";
BA_ "SysSignalName" SG_ 796 ALIV_DISP_DRASY "ALIV_DISP_DRASY";
BA_ "ISignalName" SG_ 796 DISP_DRASY_dummy_12_13 "DISP_DRASY_dummy_12_13";
BA_ "LongName" SG_ 796 DISP_DRASY_dummy_12_13 "DISP_DRASY_dummy_12_13";
BA_ "SysSignalName" SG_ 796 DISP_DRASY_dummy_12_13 "DISP_DRASY_dummy_12_13";
BA_ "CompuMethodName" SG_ 796 RQ_ACTV_PFGS "RQ_ACTV_PFGS";
BA_ "ISignalName" SG_ 796 RQ_ACTV_PFGS "RQ_ACTV_PFGS";
BA_ "LongName" SG_ 796 RQ_ACTV_PFGS "Anforderung_Aktivieren_pFGS";
BA_ "SysSignalName" SG_ 796 RQ_ACTV_PFGS "RQ_ACTV_PFGS";
BA_ "ISignalName" SG_ 796 DISP_DRASY_dummy_16_31 "DISP_DRASY_dummy_16_31";
BA_ "LongName" SG_ 796 DISP_DRASY_dummy_16_31 "DISP_DRASY_dummy_16_31";
BA_ "SysSignalName" SG_ 796 DISP_DRASY_dummy_16_31 "DISP_DRASY_dummy_16_31";
BA_ "CompuMethodName" SG_ 796 QU_FN_EDP "QU_FN_EDP";
BA_ "ISignalName" SG_ 796 QU_FN_EDP "QU_FN_EDP";
BA_ "LongName" SG_ 796 QU_FN_EDP "Qualifier_Funktion_Efficient-Dynamics-Pilot";
BA_ "SysSignalName" SG_ 796 QU_FN_EDP "QU_FN_EDP";
BA_ "CompuMethodName" SG_ 796 RQ_ACTV_SCW "RQ_ACTV_SCW";
BA_ "ISignalName" SG_ 796 RQ_ACTV_SCW "RQ_ACTV_SCW";
BA_ "LongName" SG_ 796 RQ_ACTV_SCW "Anforderung_Aktivieren_Seitenkollisionswarnung";
BA_ "SysSignalName" SG_ 796 RQ_ACTV_SCW "RQ_ACTV_SCW";
BA_ "CompuMethodName" SG_ 796 RQ_ACTV_WARN_LNCH "RQ_ACTV_WARN_LNCH";
BA_ "ISignalName" SG_ 796 RQ_ACTV_WARN_LNCH "RQ_ACTV_WARN_LNCH";
BA_ "LongName" SG_ 796 RQ_ACTV_WARN_LNCH "Anforderung_Aktivieren_Warnung_Fahrspurwechsel";
BA_ "SysSignalName" SG_ 796 RQ_ACTV_WARN_LNCH "RQ_ACTV_WARN_LNCH";
BA_ "CompuMethodName" SG_ 796 CTR_CL_STW_DRS "CTR_CL_STW_DRS";
BA_ "ISignalName" SG_ 796 CTR_CL_STW_DRS "CTR_CL_STW_DRS";
BA_ "LongName" SG_ 796 CTR_CL_STW_DRS "Steuerung_Farbe_Lenkrad_FAS";
BA_ "SysSignalName" SG_ 796 CTR_CL_STW_DRS "CTR_CL_STW_DRS";
BA_ "CompuMethodName" SG_ 796 CTR_FOM_STW_DRS "CTR_FOM_STW_DRS";
BA_ "ISignalName" SG_ 796 CTR_FOM_STW_DRS "CTR_FOM_STW_DRS";
BA_ "LongName" SG_ 796 CTR_FOM_STW_DRS "Steuerung_Form_Lenkrad_FAS";
BA_ "SysSignalName" SG_ 796 CTR_FOM_STW_DRS "CTR_FOM_STW_DRS";
BA_ "CompuMethodName" SG_ 796 ST_SFN_SLA_FRSG "ST_SFN_SLA_FRSG";
BA_ "ISignalName" SG_ 796 ST_SFN_SLA_FRSG "ST_SFN_SLA_FRSG";
BA_ "LongName" SG_ 796 ST_SFN_SLA_FRSG "Status_Teilfunktion_SLA_Vorausschau";
BA_ "SysSignalName" SG_ 796 ST_SFN_SLA_FRSG "ST_SFN_SLA_FRSG";
BA_ "CompuMethodName" SG_ 796 ST_SFN_SLA_MOD "ST_SFN_SLA_FRSG";
BA_ "ISignalName" SG_ 796 ST_SFN_SLA_MOD "ST_SFN_SLA_MOD";
BA_ "LongName" SG_ 796 ST_SFN_SLA_MOD "status_subfunction_SLA_mode";
BA_ "SysSignalName" SG_ 796 ST_SFN_SLA_MOD "ST_SFN_SLA_MOD";
BA_ "CompuMethodName" SG_ 796 ST_SFN_SLA_FRSG_STREET "ST_SFN_SLA_FRSG";
BA_ "ISignalName" SG_ 796 ST_SFN_SLA_FRSG_STREET "ST_SFN_SLA_FRSG_STREET";
BA_ "LongName" SG_ 796 ST_SFN_SLA_FRSG_STREET "Status_Teilfunktion_SLA_Vorausschau_Straße";
BA_ "SysSignalName" SG_ 796 ST_SFN_SLA_FRSG_STREET "ST_SFN_SLA_FRSG_STREET";
BA_ "CompuMethodName" SG_ 796 ST_SFN_UCC "ST_SFN_UCC";
BA_ "ISignalName" SG_ 796 ST_SFN_UCC "ST_SFN_UCC";
BA_ "LongName" SG_ 796 ST_SFN_UCC "Status_Teilfunktion_UCC";
BA_ "SysSignalName" SG_ 796 ST_SFN_UCC "ST_SFN_UCC";
BA_ "CompuMethodName" SG_ 796 ST_AVAI_QMAN "ST_AVAI_QMAN";
BA_ "ISignalName" SG_ 796 ST_AVAI_QMAN "ST_AVAI_QMAN";
BA_ "LongName" SG_ 796 ST_AVAI_QMAN "Status_Verfügbarkeit_QMAN";
BA_ "SysSignalName" SG_ 796 ST_AVAI_QMAN "ST_AVAI_QMAN";
BA_ "ISignalName" SG_ 796 DISP_DRASY_dummy_58_63 "DISP_DRASY_dummy_58_63";
BA_ "LongName" SG_ 796 DISP_DRASY_dummy_58_63 "DISP_DRASY_dummy_58_63";
BA_ "SysSignalName" SG_ 796 DISP_DRASY_dummy_58_63 "DISP_DRASY_dummy_58_63";
BA_ "CompuMethodName" SG_ 515 CRC_DISP_DRASY_LAG "CRC8";
BA_ "ISignalName" SG_ 515 CRC_DISP_DRASY_LAG "CRC_DISP_DRASY_LAG";
BA_ "LongName" SG_ 515 CRC_DISP_DRASY_LAG "CRC_Anzeige_Fahrerassistenzsystem_Querführung";
BA_ "SysSignalName" SG_ 515 CRC_DISP_DRASY_LAG "CRC_DISP_DRASY_LAG";
BA_ "CompuMethodName" SG_ 515 ALIV_DISP_DRASY_LAG "ALIV_4_BIT_Unsigned_Integer";
BA_ "ISignalName" SG_ 515 ALIV_DISP_DRASY_LAG "ALIV_DISP_DRASY_LAG";
BA_ "LongName" SG_ 515 ALIV_DISP_DRASY_LAG "Alive_Anzeige_Fahrerassistenzsystem_Querführung";
BA_ "SysSignalName" SG_ 515 ALIV_DISP_DRASY_LAG "ALIV_DISP_DRASY_LAG";
BA_ "CompuMethodName" SG_ 515 CHL_DISP_DRASY_LAG "CHL_4_UInt";
BA_ "ISignalName" SG_ 515 CHL_DISP_DRASY_LAG "CHL_DISP_DRASY_LAG";
BA_ "LongName" SG_ 515 CHL_DISP_DRASY_LAG "CHL_Anzeige_Fahrerassistenzsystem_Querführung";
BA_ "SysSignalName" SG_ 515 CHL_DISP_DRASY_LAG "CHL_DISP_DRASY_LAG";
BA_ "CompuMethodName" SG_ 515 DISP_LAG_LNMR "DISP_LAG_LNMR";
BA_ "ISignalName" SG_ 515 DISP_LAG_LNMR "DISP_LAG_LNMR";
BA_ "LongName" SG_ 515 DISP_LAG_LNMR "Anzeige_Querführung_Fahrspurmarkierung";
BA_ "SysSignalName" SG_ 515 DISP_LAG_LNMR "DISP_LAG_LNMR";
BA_ "CompuMethodName" SG_ 515 DISP_LAG_FRVEH "DISP_LAG_FRVEH";
BA_ "ISignalName" SG_ 515 DISP_LAG_FRVEH "DISP_LAG_FRVEH";
BA_ "LongName" SG_ 515 DISP_LAG_FRVEH "Anzeige_Querführung_Vorderfahrzeug";
BA_ "SysSignalName" SG_ 515 DISP_LAG_FRVEH "DISP_LAG_FRVEH";
BA_ "CompuMethodName" SG_ 515 DISP_LAG_STW "DISP_LAG_STW";
BA_ "ISignalName" SG_ 515 DISP_LAG_STW "DISP_LAG_STW";
BA_ "LongName" SG_ 515 DISP_LAG_STW "Anzeige_Querführung_Lenkrad";
BA_ "SysSignalName" SG_ 515 DISP_LAG_STW "DISP_LAG_STW";
BA_ "CompuMethodName" SG_ 515 DISP_LAG_STINTV "DISP_LAG_STINTV";
BA_ "ISignalName" SG_ 515 DISP_LAG_STINTV "DISP_LAG_STINTV";
BA_ "LongName" SG_ 515 DISP_LAG_STINTV "Anzeige_Querführung_Lenkeingriff";
BA_ "SysSignalName" SG_ 515 DISP_LAG_STINTV "DISP_LAG_STINTV";
BA_ "CompuMethodName" SG_ 515 DISP_LAG_ARRWS "DISP_LAG_ARRWS";
BA_ "ISignalName" SG_ 515 DISP_LAG_ARRWS "DISP_LAG_ARRWS";
BA_ "LongName" SG_ 515 DISP_LAG_ARRWS "Anzeige_Querführung_Pfeile";
BA_ "SysSignalName" SG_ 515 DISP_LAG_ARRWS "DISP_LAG_ARRWS";
BA_ "CompuMethodName" SG_ 515 DISP_LAG_NAPA "DISP_LAG_NAPA";
BA_ "ISignalName" SG_ 515 DISP_LAG_NAPA "DISP_LAG_NAPA";
BA_ "LongName" SG_ 515 DISP_LAG_NAPA "Anzeige_Querführung_Engstellenassistent";
BA_ "SysSignalName" SG_ 515 DISP_LAG_NAPA "DISP_LAG_NAPA";
BA_ "CompuMethodName" SG_ 515 DISP_LAG_ARRWS_TYP "DISP_LAG_ARRWS_TYP";
BA_ "ISignalName" SG_ 515 DISP_LAG_ARRWS_TYP "DISP_LAG_ARRWS_TYP";
BA_ "LongName" SG_ 515 DISP_LAG_ARRWS_TYP "Anzeige_Querführung_Pfeile_Typ";
BA_ "SysSignalName" SG_ 515 DISP_LAG_ARRWS_TYP "DISP_LAG_ARRWS_TYP";
BA_ "ISignalName" SG_ 515 DISP_DRASY_LAG_dummy_62_63 "DISP_DRASY_LAG_dummy_62_63";
BA_ "LongName" SG_ 515 DISP_DRASY_LAG_dummy_62_63 "DISP_DRASY_LAG_dummy_62_63";
BA_ "SysSignalName" SG_ 515 DISP_DRASY_LAG_dummy_62_63 "DISP_DRASY_LAG_dummy_62_63";
BA_ "CompuMethodName" SG_ 541 DISP_LAG_STW_SYM "DISP_LAG_STW_SYM";
BA_ "ISignalName" SG_ 541 DISP_LAG_STW_SYM "DISP_LAG_STW_SYM";
BA_ "LongName" SG_ 541 DISP_LAG_STW_SYM "display_lateral-guidance_steering-wheel_symbol";
BA_ "SysSignalName" SG_ 541 DISP_LAG_STW_SYM "DISP_LAG_STW_SYM";
BA_ "CompuMethodName" SG_ 541 DISP_LAG_TAO_SYM "DISP_LAG_TAO_SYM";
BA_ "ISignalName" SG_ 541 DISP_LAG_TAO_SYM "DISP_LAG_TAO_SYM";
BA_ "LongName" SG_ 541 DISP_LAG_TAO_SYM "Anzeige_Querführung_Übernahme_Symbol";
BA_ "SysSignalName" SG_ 541 DISP_LAG_TAO_SYM "DISP_LAG_TAO_SYM";
BA_ "CompuMethodName" SG_ 541 RQ_LAG_SOU "RQ_LAG_SOU";
BA_ "ISignalName" SG_ 541 RQ_LAG_SOU "RQ_LAG_SOU";
BA_ "LongName" SG_ 541 RQ_LAG_SOU "Anforderung_Querführung_Ton";
BA_ "SysSignalName" SG_ 541 RQ_LAG_SOU "RQ_LAG_SOU";
BA_ "CompuMethodName" SG_ 541 IDC_LAG_STW_SYM "IDC_LAG_STW_SYM";
BA_ "ISignalName" SG_ 541 IDC_LAG_STW_SYM "IDC_LAG_STW_SYM";
BA_ "LongName" SG_ 541 IDC_LAG_STW_SYM "Blinken_Querführung_Lenkrad_Symbol";
BA_ "SysSignalName" SG_ 541 IDC_LAG_STW_SYM "IDC_LAG_STW_SYM";
BA_ "CompuMethodName" SG_ 541 DISP_LAG_WARN "DISP_LAG_WARN";
BA_ "ISignalName" SG_ 541 DISP_LAG_WARN "DISP_LAG_WARN";
BA_ "LongName" SG_ 541 DISP_LAG_WARN "Anzeige_Querführung_Warnung";
BA_ "SysSignalName" SG_ 541 DISP_LAG_WARN "DISP_LAG_WARN";
BA_ "CompuMethodName" SG_ 541 DISP_PREP_LNCH "DISP_PREP_LNCH";
BA_ "ISignalName" SG_ 541 DISP_PREP_LNCH "DISP_PREP_LNCH";
BA_ "LongName" SG_ 541 DISP_PREP_LNCH "Anzeige_Vorbereitung_Fahrspurwechsel";
BA_ "SysSignalName" SG_ 541 DISP_PREP_LNCH "DISP_PREP_LNCH";
BA_ "CompuMethodName" SG_ 451 CRC_DISP_DRASY_LNG "CRC8";
BA_ "ISignalName" SG_ 451 CRC_DISP_DRASY_LNG "CRC_DISP_DRASY_LNG";
BA_ "LongName" SG_ 451 CRC_DISP_DRASY_LNG "CRC_Anzeige_Fahrerassistenzsystem_Längsführung";
BA_ "SysSignalName" SG_ 451 CRC_DISP_DRASY_LNG "CRC_DISP_DRASY_LNG";
BA_ "CompuMethodName" SG_ 451 ALIV_DISP_DRASY_LNG "ALIV_4_BIT_Unsigned_Integer";
BA_ "ISignalName" SG_ 451 ALIV_DISP_DRASY_LNG "ALIV_DISP_DRASY_LNG";
BA_ "LongName" SG_ 451 ALIV_DISP_DRASY_LNG "Alive_Anzeige_Fahrerassistenzsystem_Längsführung";
BA_ "SysSignalName" SG_ 451 ALIV_DISP_DRASY_LNG "ALIV_DISP_DRASY_LNG";
BA_ "CompuMethodName" SG_ 451 CHL_DISP_DRASY_LNG "CHL_4_UInt";
BA_ "ISignalName" SG_ 451 CHL_DISP_DRASY_LNG "CHL_DISP_DRASY_LNG";
BA_ "LongName" SG_ 451 CHL_DISP_DRASY_LNG "CHL_Anzeige_Fahrerassistenzsystem_Längsführung";
BA_ "SysSignalName" SG_ 451 CHL_DISP_DRASY_LNG "CHL_DISP_DRASY_LNG";
BA_ "CompuMethodName" SG_ 451 DISP_XCC "DISP_XCC";
BA_ "ISignalName" SG_ 451 DISP_XCC "DISP_XCC";
BA_ "LongName" SG_ 451 DISP_XCC "Anzeige_XCC";
BA_ "SysSignalName" SG_ 451 DISP_XCC "DISP_XCC";
BA_ "CompuMethodName" SG_ 451 ACV_FN_DRASY_LDM "ACV_FN_DRASY_LDM";
BA_ "ISignalName" SG_ 451 ACV_FN_DRASY_LDM "ACV_FN_DRASY_LDM";
BA_ "LongName" SG_ 451 ACV_FN_DRASY_LDM "Aktiv_Funktion_Fahrerassistenzsystem_LDM";
BA_ "SysSignalName" SG_ 451 ACV_FN_DRASY_LDM "ACV_FN_DRASY_LDM";
BA_ "CompuMethodName" SG_ 451 DISP_SD "DISP_SD";
BA_ "ISignalName" SG_ 451 DISP_SD "DISP_SD";
BA_ "LongName" SG_ 451 DISP_SD "Anzeige_SLD";
BA_ "SysSignalName" SG_ 451 DISP_SD "DISP_SD";
BA_ "CompuMethodName" SG_ 451 ST_ISA_2 "ST_ISA";
BA_ "ISignalName" SG_ 451 ST_ISA_2 "ST_ISA_2";
BA_ "LongName" SG_ 451 ST_ISA_2 "Status_ISA_2";
BA_ "SysSignalName" SG_ 451 ST_ISA_2 "ST_ISA_2";
BA_ "CompuMethodName" SG_ 451 DISP_GAPC_MOD "display_gap_choice_mode";
BA_ "ISignalName" SG_ 451 DISP_GAPC_MOD "DISP_GAPC_MOD";
BA_ "LongName" SG_ 451 DISP_GAPC_MOD "Anzeige_Abstandswahl_Modus";
BA_ "SysSignalName" SG_ 451 DISP_GAPC_MOD "DISP_GAPC_MOD";
BA_ "CompuMethodName" SG_ 451 DISP_HDC "DISP_HDC";
BA_ "ISignalName" SG_ 451 DISP_HDC "DISP_HDC";
BA_ "LongName" SG_ 451 DISP_HDC "Anzeige_HDC";
BA_ "SysSignalName" SG_ 451 DISP_HDC "DISP_HDC";
BA_ "CompuMethodName" SG_ 451 DISP_GAP_INFO "DISP_GAP_INFO";
BA_ "ISignalName" SG_ 451 DISP_GAP_INFO "DISP_GAP_INFO";
BA_ "LongName" SG_ 451 DISP_GAP_INFO "Anzeige_Abstand_Information";
BA_ "SysSignalName" SG_ 451 DISP_GAP_INFO "DISP_GAP_INFO";
BA_ "CompuMethodName" SG_ 451 DISP_GAPC "DISP_GAPC";
BA_ "ISignalName" SG_ 451 DISP_GAPC "DISP_GAPC";
BA_ "LongName" SG_ 451 DISP_GAPC "Anzeige_Abstandswahl";
BA_ "SysSignalName" SG_ 451 DISP_GAPC "DISP_GAPC";
BA_ "CompuMethodName" SG_ 451 DISP_RQSP "DISP_RQSP";
BA_ "ISignalName" SG_ 451 DISP_RQSP "DISP_RQSP";
BA_ "LongName" SG_ 451 DISP_RQSP "Anzeige_Wunschgeschwindigkeit";
BA_ "SysSignalName" SG_ 451 DISP_RQSP "DISP_RQSP";
BA_ "CompuMethodName" SG_ 451 VL_RQSP "VL_RQSP";
BA_ "ISignalName" SG_ 451 VL_RQSP "VL_RQSP";
BA_ "LongName" SG_ 451 VL_RQSP "Wert_Wunschgeschwindigkeit";
BA_ "SysSignalName" SG_ 451 VL_RQSP "VL_RQSP";
BA_ "CompuMethodName" SG_ 477 DISP_V_SUG_2 "DISP_V_SUG_2";
BA_ "GenSigStartValue" SG_ 477 DISP_V_SUG_2 1;
BA_ "ISignalName" SG_ 477 DISP_V_SUG_2 "DISP_V_SUG_2";
BA_ "LongName" SG_ 477 DISP_V_SUG_2 "Anzeige_Geschwindigkeit_Vorschlag_2";
BA_ "SysSignalName" SG_ 477 DISP_V_SUG_2 "DISP_V_SUG_2";
BA_ "CompuMethodName" SG_ 477 DISP_OFFS_BOT_SAIL_2 "DISP_OFFS_SAIL_2";
BA_ "ISignalName" SG_ 477 DISP_OFFS_BOT_SAIL_2 "DISP_OFFS_BOT_SAIL_2";
BA_ "LongName" SG_ 477 DISP_OFFS_BOT_SAIL_2 "Anzeige_Offset_Unten_Segeln_2";
BA_ "SysSignalName" SG_ 477 DISP_OFFS_BOT_SAIL_2 "DISP_OFFS_BOT_SAIL_2";
BA_ "CompuMethodName" SG_ 477 DISP_OFFS_TOP_SAIL_2 "DISP_OFFS_SAIL_2";
BA_ "ISignalName" SG_ 477 DISP_OFFS_TOP_SAIL_2 "DISP_OFFS_TOP_SAIL_2";
BA_ "LongName" SG_ 477 DISP_OFFS_TOP_SAIL_2 "Anzeige_Offset_Oben_Segeln_2";
BA_ "SysSignalName" SG_ 477 DISP_OFFS_TOP_SAIL_2 "DISP_OFFS_TOP_SAIL_2";
BA_ "CompuMethodName" SG_ 477 DISP_SAILA "DISP_SAILA";
BA_ "ISignalName" SG_ 477 DISP_SAILA "DISP_SAILA";
BA_ "LongName" SG_ 477 DISP_SAILA "Anzeige_Segelflaeche";
BA_ "SysSignalName" SG_ 477 DISP_SAILA "DISP_SAILA";
BA_ "CompuMethodName" SG_ 477 DisplayTakeOverRequestReason "DisplayTakeOverRequestReason";
BA_ "ISignalName" SG_ 477 DisplayTakeOverRequestReason "DisplayTakeOverRequestReason";
BA_ "LongName" SG_ 477 DisplayTakeOverRequestReason "DisplayTakeOverRequestReason";
BA_ "SysSignalName" SG_ 477 DisplayTakeOverRequestReason "DisplayTakeOverRequestReason";
BA_ "CompuMethodName" SG_ 479 DISP_FAS_MOD_MNU "DISP_FAS_MOD_MNU";
BA_ "ISignalName" SG_ 479 DISP_FAS_MOD_MNU "DISP_FAS_MOD_MNU";
BA_ "LongName" SG_ 479 DISP_FAS_MOD_MNU "Anzeige_Fahrerassistenz_Modus_Menü";
BA_ "SysSignalName" SG_ 479 DISP_FAS_MOD_MNU "DISP_FAS_MOD_MNU";
BA_ "CompuMethodName" SG_ 479 DISP_FAS_MOD_CURS "DISP_FAS_MOD_CURS";
BA_ "ISignalName" SG_ 479 DISP_FAS_MOD_CURS "DISP_FAS_MOD_CURS";
BA_ "LongName" SG_ 479 DISP_FAS_MOD_CURS "Anzeige_Fahrerassistenz_Modus_Cursor";
BA_ "SysSignalName" SG_ 479 DISP_FAS_MOD_CURS "DISP_FAS_MOD_CURS";
BA_ "CompuMethodName" SG_ 479 DISP_FAS_MOD_1 "DISP_FAS_MOD_1_6";
BA_ "ISignalName" SG_ 479 DISP_FAS_MOD_1 "DISP_FAS_MOD_1";
BA_ "LongName" SG_ 479 DISP_FAS_MOD_1 "Anzeige_Fahrerassistenz_Modus_1";
BA_ "SysSignalName" SG_ 479 DISP_FAS_MOD_1 "DISP_FAS_MOD_1";
BA_ "CompuMethodName" SG_ 479 DISP_FAS_MOD_2 "DISP_FAS_MOD_1_6";
BA_ "ISignalName" SG_ 479 DISP_FAS_MOD_2 "DISP_FAS_MOD_2";
BA_ "LongName" SG_ 479 DISP_FAS_MOD_2 "Anzeige_Fahrerassistenz_Modus_2";
BA_ "SysSignalName" SG_ 479 DISP_FAS_MOD_2 "DISP_FAS_MOD_2";
BA_ "CompuMethodName" SG_ 479 DISP_FAS_MOD_3 "DISP_FAS_MOD_1_6";
BA_ "ISignalName" SG_ 479 DISP_FAS_MOD_3 "DISP_FAS_MOD_3";
BA_ "LongName" SG_ 479 DISP_FAS_MOD_3 "display_driver-assistence_mode_3";
BA_ "SysSignalName" SG_ 479 DISP_FAS_MOD_3 "DISP_FAS_MOD_3";
BA_ "CompuMethodName" SG_ 479 DISP_FAS_MOD_4 "DISP_FAS_MOD_1_6";
BA_ "ISignalName" SG_ 479 DISP_FAS_MOD_4 "DISP_FAS_MOD_4";
BA_ "LongName" SG_ 479 DISP_FAS_MOD_4 "Anzeige_Fahrerassistenz_Modus_4";
BA_ "SysSignalName" SG_ 479 DISP_FAS_MOD_4 "DISP_FAS_MOD_4";
BA_ "CompuMethodName" SG_ 479 DISP_FAS_MOD_5 "DISP_FAS_MOD_1_6";
BA_ "ISignalName" SG_ 479 DISP_FAS_MOD_5 "DISP_FAS_MOD_5";
BA_ "LongName" SG_ 479 DISP_FAS_MOD_5 "Anzeige_Fahrerassistenz_Modus_5";
BA_ "SysSignalName" SG_ 479 DISP_FAS_MOD_5 "DISP_FAS_MOD_5";
BA_ "CompuMethodName" SG_ 479 DISP_FAS_MOD_6 "DISP_FAS_MOD_1_6";
BA_ "ISignalName" SG_ 479 DISP_FAS_MOD_6 "DISP_FAS_MOD_6";
BA_ "LongName" SG_ 479 DISP_FAS_MOD_6 "Anzeige_Fahrerassistenz_Modus_6";
BA_ "SysSignalName" SG_ 479 DISP_FAS_MOD_6 "DISP_FAS_MOD_6";
BA_ "CompuMethodName" SG_ 479 DISP_VL_OFFS_V_LIM "DISP_VL_OFFS_V_LIM";
BA_ "GenSigStartValue" SG_ 479 DISP_VL_OFFS_V_LIM 30;
BA_ "ISignalName" SG_ 479 DISP_VL_OFFS_V_LIM "DISP_VL_OFFS_V_LIM";
BA_ "LongName" SG_ 479 DISP_VL_OFFS_V_LIM "Anzeige_Wert_Offset_Geschwindigkeit_Begrenzung";
BA_ "SysSignalName" SG_ 479 DISP_VL_OFFS_V_LIM "DISP_VL_OFFS_V_LIM";
BA_ "CompuMethodName" SG_ 868 DRVBH_ECO_CTG_1 "DRVBH_ECO_CTG_1";
BA_ "ISignalName" SG_ 868 DRVBH_ECO_CTG_1 "DRVBH_ECO_CTG_1";
BA_ "LongName" SG_ 868 DRVBH_ECO_CTG_1 "Fahrstil_ECO_Kategorie_1";
BA_ "SysSignalName" SG_ 868 DRVBH_ECO_CTG_1 "DRVBH_ECO_CTG_1";
BA_ "CompuMethodName" SG_ 868 DRVBH_ECO_CTG_2 "DRVBH_ECO_CTG_2";
BA_ "ISignalName" SG_ 868 DRVBH_ECO_CTG_2 "DRVBH_ECO_CTG_2";
BA_ "LongName" SG_ 868 DRVBH_ECO_CTG_2 "Fahrstil_ECO_Kategorie_2";
BA_ "SysSignalName" SG_ 868 DRVBH_ECO_CTG_2 "DRVBH_ECO_CTG_2";
BA_ "CompuMethodName" SG_ 868 DRVBH_ECO_CTG_3 "DRVBH_ECO_CTG_3";
BA_ "ISignalName" SG_ 868 DRVBH_ECO_CTG_3 "DRVBH_ECO_CTG_3";
BA_ "LongName" SG_ 868 DRVBH_ECO_CTG_3 "Fahrstil_ECO_Kategorie_3";
BA_ "SysSignalName" SG_ 868 DRVBH_ECO_CTG_3 "DRVBH_ECO_CTG_3";
BA_ "CompuMethodName" SG_ 868 DRVBH_ECO_CTG_1_ST "DRVBH_ECO_CTG_1_ST";
BA_ "ISignalName" SG_ 868 DRVBH_ECO_CTG_1_ST "DRVBH_ECO_CTG_1_ST";
BA_ "LongName" SG_ 868 DRVBH_ECO_CTG_1_ST "Fahrstil_ECO_Kategorie_1_Status";
BA_ "SysSignalName" SG_ 868 DRVBH_ECO_CTG_1_ST "DRVBH_ECO_CTG_1_ST";
BA_ "CompuMethodName" SG_ 868 DRVBH_ECO_CTG_2_ST "DRVBH_ECO_CTG_2_ST";
BA_ "ISignalName" SG_ 868 DRVBH_ECO_CTG_2_ST "DRVBH_ECO_CTG_2_ST";
BA_ "LongName" SG_ 868 DRVBH_ECO_CTG_2_ST "Fahrstil_ECO_Kategorie_2_Status";
BA_ "SysSignalName" SG_ 868 DRVBH_ECO_CTG_2_ST "DRVBH_ECO_CTG_2_ST";
BA_ "CompuMethodName" SG_ 868 DRVBH_ECO_CTG_3_ST "DRVBH_ECO_CTG_3_ST";
BA_ "ISignalName" SG_ 868 DRVBH_ECO_CTG_3_ST "DRVBH_ECO_CTG_3_ST";
BA_ "LongName" SG_ 868 DRVBH_ECO_CTG_3_ST "Fahrstil_ECO_Kategorie_3_Status";
BA_ "SysSignalName" SG_ 868 DRVBH_ECO_CTG_3_ST "DRVBH_ECO_CTG_3_ST";
BA_ "CompuMethodName" SG_ 868 DISP_MILE_SAIL "DISP_MILE_SAIL";
BA_ "ISignalName" SG_ 868 DISP_MILE_SAIL "DISP_MILE_SAIL";
BA_ "LongName" SG_ 868 DISP_MILE_SAIL "Anzeige_Wegstrecke_Segeln";
BA_ "SysSignalName" SG_ 868 DISP_MILE_SAIL "DISP_MILE_SAIL";
BA_ "CompuMethodName" SG_ 1066 DRVBH_2_CTG_1 "DRVBH_2_CTG";
BA_ "ISignalName" SG_ 1066 DRVBH_2_CTG_1 "DRVBH_2_CTG_1";
BA_ "LongName" SG_ 1066 DRVBH_2_CTG_1 "Fahrstil_2_Kategorie_1";
BA_ "SysSignalName" SG_ 1066 DRVBH_2_CTG_1 "DRVBH_2_CTG_1";
BA_ "CompuMethodName" SG_ 1066 DRVBH_2_CTG_2 "DRVBH_2_CTG";
BA_ "ISignalName" SG_ 1066 DRVBH_2_CTG_2 "DRVBH_2_CTG_2";
BA_ "LongName" SG_ 1066 DRVBH_2_CTG_2 "Fahrstil_2_Kategorie_2";
BA_ "SysSignalName" SG_ 1066 DRVBH_2_CTG_2 "DRVBH_2_CTG_2";
BA_ "CompuMethodName" SG_ 1066 DRVBH_2_CTG_3 "DRVBH_2_CTG";
BA_ "ISignalName" SG_ 1066 DRVBH_2_CTG_3 "DRVBH_2_CTG_3";
BA_ "LongName" SG_ 1066 DRVBH_2_CTG_3 "Fahrstil_2_Kategorie_3";
BA_ "SysSignalName" SG_ 1066 DRVBH_2_CTG_3 "DRVBH_2_CTG_3";
BA_ "CompuMethodName" SG_ 1066 DRVBH_2_CTG_1_ST "DRVBH_2_CTG_ST";
BA_ "ISignalName" SG_ 1066 DRVBH_2_CTG_1_ST "DRVBH_2_CTG_1_ST";
BA_ "LongName" SG_ 1066 DRVBH_2_CTG_1_ST "Fahrstil_2_Kategorie_1_Status";
BA_ "SysSignalName" SG_ 1066 DRVBH_2_CTG_1_ST "DRVBH_2_CTG_1_ST";
BA_ "CompuMethodName" SG_ 1066 DRVBH_2_CTG_2_ST "DRVBH_2_CTG_ST";
BA_ "ISignalName" SG_ 1066 DRVBH_2_CTG_2_ST "DRVBH_2_CTG_2_ST";
BA_ "LongName" SG_ 1066 DRVBH_2_CTG_2_ST "Fahrstil_2_Kategorie_2_Status";
BA_ "SysSignalName" SG_ 1066 DRVBH_2_CTG_2_ST "DRVBH_2_CTG_2_ST";
BA_ "CompuMethodName" SG_ 1066 DRVBH_2_CTG_3_ST "DRVBH_2_CTG_ST";
BA_ "ISignalName" SG_ 1066 DRVBH_2_CTG_3_ST "DRVBH_2_CTG_3_ST";
BA_ "LongName" SG_ 1066 DRVBH_2_CTG_3_ST "Fahrstil_2_Kategorie_3_Status";
BA_ "SysSignalName" SG_ 1066 DRVBH_2_CTG_3_ST "DRVBH_2_CTG_3_ST";
BA_ "CompuMethodName" SG_ 1066 DRVBH_2_AVAI "DRVBH_2_AVAI";
BA_ "ISignalName" SG_ 1066 DRVBH_2_AVAI "DRVBH_2_AVAI";
BA_ "LongName" SG_ 1066 DRVBH_2_AVAI "Fahrstil_2_Verfügbarkeit";
BA_ "SysSignalName" SG_ 1066 DRVBH_2_AVAI "DRVBH_2_AVAI";
BA_ "CompuMethodName" SG_ 1066 ECO_TIPS_DISP_2 "ECO_TIPS_DISP_2";
BA_ "ISignalName" SG_ 1066 ECO_TIPS_DISP_2 "ECO_TIPS_DISP_2";
BA_ "LongName" SG_ 1066 ECO_TIPS_DISP_2 "ECO_Tipps_Anzeige_2";
BA_ "SysSignalName" SG_ 1066 ECO_TIPS_DISP_2 "ECO_TIPS_DISP_2";
BA_ "CompuMethodName" SG_ 456 DISP_SYNCN_DT_HVSTO_2 "FBK_HVSTO";
BA_ "ISignalName" SG_ 456 DISP_SYNCN_DT_HVSTO_2 "DISP_SYNCN_DT_HVSTO_2";
BA_ "LongName" SG_ 456 DISP_SYNCN_DT_HVSTO_2 "Anzeige_Synchronisation_Daten_Hochvoltspeicher_2";
BA_ "SysSignalName" SG_ 456 DISP_SYNCN_DT_HVSTO_2 "DISP_SYNCN_DT_HVSTO_2";
BA_ "CompuMethodName" SG_ 456 DISP_MUX_DT_HVSTO_2 "MUX_DT_HVSTO_2";
BA_ "ISignalName" SG_ 456 DISP_MUX_DT_HVSTO_2 "DISP_MUX_DT_HVSTO_2";
BA_ "LongName" SG_ 456 DISP_MUX_DT_HVSTO_2 "Anzeige_Multiplexer_Daten_Hochvoltspeicher_2";
BA_ "SysSignalName" SG_ 456 DISP_MUX_DT_HVSTO_2 "DISP_MUX_DT_HVSTO_2";
BA_ "CompuMethodName" SG_ 456 DISP_PRD_ENERG_CHGCOND_2_COS "PRD_ENERG_CHGCOND_COSP";
BA_ "ISignalName" SG_ 456 DISP_PRD_ENERG_CHGCOND_2_COS "DISP_PRD_ENERG_CHGCOND_2_COS";
BA_ "LongName" SG_ 456 DISP_PRD_ENERG_CHGCOND_2_COS "Anzeige_Voraussage_Energie_Ladezustand_2_Verbraucher";
BA_ "SysSignalName" SG_ 456 DISP_PRD_ENERG_CHGCOND_2_COS "DISP_PRD_ENERG_CHGCOND_2_COS";
BA_ "CompuMethodName" SG_ 456 DISP_ENC_HVSTO_MAX "Energieinhalt_HVSTO_MAX";
BA_ "ISignalName" SG_ 456 DISP_ENC_HVSTO_MAX "DISP_ENC_HVSTO_MAX";
BA_ "LongName" SG_ 456 DISP_ENC_HVSTO_MAX "Anzeige_Energieinhalt_Hochvoltspeicher_Maximal";
BA_ "SysSignalName" SG_ 456 DISP_ENC_HVSTO_MAX "DISP_ENC_HVSTO_MAX";
BA_ "CompuMethodName" SG_ 456 DisplayTempEDriveSystem "DisplayTempEDriveSystem";
BA_ "ISignalName" SG_ 456 DisplayTempEDriveSystem "DisplayTempEDriveSystem";
BA_ "LongName" SG_ 456 DisplayTempEDriveSystem "DisplayTempEDriveSystem";
BA_ "SysSignalName" SG_ 456 DisplayTempEDriveSystem "DisplayTempEDriveSystem";
BA_ "CompuMethodName" SG_ 893 DISP_RMMI_SCRA "DISP_RMMI_SCRA";
BA_ "ISignalName" SG_ 893 DISP_RMMI_SCRA "DISP_RMMI_SCRA";
BA_ "LongName" SG_ 893 DISP_RMMI_SCRA "display_remaining-mileage_SCR-additive";
BA_ "SysSignalName" SG_ 893 DISP_RMMI_SCRA "DISP_RMMI_SCRA";
BA_ "CompuMethodName" SG_ 893 DISP_RFLV_SCRA "DISP_RFLV_SCRA";
BA_ "ISignalName" SG_ 893 DISP_RFLV_SCRA "DISP_RFLV_SCRA";
BA_ "LongName" SG_ 893 DISP_RFLV_SCRA "Anzeige_Nachfüllmenge_SCR-Additiv";
BA_ "SysSignalName" SG_ 893 DISP_RFLV_SCRA "DISP_RFLV_SCRA";
BA_ "CompuMethodName" SG_ 893 DISP_FLLV_SCRA "DISP_FLLV_SCRA";
BA_ "ISignalName" SG_ 893 DISP_FLLV_SCRA "DISP_FLLV_SCRA";
BA_ "LongName" SG_ 893 DISP_FLLV_SCRA "Anzeige_Füllstand_SCR-Additiv";
BA_ "SysSignalName" SG_ 893 DISP_FLLV_SCRA "DISP_FLLV_SCRA";
BA_ "CompuMethodName" SG_ 929 RSDW_DRS_MNV "RSDW_DRS_MNV";
BA_ "ISignalName" SG_ 929 RSDW_DRS_MNV "RSDW_DRS_MNV";
BA_ "LongName" SG_ 929 RSDW_DRS_MNV "Restweg_FAS_Rangieren";
BA_ "SysSignalName" SG_ 929 RSDW_DRS_MNV "RSDW_DRS_MNV";
BA_ "CompuMethodName" SG_ 929 DISP_UN_FACT_DRS_MNV "DISP_UN_FACT_DRS_MNV";
BA_ "ISignalName" SG_ 929 DISP_UN_FACT_DRS_MNV "DISP_UN_FACT_DRS_MNV";
BA_ "LongName" SG_ 929 DISP_UN_FACT_DRS_MNV "Anzeige_Einheit_Faktor_FAS_Rangieren";
BA_ "SysSignalName" SG_ 929 DISP_UN_FACT_DRS_MNV "DISP_UN_FACT_DRS_MNV";
BA_ "CompuMethodName" SG_ 929 MESS_DRS_MNV "MESS_DRS_MNV";
BA_ "ISignalName" SG_ 929 MESS_DRS_MNV "MESS_DRS_MNV";
BA_ "LongName" SG_ 929 MESS_DRS_MNV "Meldung_FAS_Rangieren";
BA_ "SysSignalName" SG_ 929 MESS_DRS_MNV "MESS_DRS_MNV";
BA_ "CompuMethodName" SG_ 929 DISP_SYM_RF_DRS_MNV "DISP_SYM_RF_DRS_MNV";
BA_ "ISignalName" SG_ 929 DISP_SYM_RF_DRS_MNV "DISP_SYM_RF_DRS_MNV";
BA_ "LongName" SG_ 929 DISP_SYM_RF_DRS_MNV "Anzeige_Symbol_Dach_FAS_Rangieren";
BA_ "SysSignalName" SG_ 929 DISP_SYM_RF_DRS_MNV "DISP_SYM_RF_DRS_MNV";
BA_ "CompuMethodName" SG_ 929 PROCS_SYM_DRS_MNV "PROCS_SYM_DRS_MNV";
BA_ "ISignalName" SG_ 929 PROCS_SYM_DRS_MNV "PROCS_SYM_DRS_MNV";
BA_ "LongName" SG_ 929 PROCS_SYM_DRS_MNV "Handlungshinweise_Symbol_FAS_Rangieren";
BA_ "SysSignalName" SG_ 929 PROCS_SYM_DRS_MNV "PROCS_SYM_DRS_MNV";
BA_ "CompuMethodName" SG_ 929 AVL_KNAN_TRAI "AVL_KNAN_TRAI";
BA_ "GenSigStartValue" SG_ 929 AVL_KNAN_TRAI 30;
BA_ "ISignalName" SG_ 929 AVL_KNAN_TRAI "AVL_KNAN_TRAI";
BA_ "LongName" SG_ 929 AVL_KNAN_TRAI "Ist_Knickwinkel_Anhänger";
BA_ "SysSignalName" SG_ 929 AVL_KNAN_TRAI "AVL_KNAN_TRAI";
BA_ "CompuMethodName" SG_ 929 RQ_SOU_ISS_DRS_MNV "RQ_SOU_ISS_DRS_MNV";
BA_ "ISignalName" SG_ 929 RQ_SOU_ISS_DRS_MNV "RQ_SOU_ISS_DRS_MNV";
BA_ "LongName" SG_ 929 RQ_SOU_ISS_DRS_MNV "Anforderung_Ton_Ausgabe_FAS_Rangieren";
BA_ "SysSignalName" SG_ 929 RQ_SOU_ISS_DRS_MNV "RQ_SOU_ISS_DRS_MNV";
BA_ "CompuMethodName" SG_ 929 TAR_KNAN_TRAS "TAR_KNAN_TRAS";
BA_ "GenSigStartValue" SG_ 929 TAR_KNAN_TRAS 30;
BA_ "ISignalName" SG_ 929 TAR_KNAN_TRAS "TAR_KNAN_TRAS";
BA_ "LongName" SG_ 929 TAR_KNAN_TRAS "Soll_Knickwinkel_Anhängerassistent";
BA_ "SysSignalName" SG_ 929 TAR_KNAN_TRAS "TAR_KNAN_TRAS";
BA_ "CompuMethodName" SG_ 929 MAX_KNAN_TRAS "MAX_KNAN_TRAS";
BA_ "GenSigStartValue" SG_ 929 MAX_KNAN_TRAS 30;
BA_ "ISignalName" SG_ 929 MAX_KNAN_TRAS "MAX_KNAN_TRAS";
BA_ "LongName" SG_ 929 MAX_KNAN_TRAS "Maximal_Knickwinkel_Anhängerassistent";
BA_ "SysSignalName" SG_ 929 MAX_KNAN_TRAS "MAX_KNAN_TRAS";
BA_ "CompuMethodName" SG_ 929 RSDW_DRS_MNV_2 "RSDW_DRS_MNV_2";
BA_ "ISignalName" SG_ 929 RSDW_DRS_MNV_2 "RSDW_DRS_MNV_2";
BA_ "LongName" SG_ 929 RSDW_DRS_MNV_2 "Restweg_FAS_Rangieren_2";
BA_ "SysSignalName" SG_ 929 RSDW_DRS_MNV_2 "RSDW_DRS_MNV_2";
BA_ "CompuMethodName" SG_ 630 ST_DISP_FAS_PKG "ST_DISP_FAS_PKG";
BA_ "ISignalName" SG_ 630 ST_DISP_FAS_PKG "ST_DISP_FAS_PKG";
BA_ "LongName" SG_ 630 ST_DISP_FAS_PKG "status_display_driver-assistence_parking";
BA_ "SysSignalName" SG_ 630 ST_DISP_FAS_PKG "ST_DISP_FAS_PKG";
BA_ "CompuMethodName" SG_ 630 RQ_SOU_ISS_FAS_PKG "RQ_SOU_ISS_FAS_PKG";
BA_ "ISignalName" SG_ 630 RQ_SOU_ISS_FAS_PKG "RQ_SOU_ISS_FAS_PKG";
BA_ "LongName" SG_ 630 RQ_SOU_ISS_FAS_PKG "Anforderung_Ton_Ausgabe_Fahrerassistenz_Parken";
BA_ "SysSignalName" SG_ 630 RQ_SOU_ISS_FAS_PKG "RQ_SOU_ISS_FAS_PKG";
BA_ "CompuMethodName" SG_ 630 PROC_FAS_PKG "PROC_FAS_PKG";
BA_ "ISignalName" SG_ 630 PROC_FAS_PKG "PROC_FAS_PKG";
BA_ "LongName" SG_ 630 PROC_FAS_PKG "Handlungshinweis_Fahrerassistenz_Parken";
BA_ "SysSignalName" SG_ 630 PROC_FAS_PKG "PROC_FAS_PKG";
BA_ "CompuMethodName" SG_ 630 ST_PKOF_FAS_PKG "ST_PKOF_FAS_PKG";
BA_ "ISignalName" SG_ 630 ST_PKOF_FAS_PKG "ST_PKOF_FAS_PKG";
BA_ "LongName" SG_ 630 ST_PKOF_FAS_PKG "Status_Parkangebot_Fahrerassistenz_Parken";
BA_ "SysSignalName" SG_ 630 ST_PKOF_FAS_PKG "ST_PKOF_FAS_PKG";
BA_ "CompuMethodName" SG_ 630 DISP_SYM_RF_FAS_PKG "DISP_SYM_RF_FAS_PKG";
BA_ "ISignalName" SG_ 630 DISP_SYM_RF_FAS_PKG "DISP_SYM_RF_FAS_PKG";
BA_ "LongName" SG_ 630 DISP_SYM_RF_FAS_PKG "Anzeige_Symbol_Dach_Fahrerassistenz_Parken";
BA_ "SysSignalName" SG_ 630 DISP_SYM_RF_FAS_PKG "DISP_SYM_RF_FAS_PKG";
BA_ "CompuMethodName" SG_ 630 ST_SOU_FAS_PKG "ST_SOU_FAS_PKG";
BA_ "ISignalName" SG_ 630 ST_SOU_FAS_PKG "ST_SOU_FAS_PKG";
BA_ "LongName" SG_ 630 ST_SOU_FAS_PKG "Status_Ton_Fahrerassistenz_Parken";
BA_ "SysSignalName" SG_ 630 ST_SOU_FAS_PKG "ST_SOU_FAS_PKG";
BA_ "CompuMethodName" SG_ 748 DISP_OP_TAO_SUG_V_FRSG "DISP_OP_TAO_SUG_V_FRSG";
BA_ "ISignalName" SG_ 748 DISP_OP_TAO_SUG_V_FRSG "DISP_OP_TAO_SUG_V_FRSG";
BA_ "LongName" SG_ 748 DISP_OP_TAO_SUG_V_FRSG "Anzeige_Bedienung_Übernahme_Vorschlag_Geschwindigkeit_Vorausschau";
BA_ "SysSignalName" SG_ 748 DISP_OP_TAO_SUG_V_FRSG "DISP_OP_TAO_SUG_V_FRSG";
BA_ "CompuMethodName" SG_ 748 DISP_CASC "DISP_CASC";
BA_ "ISignalName" SG_ 748 DISP_CASC "DISP_CASC";
BA_ "LongName" SG_ 748 DISP_CASC "Anzeige_Kaskadierung";
BA_ "SysSignalName" SG_ 748 DISP_CASC "DISP_CASC";
BA_ "CompuMethodName" SG_ 748 UN_V_FRSG "UN_V_FRSG";
BA_ "ISignalName" SG_ 748 UN_V_FRSG "UN_V_FRSG";
BA_ "LongName" SG_ 748 UN_V_FRSG "Einheit_Geschwindigkeit_Vorausschau";
BA_ "SysSignalName" SG_ 748 UN_V_FRSG "UN_V_FRSG";
BA_ "CompuMethodName" SG_ 748 UN_DIST_FRSG "UN_DIST_FRSG";
BA_ "ISignalName" SG_ 748 UN_DIST_FRSG "UN_DIST_FRSG";
BA_ "LongName" SG_ 748 UN_DIST_FRSG "Einheit_Distanz_Vorausschau";
BA_ "SysSignalName" SG_ 748 UN_DIST_FRSG "UN_DIST_FRSG";
BA_ "CompuMethodName" SG_ 748 DISP_V_FRSG "DISP_V_FRSG_EDP";
BA_ "ISignalName" SG_ 748 DISP_V_FRSG "DISP_V_FRSG";
BA_ "LongName" SG_ 748 DISP_V_FRSG "Anzeige_Geschwindigkeit_Vorausschau";
BA_ "SysSignalName" SG_ 748 DISP_V_FRSG "DISP_V_FRSG";
BA_ "CompuMethodName" SG_ 748 DISP_V_FRSG_DIST "DISP_V_FRSG_DIST";
BA_ "ISignalName" SG_ 748 DISP_V_FRSG_DIST "DISP_V_FRSG_DIST";
BA_ "LongName" SG_ 748 DISP_V_FRSG_DIST "Anzeige_Geschwindigkeit_Vorausschau_Distanz";
BA_ "SysSignalName" SG_ 748 DISP_V_FRSG_DIST "DISP_V_FRSG_DIST";
BA_ "CompuMethodName" SG_ 748 DISP_V_FRSG_TYP "DISP_V_FRSG_TYP";
BA_ "ISignalName" SG_ 748 DISP_V_FRSG_TYP "DISP_V_FRSG_TYP";
BA_ "LongName" SG_ 748 DISP_V_FRSG_TYP "Anzeige_Geschwindigkeit_Vorausschau_Typ";
BA_ "SysSignalName" SG_ 748 DISP_V_FRSG_TYP "DISP_V_FRSG_TYP";
BA_ "CompuMethodName" SG_ 748 DISP_OP_TAO_SUG_V "DISP_OP_TAO_V_EDP";
BA_ "ISignalName" SG_ 748 DISP_OP_TAO_SUG_V "DISP_OP_TAO_SUG_V";
BA_ "LongName" SG_ 748 DISP_OP_TAO_SUG_V "Anzeige_Bedienung_Übernahme_Vorschlag_Geschwindigkeit";
BA_ "SysSignalName" SG_ 748 DISP_OP_TAO_SUG_V "DISP_OP_TAO_SUG_V";
BA_ "CompuMethodName" SG_ 748 DISP_TAO_SUG_V "DISP_TAO_SUG_V";
BA_ "ISignalName" SG_ 748 DISP_TAO_SUG_V "DISP_TAO_SUG_V";
BA_ "LongName" SG_ 748 DISP_TAO_SUG_V "Anzeige_Übernahme_Vorschlag_Geschwindigkeit";
BA_ "SysSignalName" SG_ 748 DISP_TAO_SUG_V "DISP_TAO_SUG_V";
BA_ "CompuMethodName" SG_ 748 ST_ISA "ST_ISA";
BA_ "ISignalName" SG_ 748 ST_ISA "ST_ISA";
BA_ "LongName" SG_ 748 ST_ISA "Status_ISA";
BA_ "SysSignalName" SG_ 748 ST_ISA "ST_ISA";
BA_ "CompuMethodName" SG_ 748 DISP_ACY_DCRN_ASST_2 "DISP_ACY_DCLN_ASST_2";
BA_ "ISignalName" SG_ 748 DISP_ACY_DCRN_ASST_2 "DISP_ACY_DCRN_ASST_2";
BA_ "LongName" SG_ 748 DISP_ACY_DCRN_ASST_2 "Anzeige_Aktivität_Verzögerung_Assistent_2";
BA_ "SysSignalName" SG_ 748 DISP_ACY_DCRN_ASST_2 "DISP_ACY_DCRN_ASST_2";
BA_ "CompuMethodName" SG_ 748 TAR_TYP_REAS_DCRN_2 "TAR_TYP_REAS_DCRN_2";
BA_ "ISignalName" SG_ 748 TAR_TYP_REAS_DCRN_2 "TAR_TYP_REAS_DCRN_2";
BA_ "LongName" SG_ 748 TAR_TYP_REAS_DCRN_2 "Soll_Typ_Grund_Verzögerung_2";
BA_ "SysSignalName" SG_ 748 TAR_TYP_REAS_DCRN_2 "TAR_TYP_REAS_DCRN_2";
BA_ "CompuMethodName" SG_ 748 CNCD_DISP_V_FRSG "CNCD_DISP_V_FRSG";
BA_ "ISignalName" SG_ 748 CNCD_DISP_V_FRSG "CNCD_DISP_V_FRSG";
BA_ "LongName" SG_ 748 CNCD_DISP_V_FRSG "Ländercodierung_Anzeige_Geschwindigkeit_Vorausschau";
BA_ "SysSignalName" SG_ 748 CNCD_DISP_V_FRSG "CNCD_DISP_V_FRSG";
BA_ "CompuMethodName" SG_ 748 DISP_OP_TAO_SUG_V_2 "DISP_OP_TAO_SUG_V_2";
BA_ "ISignalName" SG_ 748 DISP_OP_TAO_SUG_V_2 "DISP_OP_TAO_SUG_V_2";
BA_ "LongName" SG_ 748 DISP_OP_TAO_SUG_V_2 "Anzeige_Bedienung_Übernahme_Vorschlag_Geschwindigkeit_2";
BA_ "SysSignalName" SG_ 748 DISP_OP_TAO_SUG_V_2 "DISP_OP_TAO_SUG_V_2";
BA_ "CompuMethodName" SG_ 755 DISP_V_SUG "DISP_V_SUG";
BA_ "GenSigStartValue" SG_ 755 DISP_V_SUG 1;
BA_ "ISignalName" SG_ 755 DISP_V_SUG "DISP_V_SUG";
BA_ "LongName" SG_ 755 DISP_V_SUG "Anzeige_Geschwindigkeit_Vorschlag";
BA_ "SysSignalName" SG_ 755 DISP_V_SUG "DISP_V_SUG";
BA_ "CompuMethodName" SG_ 755 DISP_OFFS_BOT_SAIL "DISP_OFFS_SAIL";
BA_ "ISignalName" SG_ 755 DISP_OFFS_BOT_SAIL "DISP_OFFS_BOT_SAIL";
BA_ "LongName" SG_ 755 DISP_OFFS_BOT_SAIL "Anzeige_Offset_Unten_Segeln";
BA_ "SysSignalName" SG_ 755 DISP_OFFS_BOT_SAIL "DISP_OFFS_BOT_SAIL";
BA_ "CompuMethodName" SG_ 755 DISP_OFFS_TOP_SAIL "DISP_OFFS_SAIL";
BA_ "ISignalName" SG_ 755 DISP_OFFS_TOP_SAIL "DISP_OFFS_TOP_SAIL";
BA_ "LongName" SG_ 755 DISP_OFFS_TOP_SAIL "Anzeige_Offset_Oben_Segeln";
BA_ "SysSignalName" SG_ 755 DISP_OFFS_TOP_SAIL "DISP_OFFS_TOP_SAIL";
BA_ "CompuMethodName" SG_ 755 TAR_TYP_REAS_DCRN_3 "TAR_TYP_REAS_DCRN_3";
BA_ "ISignalName" SG_ 755 TAR_TYP_REAS_DCRN_3 "TAR_TYP_REAS_DCRN_3";
BA_ "LongName" SG_ 755 TAR_TYP_REAS_DCRN_3 "Soll_Typ_Grund_Verzögerung_3";
BA_ "SysSignalName" SG_ 755 TAR_TYP_REAS_DCRN_3 "TAR_TYP_REAS_DCRN_3";
BA_ "CompuMethodName" SG_ 686 DEGR_DRV_PWR "PCN_0_100_8Bit_Q1";
BA_ "ISignalName" SG_ 686 DEGR_DRV_PWR "DEGR_DRV_PWR";
BA_ "LongName" SG_ 686 DEGR_DRV_PWR "Degradierte_Antrieb_Leistung";
BA_ "SysSignalName" SG_ 686 DEGR_DRV_PWR "DEGR_DRV_PWR";
BA_ "CompuMethodName" SG_ 686 MAX_BNDRY_DRVG_EL "PCN_0_100_8Bit_Q1";
BA_ "ISignalName" SG_ 686 MAX_BNDRY_DRVG_EL "MAX_BNDRY_DRVG_EL";
BA_ "LongName" SG_ 686 MAX_BNDRY_DRVG_EL "Maximal_Grenze_Fahren_Elektrisch";
BA_ "SysSignalName" SG_ 686 MAX_BNDRY_DRVG_EL "MAX_BNDRY_DRVG_EL";
BA_ "CompuMethodName" SG_ 686 DISP_PWR_DRV_2 "DISP_PWR_DRV_2";
BA_ "GenSigStartValue" SG_ 686 DISP_PWR_DRV_2 -100;
BA_ "ISignalName" SG_ 686 DISP_PWR_DRV_2 "DISP_PWR_DRV_2";
BA_ "LongName" SG_ 686 DISP_PWR_DRV_2 "Anzeige_Leistung_Antrieb_2";
BA_ "SysSignalName" SG_ 686 DISP_PWR_DRV_2 "DISP_PWR_DRV_2";
BA_ "CompuMethodName" SG_ 686 DEGR_RECUP_PWR "PCN_100_0_4Bit_Q10";
BA_ "GenSigStartValue" SG_ 686 DEGR_RECUP_PWR -100;
BA_ "ISignalName" SG_ 686 DEGR_RECUP_PWR "DEGR_RECUP_PWR";
BA_ "LongName" SG_ 686 DEGR_RECUP_PWR "Degradierte_Rekuperation_Leistung";
BA_ "SysSignalName" SG_ 686 DEGR_RECUP_PWR "DEGR_RECUP_PWR";
BA_ "CompuMethodName" SG_ 686 QTA_IMME_EENG_DRV_RECUP "QTA_IMME_EENG_DRV_RECUP";
BA_ "GenSigStartValue" SG_ 686 QTA_IMME_EENG_DRV_RECUP 100;
BA_ "ISignalName" SG_ 686 QTA_IMME_EENG_DRV_RECUP "QTA_IMME_EENG_DRV_RECUP";
BA_ "LongName" SG_ 686 QTA_IMME_EENG_DRV_RECUP "Anteil_Aktuell_Elektromotor_Antrieb_Rekuperation";
BA_ "SysSignalName" SG_ 686 QTA_IMME_EENG_DRV_RECUP "QTA_IMME_EENG_DRV_RECUP";
BA_ "CompuMethodName" SG_ 686 DISP_DSTN_SOC "REPAT_IMME_CENG_EENG";
BA_ "ISignalName" SG_ 686 DISP_DSTN_SOC "DISP_DSTN_SOC";
BA_ "LongName" SG_ 686 DISP_DSTN_SOC "Anzeige_Ziel_SOC";
BA_ "SysSignalName" SG_ 686 DISP_DSTN_SOC "DISP_DSTN_SOC";
BA_ "CompuMethodName" SG_ 934 DISP_REPAT_DRV_EL_PWR "DISP_REPAT_DRV_EL_PWR";
BA_ "ISignalName" SG_ 934 DISP_REPAT_DRV_EL_PWR "DISP_REPAT_DRV_EL_PWR";
BA_ "LongName" SG_ 934 DISP_REPAT_DRV_EL_PWR "Anzeige_Verteilung_Antrieb_Elektrisch_Leistung";
BA_ "SysSignalName" SG_ 934 DISP_REPAT_DRV_EL_PWR "DISP_REPAT_DRV_EL_PWR";
BA_ "CompuMethodName" SG_ 934 DISP_REPAT_AIC_EL_PWR "Prozent_100_8Bit";
BA_ "ISignalName" SG_ 934 DISP_REPAT_AIC_EL_PWR "DISP_REPAT_AIC_EL_PWR";
BA_ "LongName" SG_ 934 DISP_REPAT_AIC_EL_PWR "Anzeige_Verteilung_Klima_Elektrisch_Leistung";
BA_ "SysSignalName" SG_ 934 DISP_REPAT_AIC_EL_PWR "DISP_REPAT_AIC_EL_PWR";
BA_ "CompuMethodName" SG_ 934 DISP_REPAT_EL_RNG_AIC_BST "DISP_REPAT_EL_RNG_AIC_BST";
BA_ "ISignalName" SG_ 934 DISP_REPAT_EL_RNG_AIC_BST "DISP_REPAT_EL_RNG_AIC_BST";
BA_ "LongName" SG_ 934 DISP_REPAT_EL_RNG_AIC_BST "Anzeige_Verteilung_Elektrisch_Reichweite_Klima_Erhöhung";
BA_ "SysSignalName" SG_ 934 DISP_REPAT_EL_RNG_AIC_BST "DISP_REPAT_EL_RNG_AIC_BST";
BA_ "CompuMethodName" SG_ 934 DISP_REPAT_EL_SHTR "DISP_REPAT_EL_SHTR";
BA_ "ISignalName" SG_ 934 DISP_REPAT_EL_SHTR "DISP_REPAT_EL_SHTR";
BA_ "LongName" SG_ 934 DISP_REPAT_EL_SHTR "Anzeige_Verteilung_Elektrisch_Sitzheizung";
BA_ "SysSignalName" SG_ 934 DISP_REPAT_EL_SHTR "DISP_REPAT_EL_SHTR";
BA_ "CompuMethodName" SG_ 934 DISP_REPAT_EL_RNG_SHTR_BST_2 "DISP_REPAT_EL_RNG_SHTR_BST_2";
BA_ "ISignalName" SG_ 934 DISP_REPAT_EL_RNG_SHTR_BST_2 "DISP_REPAT_EL_RNG_SHTR_BST_2";
BA_ "LongName" SG_ 934 DISP_REPAT_EL_RNG_SHTR_BST_2 "DISP_REPAT_EL_RNG_SHTR_BST_2";
BA_ "SysSignalName" SG_ 934 DISP_REPAT_EL_RNG_SHTR_BST_2 "DISP_REPAT_EL_RNG_SHTR_BST_2";
BA_ "CompuMethodName" SG_ 243 CRC_DISP_RPM_PT "CRC8";
BA_ "ISignalName" SG_ 243 CRC_DISP_RPM_PT "CRC_DISP_RPM_PT";
BA_ "LongName" SG_ 243 CRC_DISP_RPM_PT "CRC_Anzeige_Drehzahl_Antriebsstrang";
BA_ "SysSignalName" SG_ 243 CRC_DISP_RPM_PT "CRC_DISP_RPM_PT";
BA_ "CompuMethodName" SG_ 243 ALIV_DISP_RPM_ENG_CRSH "Aliv_4";
BA_ "ISignalName" SG_ 243 ALIV_DISP_RPM_ENG_CRSH "ALIV_DISP_RPM_ENG_CRSH";
BA_ "LongName" SG_ 243 ALIV_DISP_RPM_ENG_CRSH "Alive_Anzeige_Drehzahl_Motor_Kurbelwelle";
BA_ "SysSignalName" SG_ 243 ALIV_DISP_RPM_ENG_CRSH "ALIV_DISP_RPM_ENG_CRSH";
BA_ "CompuMethodName" SG_ 243 DISP_RPM_ENG_CRSH "DISP_RPM_ENG_CRSH";
BA_ "ISignalName" SG_ 243 DISP_RPM_ENG_CRSH "DISP_RPM_ENG_CRSH";
BA_ "LongName" SG_ 243 DISP_RPM_ENG_CRSH "Anzeige_Drehzahl_Motor_Kurbelwelle";
BA_ "SysSignalName" SG_ 243 DISP_RPM_ENG_CRSH "DISP_RPM_ENG_CRSH";
BA_ "CompuMethodName" SG_ 243 DISP_TARG_DRV "DISP_TARG_DRV";
BA_ "ISignalName" SG_ 243 DISP_TARG_DRV "DISP_TARG_DRV";
BA_ "LongName" SG_ 243 DISP_TARG_DRV "Anzeige_Zielgang_Antrieb";
BA_ "SysSignalName" SG_ 243 DISP_TARG_DRV "DISP_TARG_DRV";
BA_ "CompuMethodName" SG_ 243 DISP_GSI_DRV "DISP_GSI_DRV";
BA_ "ISignalName" SG_ 243 DISP_GSI_DRV "DISP_GSI_DRV";
BA_ "LongName" SG_ 243 DISP_GSI_DRV "Anzeige_Schalthinweis_Antrieb";
BA_ "SysSignalName" SG_ 243 DISP_GSI_DRV "DISP_GSI_DRV";
BA_ "CompuMethodName" SG_ 243 ReqDispAvailabilityDrivePower "ReqDispAvailabilityDrivePower";
BA_ "ISignalName" SG_ 243 ReqDispAvailabilityDrivePower "ReqDispAvailabilityDrivePower";
BA_ "LongName" SG_ 243 ReqDispAvailabilityDrivePower "ReqDispAvailabilityDrivePower";
BA_ "SysSignalName" SG_ 243 ReqDispAvailabilityDrivePower "ReqDispAvailabilityDrivePower";
BA_ "CompuMethodName" SG_ 243 DISP_AVL_PWR_REL_RECUP_IGR "DISP_AVL_PWR_REL_RECUP_IGR";
BA_ "ISignalName" SG_ 243 DISP_AVL_PWR_REL_RECUP_IGR "DISP_AVL_PWR_REL_RECUP_IGR";
BA_ "LongName" SG_ 243 DISP_AVL_PWR_REL_RECUP_IGR "Anzeige_Ist_Leistung_Relativ_Rekuperation_IGR";
BA_ "SysSignalName" SG_ 243 DISP_AVL_PWR_REL_RECUP_IGR "DISP_AVL_PWR_REL_RECUP_IGR";
BA_ "ISignalName" SG_ 243 DISP_RPM_PT_dummy_36_39 "DISP_RPM_PT_dummy_36_39";
BA_ "LongName" SG_ 243 DISP_RPM_PT_dummy_36_39 "DISP_RPM_PT_dummy_36_39";
BA_ "SysSignalName" SG_ 243 DISP_RPM_PT_dummy_36_39 "DISP_RPM_PT_dummy_36_39";
BA_ "CompuMethodName" SG_ 243 DISP_GR_PT "DISP_GR_PT";
BA_ "ISignalName" SG_ 243 DISP_GR_PT "DISP_GR_PT";
BA_ "LongName" SG_ 243 DISP_GR_PT "Anzeige_Gang_Antriebsstrang";
BA_ "SysSignalName" SG_ 243 DISP_GR_PT "DISP_GR_PT";
BA_ "ISignalName" SG_ 243 DISP_RPM_PT_dummy_46_47 "DISP_RPM_PT_dummy_46_47";
BA_ "LongName" SG_ 243 DISP_RPM_PT_dummy_46_47 "DISP_RPM_PT_dummy_46_47";
BA_ "SysSignalName" SG_ 243 DISP_RPM_PT_dummy_46_47 "DISP_RPM_PT_dummy_46_47";
BA_ "CompuMethodName" SG_ 243 CTR_DISP_PWSPAR "CTR_DISP_PWSPAR";
BA_ "ISignalName" SG_ 243 CTR_DISP_PWSPAR "CTR_DISP_PWSPAR";
BA_ "LongName" SG_ 243 CTR_DISP_PWSPAR "Steuerung_Anzeige_Power-Reserve";
BA_ "SysSignalName" SG_ 243 CTR_DISP_PWSPAR "CTR_DISP_PWSPAR";
BA_ "CompuMethodName" SG_ 243 DisplayMsaStatus "DisplayMsaStatus";
BA_ "ISignalName" SG_ 243 DisplayMsaStatus "DisplayMsaStatus";
BA_ "LongName" SG_ 243 DisplayMsaStatus "DisplayMsaStatus";
BA_ "SysSignalName" SG_ 243 DisplayMsaStatus "DisplayMsaStatus";
BA_ "ISignalName" SG_ 243 DISP_RPM_PT_dummy_63_63 "DISP_RPM_PT_dummy_63_63";
BA_ "LongName" SG_ 243 DISP_RPM_PT_dummy_63_63 "DISP_RPM_PT_dummy_63_63";
BA_ "SysSignalName" SG_ 243 DISP_RPM_PT_dummy_63_63 "DISP_RPM_PT_dummy_63_63";
BA_ "CompuMethodName" SG_ 595 DISP_S_ENG_TORQ "DISP_S_ENG";
BA_ "ISignalName" SG_ 595 DISP_S_ENG_TORQ "DISP_S_ENG_TORQ";
BA_ "LongName" SG_ 595 DISP_S_ENG_TORQ "Anzeige_Sport_Motor_Drehmoment";
BA_ "SysSignalName" SG_ 595 DISP_S_ENG_TORQ "DISP_S_ENG_TORQ";
BA_ "CompuMethodName" SG_ 595 DISP_S_ENG_TORQ_BS_SCAL_VL "DISP_S_ENG_TORQ_BS_SCAL_VL";
BA_ "ISignalName" SG_ 595 DISP_S_ENG_TORQ_BS_SCAL_VL "DISP_S_ENG_TORQ_BS_SCAL_VL";
BA_ "LongName" SG_ 595 DISP_S_ENG_TORQ_BS_SCAL_VL "Anzeige_Sport_Motor_Drehmoment_Basis_Skalierung_Wert";
BA_ "SysSignalName" SG_ 595 DISP_S_ENG_TORQ_BS_SCAL_VL "DISP_S_ENG_TORQ_BS_SCAL_VL";
BA_ "CompuMethodName" SG_ 595 DISP_S_ENG_PWR_BS_SCAL_VL "DISP_S_ENG_PWR_BS_SCAL_VL";
BA_ "ISignalName" SG_ 595 DISP_S_ENG_PWR_BS_SCAL_VL "DISP_S_ENG_PWR_BS_SCAL_VL";
BA_ "LongName" SG_ 595 DISP_S_ENG_PWR_BS_SCAL_VL "Anzeige_Sport_Motor_Leistung_Basis_Skalierung_Wert";
BA_ "SysSignalName" SG_ 595 DISP_S_ENG_PWR_BS_SCAL_VL "DISP_S_ENG_PWR_BS_SCAL_VL";
BA_ "CompuMethodName" SG_ 595 DISP_S_ENG_PWR "DISP_S_ENG";
BA_ "ISignalName" SG_ 595 DISP_S_ENG_PWR "DISP_S_ENG_PWR";
BA_ "LongName" SG_ 595 DISP_S_ENG_PWR "Anzeige_Sport_Motor_Leistung";
BA_ "SysSignalName" SG_ 595 DISP_S_ENG_PWR "DISP_S_ENG_PWR";
BA_ "CompuMethodName" SG_ 595 DISP_MAXV_PWR "DISP_MAXV_S";
BA_ "ISignalName" SG_ 595 DISP_MAXV_PWR "DISP_MAXV_PWR";
BA_ "LongName" SG_ 595 DISP_MAXV_PWR "Anzeige_Maximalwert_Leistung";
BA_ "SysSignalName" SG_ 595 DISP_MAXV_PWR "DISP_MAXV_PWR";
BA_ "CompuMethodName" SG_ 595 DISP_MAXV_TORQ "DISP_MAXV_S";
BA_ "ISignalName" SG_ 595 DISP_MAXV_TORQ "DISP_MAXV_TORQ";
BA_ "LongName" SG_ 595 DISP_MAXV_TORQ "Anzeige_Maximalwert_Drehmoment";
BA_ "SysSignalName" SG_ 595 DISP_MAXV_TORQ "DISP_MAXV_TORQ";
BA_ "CompuMethodName" SG_ 595 ReductionAirConPowerCompProt "ReductionAirConPowerCompProt";
BA_ "ISignalName" SG_ 595 ReductionAirConPowerCompProt "ReductionAirConPowerCompProt";
BA_ "LongName" SG_ 595 ReductionAirConPowerCompProt "ReductionAirConPowerCompProt";
BA_ "SysSignalName" SG_ 595 ReductionAirConPowerCompProt "ReductionAirConPowerCompProt";
VAL_ 672 CTR_CLSY_DRD 0 "Kindersicherung deaktivieren" 1 "Entriegeln" 2 "Verriegeln" 3 "Sichern" 4 "Kindersicherung aktivieren" 8 "Keine Änderung" 9 "Logisch entriegeln" 15 "Signal ungültig";
VAL_ 1069 ListEntryAdditionalDisplayHUD 0 "Keine_Anzeige" 1 "Listeneintrag \"aus anzeigen\"" 2 "Listeneintrag \"Automatisch anzeigen\"" 4 "Listeneintrag \"permanent anzeigen\"" 8 "Listeneintrag \"permanent anzeigen\"" 16 "Listeneintrag \"permanent anzeigen\"" 255 "Sendefunktion nicht in Betrieb";
VAL_ 622 OperationChargeControlPlugRemote 0 "Darf nur in Bedienrichtung verwendet werden" 1 "Ladestecker_entriegeln_1" 2 "Ladestecker_entriegeln_2" 3 "Sendefunktion nicht in Betrieb";
VAL_ 439 ControlDriftAssistLampFrequency 13 "SIGNALTAG_FCTIF_NOT_AVAILABLE" 14 "SIGNALTAG_FCT_ERROR" 15 "Sendefunktion nicht in Betrieb";
VAL_ 439 ControlDriftAssist 0 "M_Drift_Assist_in_Kombi_nicht_anzeigen" 1 "M_Drift_Assist_in_Kombi_neutral_anzeigen" 2 "M_Drift_Assist_in_Kombi_als_Regelung_anzeigen" 3 "Sendefunktion nicht in Betrieb";
VAL_ 866 ST_UN_V_BC 0 "Default" 1 "km/h, km" 2 "mph, mls" 3 "Signal ungültig";
VAL_ 866 ST_UN_COSP_BC 0 "Default" 1 "Verbrauch in l/100km" 2 "Verbrauch in mpg UK" 3 "Verbrauch in mpg US" 4 "Verbrauch in km/l" 7 "Signal ungültig";
VAL_ 1022 SU_PREV 1 "Gang_Kupplung mit Symbol darstellen" 2 "Fahrpedal mit Symbol darstellen" 4 "Fahrzeugstillstand mit Symbol darstellen" 8 "Fahrbereitschaft mit Symbol darstellen" 16 "Button Messung starten vorhanden" 32 "Neigung mit Symbol darstellen" 128 "Temperatur mit Symbol darstellen" 253 "Hinweis: Reserviert für funktionale Kennung Signal-Tag." 254 "Hinweis: Reserviert für funktionale Kennung Signal-Tag." 255 "Sendefunktion nicht in Betrieb";
VAL_ 1022 SU_ST 1 "Sensorniveau anzeigen" 2 "aktuelle Füllmenge anzeigen" 4 "Zielfüllmenge anzeigen" 8 "Nachfüllmenge anzeigen" 16 "Füllstandsbalken anzeigen" 64 "Aktualität anzeigen" 253 "Hinweis: Reserviert für funktionale Kennung Signal-Tag." 254 "Hinweis: Reserviert für funktionale Kennung Signal-Tag." 255 "Sendefunktion nicht in Betrieb";
VAL_ 1022 SU_MEASMT 1 "Sensorniveau anzeigen" 8 "Drehzahl anzeigen" 16 "Druck anzeigen" 32 "Neigung anzeigen" 64 "Temperatur anzeigen" 253 "Hinweis: Reserviert für funktionale Kennung Signal-Tag." 254 "Hinweis: Reserviert für funktionale Kennung Signal-Tag." 255 "Sendefunktion nicht in Betrieb";
VAL_ 1022 SU_RSLT 1 "Sensorniveau anzeigen" 2 "aktuelle Füllmenge anzeigen" 4 "Zielfüllmenge anzeigen" 8 "Nachfüllmenge anzeigen" 16 "Füllstandsbalken anzeigen" 64 "Aktualität anzeigen" 253 "Hinweis: Reserviert für funktionale Kennung Signal-Tag." 254 "Hinweis: Reserviert für funktionale Kennung Signal-Tag." 255 "Sendefunktion nicht in Betrieb";
VAL_ 1022 SU_FRC 0 "Textbaustein Teil 2 Variante 0" 1 "Textbaustein Teil 1 Variante 1" 2 "Textbaustein Teil 1 Variante 2" 4 "Textbaustein Teil 1 Variante 3" 8 "Textbaustein Teil 1 Variante 4" 16 "Textbaustein Teil 2 Variante 1" 32 "Textbaustein Teil 2 Variante 2" 64 "Textbaustein Teil 2 Variante 3" 128 "Textbaustein Teil 2 Variante 4" 253 "Hinweis: Reserviert für funktionale Kennung Signal-Tag." 254 "Hinweis: Reserviert für funktionale Kennung Signal-Tag." 255 "Sendefunktion nicht in Betrieb";
VAL_ 1023 SU_LEV_MAXV 253 "Hinweis: Reserviert für funktionale Kennung Signal-Tag." 254 "Hinweis: Reserviert für funktionale Kennung Signal-Tag." 255 "Sendefunktion nicht in Betrieb";
VAL_ 1023 SU_LEV_MINV 253 "Hinweis: Reserviert für funktionale Kennung Signal-Tag." 254 "Hinweis: Reserviert für funktionale Kennung Signal-Tag." 255 "Sendefunktion nicht in Betrieb";
VAL_ 1023 SU_LEV_AV_CUMO_MAXV 253 "Hinweis: Reserviert für funktionale Kennung Signal-Tag." 254 "Hinweis: Reserviert für funktionale Kennung Signal-Tag." 255 "Sendefunktion nicht in Betrieb";
VAL_ 1023 SU_LEV_AV_CUMO_MINV 253 "Hinweis: Reserviert für funktionale Kennung Signal-Tag." 254 "Hinweis: Reserviert für funktionale Kennung Signal-Tag." 255 "Sendefunktion nicht in Betrieb";
VAL_ 1023 SU_DISP_DUR_TMOUT 253 "Hinweis: Reserviert für funktionale Kennung Signal-Tag." 254 "Hinweis: Reserviert für funktionale Kennung Signal-Tag." 255 "Sendefunktion nicht in Betrieb";
VAL_ 1023 SU_DISP_DUR_MEASMT 253 "Hinweis: Reserviert für funktionale Kennung Signal-Tag." 254 "Hinweis: Reserviert für funktionale Kennung Signal-Tag." 255 "Sendefunktion nicht in Betrieb";
VAL_ 1023 SU_DISP_DUR_ABRT 253 "Hinweis: Reserviert für funktionale Kennung Signal-Tag." 254 "Hinweis: Reserviert für funktionale Kennung Signal-Tag." 255 "Sendefunktion nicht in Betrieb";
VAL_ 1023 SU_DISP_DUR_RSLT 253 "Hinweis: Reserviert für funktionale Kennung Signal-Tag." 254 "Hinweis: Reserviert für funktionale Kennung Signal-Tag." 255 "Sendefunktion nicht in Betrieb";
VAL_ 1024 VL_CENG_OIL_DISP 71 "Text - Warmlauf" 72 "Text - Detailmessung" 73 "Text - Nachlauf" 81 "Text - Vorbereitung Standardmodus" 82 "Text - Sensorfehler" 83 "Text - keine_Applikationsdaten" 91 "Text - Vorbereitung Servicemodus" 92 "Text - Sensorfehler - Service" 93 "Text - keine_Applikationsdaten - Service" 101 "Text - Vorbereitung alternativer Kundenmodus (AKMod)" 102 "Text - Sensorfehler - AKMod" 103 "Text - keine_Applikationsdaten - AKMod" 111 "Text - Status OK" 112 "Text - Status am MIN" 113 "Text - Status unter MIN" 114 "Text - Status über MAX" 115 "Text - Status undefiniert" 121 "Text - Status OK - Service" 122 "Text - Status am MIN - Service" 123 "Text - Status unter MIN - Service" 124 "Text - Status über MAX - Service" 125 "Text - Status undefiniert - Service" 131 "Text - Status OK - AKMod" 132 "Text - Status am MIN - AKMod" 133 "Text - Status unter MIN - AKMod" 134 "Text - Status über MAX - AKMod" 135 "Text - Status undefiniert - AKMod" 141 "Text - Ergebnis OK" 142 "Text - Ergebnis am MIN" 143 "Text - Ergebnis unter MIN" 144 "Text - Ergebnis über MAX" 151 "Text - Ergebnis OK - Service" 152 "Text - Ergebnis am MIN - Service" 153 "Text - Ergebnis unter MIN - Service" 154 "Text - Ergebnis über MAX - Service" 161 "Text - Ergebnis OK - AKMod" 162 "Text - Ergebnis am MIN - AKMod" 163 "Text - Ergebnis unter MIN - AKMod" 164 "Text - Ergebnis über MAX - AKMod" 170 "Text - Abbruch Moduswechsel" 171 "Text - Abbruch Gangwahl" 172 "Text - Abbruch Fahrpedal getreten" 173 "Text - Abbruch Geschwindigkeit" 174 "Text - Abbruch Keine Rückmeldung auf Anfrage" 175 "Text - Abbruch Öldruck" 176 "Text - Abbruch Neigung" 177 "Text - Abbruch Drehzahl" 178 "Text - Abbruch Temperatur" 179 "Text - Abbruch Öllevel" 180 "Text - Abbruch Moduswechsel - Service" 181 "Text - Abbruch Gangwahl - Service" 182 "Text - Abbruch Fahrpedal getreten - Service" 183 "Text - Abbruch Geschwindigkeit - Service" 184 "Text - Abbruch Keine Rückmeldung auf Anfrage - Service" 185 "Text - Abbruch Öldruck - Service" 186 "Text - Abbruch Neigung - Service" 187 "Text - Abbruch Drehzahl - Service" 188 "Text - Abbruch Temperatur - Service" 189 "Text - Abbruch Öllevel - Service" 190 "Text - Abbruch Moduswechsel - AKMod" 191 "Text - Abbruch Gangwahl - AKMod" 192 "Text - Abbruch Fahrpedal getreten - AKMod" 193 "Text - Abbruch Geschwindigkeit - AKMod" 194 "Text - Abbruch Keine Rückmeldung auf Anfrage - AKMod" 195 "Text - Abbruch Öldruck - AKMod" 196 "Text - Abbruch Neigung - AKMod" 197 "Text - Abbruch Drehzahl - AKMod" 198 "Text - Abbruch Temperatur - AKMod" 199 "Text - Abbruch Öllevel - AKMod" 253 "Hinweis: Reserviert für funktionale Kennung Signal-Tag." 254 "Hinweis: Reserviert für funktionale Kennung Signal-Tag." 255 "Sendefunktion nicht in Betrieb";
VAL_ 1024 VL_CENG_OILV 253 "Hinweis: Reserviert für funktionale Kennung Signal-Tag." 254 "Hinweis: Reserviert für funktionale Kennung Signal-Tag." 255 "Sendefunktion nicht in Betrieb";
VAL_ 1024 VL_ADDON_INFO 253 "Hinweis: Reserviert für funktionale Kennung Signal-Tag." 254 "Hinweis: Reserviert für funktionale Kennung Signal-Tag." 255 "Sendefunktion nicht in Betrieb";
VAL_ 1024 VL_MESS 1 "Benachrichtigung Messung möglich" 253 "Hinweis: Reserviert für funktionale Kennung Signal-Tag." 254 "Hinweis: Reserviert für funktionale Kennung Signal-Tag." 255 "Sendefunktion nicht in Betrieb";
VAL_ 1024 VL_CURR 253 "Hinweis: Reserviert für funktionale Kennung Signal-Tag." 254 "Hinweis: Reserviert für funktionale Kennung Signal-Tag." 255 "Sendefunktion nicht in Betrieb";
VAL_ 1024 VL_PREV 1 "Gang_Kupplung niO" 2 "Fahrpedal niO" 4 "Fahrzeugstillstand niO" 8 "Fahrbereitschaft niO" 16 "Button Messung starten freigegeben" 32 "Neigung niO" 128 "Temperatur niO" 253 "Hinweis: Reserviert für funktionale Kennung Signal-Tag." 254 "Hinweis: Reserviert für funktionale Kennung Signal-Tag." 255 "Sendefunktion nicht in Betrieb";
VAL_ 1024 VL_FRC 253 "Hinweis: Reserviert für funktionale Kennung Signal-Tag." 254 "Hinweis: Reserviert für funktionale Kennung Signal-Tag." 255 "Sendefunktion nicht in Betrieb";
VAL_ 1025 VL_RFLV 253 "Hinweis: Reserviert für funktionale Kennung Signal-Tag." 254 "Hinweis: Reserviert für funktionale Kennung Signal-Tag." 255 "Sendefunktion nicht in Betrieb";
VAL_ 1025 VL_DSTN_AMO 253 "Hinweis: Reserviert für funktionale Kennung Signal-Tag." 254 "Hinweis: Reserviert für funktionale Kennung Signal-Tag." 255 "Sendefunktion nicht in Betrieb";
VAL_ 1025 VL_PRES_FIAM 253 "Hinweis: Reserviert für funktionale Kennung Signal-Tag." 254 "Hinweis: Reserviert für funktionale Kennung Signal-Tag." 255 "Sendefunktion nicht in Betrieb";
VAL_ 1025 VL_SUTE 253 "Hinweis: Reserviert für funktionale Kennung Signal-Tag." 254 "Hinweis: Reserviert für funktionale Kennung Signal-Tag." 255 "Sendefunktion nicht in Betrieb";
VAL_ 1025 ST_RFLV 0 "Wert Nachfüllmenge ist verfügbar" 1 "Wert Nachfüllmenge wird bei Bedarf umgerechnet" 4 "Textbaustein Variante 1" 5 "Textbaustein Variante 2" 6 "Textbaustein Variante 3" 7 "Textbaustein Variante 4" 13 "Hinweis: Reserviert für funktionale Kennung Signal-Tag." 14 "Hinweis: Reserviert für funktionale Kennung Signal-Tag." 15 "Zustand kein Ergebnis";
VAL_ 1025 ST_TAAM 0 "Wert Ziel-Menge ist verfügbar" 1 "Wert Ziel-Menge wird bei Bedarf umgerechnet" 4 "Textbaustein Variante 1" 5 "Textbaustein Variante 2" 6 "Textbaustein Variante 3" 7 "Textbaustein Variante 4" 13 "Hinweis: Reserviert für funktionale Kennung Signal-Tag." 14 "Hinweis: Reserviert für funktionale Kennung Signal-Tag." 15 "Zustand kein Ergebnis";
VAL_ 1025 ST_PRES_FIAM 0 "Wert aktuelle Füllmenge ist verfügbar" 1 "Wert aktuelle Füllmenge wird bei Bedarf umgerechnet" 4 "Textbaustein Variante 1" 5 "Textbaustein Variante 2" 6 "Textbaustein Variante 3" 7 "Textbaustein Variante 4" 13 "Hinweis: Reserviert für funktionale Kennung Signal-Tag." 14 "Hinweis: Reserviert für funktionale Kennung Signal-Tag." 15 "Zustand kein Ergebnis";
VAL_ 1025 ST_SUTE 0 "Wert Sumpftemperatur ist verfügbar" 1 "Wert Sumpftemperatur wird bei Bedarf umgerechnet" 4 "Textbaustein Variante 1" 5 "Textbaustein Variante 2" 6 "Textbaustein Variante 3" 7 "Textbaustein Variante 4" 13 "Hinweis: Reserviert für funktionale Kennung Signal-Tag." 14 "Hinweis: Reserviert für funktionale Kennung Signal-Tag." 15 "Zustand kein Ergebnis";
VAL_ 1025 VL_SEN_LEV 253 "Hinweis: Reserviert für funktionale Kennung Signal-Tag." 254 "Hinweis: Reserviert für funktionale Kennung Signal-Tag." 255 "Sendefunktion nicht in Betrieb";
VAL_ 919 ST_OBD_CYC 0 "Bedingungen/Kriterien für einen OBD RBM/IUMPR Cycle nicht erfüllt" 1 "Bedingungen/Kriterien für einen OBD Warm-Up Cycle erfüllt" 2 "Bedingungen/Kriterien für einen qualifizierten OBD Driving Cycle erfüllt" 4 "Bedingungen/Kriterien für einen OBD RBM/IUMPR Cycle erfüllt" 16 "Bedingungen/Kriterien für den Zyklus zum Heilen der Permanent DTC`s ist erfüllt" 32 "Bedingungen/Kriterien für einen OBD RBM/IUMPR Cycle nicht erfüllbar (wegen Fehler)" 63 "Signal ungültig";
VAL_ 1000 RQ_MIL_DIAG_OBD_ENGMG_EL 1 "Anforderung MIL AUS" 2 "Anforderung MIL EIN" 3 "Signal ungültig";
VAL_ 1000 RQ_RST_OBD_DIAG 0 "Keine Anforderung Reset OBD_Diagnose" 2 "Anforderung Reset OBD_Diagnose" 3 "Signal ungültig";
VAL_ 514 CTR_ILUM_SW 254 "Lichtschalter AUS";
VAL_ 659 ST_CC_ARS 0 "Betreffende CC-message wird gelöscht" 1 "CC-message display" 3 "Signal ungültig";
VAL_ 659 ST_IDC_CC_ARS 0 "Kein Blinken" 1 "Langsamer Takt = 1 Hz" 2 "Schneller Takt = 3 Hz" 3 "Signal ungültig";
VAL_ 878 ST_CC_BYPA_00 0 "Betreffende CC-message wird gelöscht" 1 "CC-message display" 3 "Signal ungültig";
VAL_ 878 TRANF_CC_BYPA_00 15 "Signal ungültig";
VAL_ 878 ST_IDC_CC_BYPA_00 0 "Kein Blinken" 1 "Langsamer Takt = 1 Hz" 2 "Schneller Takt = 3 Hz" 3 "Signal ungültig";
VAL_ 879 ST_CC_BYPA_01 0 "Betreffende CC-message wird gelöscht" 1 "CC-message display" 3 "Signal ungültig";
VAL_ 879 TRANF_CC_BYPA_01 15 "Signal ungültig";
VAL_ 879 ST_IDC_CC_BYPA_01 0 "Kein Blinken" 1 "Langsamer Takt = 1 Hz" 2 "Schneller Takt = 3 Hz" 3 "Signal ungültig";
VAL_ 809 ST_CC_BYPA_02 0 "Betreffende CC-message wird gelöscht" 1 "CC-message display" 3 "Signal ungültig";
VAL_ 809 ST_IDC_CC_BYPA_02 0 "Kein Blinken" 1 "Langsamer Takt = 1 Hz" 2 "Schneller Takt = 3 Hz" 3 "Signal ungültig";
VAL_ 827 ST_CC_BYPA_02 0 "Betreffende CC-message wird gelöscht" 1 "CC-message display" 3 "Signal ungültig";
VAL_ 827 ST_IDC_CC_BYPA_02 0 "Kein Blinken" 1 "Langsamer Takt = 1 Hz" 2 "Schneller Takt = 3 Hz" 3 "Signal ungültig";
VAL_ 936 ST_CC_BYPA_03 0 "Betreffende CC-message wird gelöscht" 1 "CC-message display" 3 "Signal ungültig";
VAL_ 936 ST_IDC_CC_BYPA_03 0 "Kein Blinken" 1 "Langsamer Takt = 1 Hz" 2 "Schneller Takt = 3 Hz" 3 "Signal ungültig";
VAL_ 793 ST_CC_CFCT 0 "Betreffende CC-message wird gelöscht" 1 "CC-message display" 3 "Signal ungültig";
VAL_ 793 ST_IDC_CC_CFCT 0 "Kein Blinken" 1 "Langsamer Takt = 1 Hz" 2 "Schneller Takt = 3 Hz" 3 "Signal ungültig";
VAL_ 404 ST_CC_DFNS 0 "Betreffende CC-message wird gelöscht" 1 "CC-message display" 3 "Sendefunktion nicht in Betrieb";
VAL_ 404 ST_IDC_CC_DFNS 0 "Kein_Blinken" 1 "Langsamer Takt = 1 Hz" 2 "Schneller Takt = 3 Hz" 3 "Sendefunktion nicht in Betrieb";
VAL_ 781 ST_CC_DRASY 0 "Betreffende CC-message wird gelöscht" 1 "CC-message display" 3 "Signal ungültig";
VAL_ 781 ST_IDC_CC_DRASY 0 "Kein Blinken" 1 "Langsamer Takt = 1 Hz" 2 "Schneller Takt = 3 Hz" 3 "Signal ungültig";
VAL_ 679 ST_CC_DRDY_COOTD 0 "Betreffende CC-message wird gelöscht" 1 "CC-message display" 3 "Signal ungültig";
VAL_ 679 TRANF_CC_DRDY_COOTD 15 "Signal ungültig";
VAL_ 679 ST_IDC_CC_DRDY_COOTD 0 "Kein Blinken" 1 "Langsamer Takt = 1 Hz" 2 "Schneller Takt = 3 Hz" 3 "Signal ungültig";
VAL_ 662 ST_CC_EHC 0 "Betreffende CC-message wird gelöscht" 1 "CC-message display" 3 "Signal ungültig";
VAL_ 662 ST_IDC_CC_EHC 0 "Kein Blinken" 1 "Langsamer Takt = 1 Hz" 2 "Schneller Takt = 3 Hz" 3 "Signal ungültig";
VAL_ 660 ST_CC_EPS 0 "Betreffende CC-message wird gelöscht" 1 "CC-message display" 3 "Signal ungültig";
VAL_ 660 ST_IDC_CC_EPS 0 "Kein Blinken" 1 "Langsamer Takt = 1 Hz" 2 "Schneller Takt = 3 Hz" 3 "Signal ungültig";
VAL_ 416 NO_CC_GRB 65533 "SIGNALTAG_FCTIF_NOT_AVAILABLE" 65534 "SIGNALTAG_FCT_ERROR" 65535 "Sendefunktion nicht in Betrieb";
VAL_ 416 ST_CC_GRB 0 "Betreffende CC-message wird gelöscht" 1 "CC-message display" 3 "Signal ungültig";
VAL_ 416 TRANF_CC_GRB 13 "SIGNALTAG_FCTIF_NOT_AVAILABLE" 14 "SIGNALTAG_FCT_ERROR" 15 "Sendefunktion nicht in Betrieb";
VAL_ 416 ST_IDC_CC_GRB 0 "Kein Blinken" 1 "Langsamer Takt = 1 Hz" 2 "Schneller Takt = 3 Hz" 3 "Signal ungültig";
VAL_ 661 ST_CC_HVSTO 0 "Betreffende CC-message wird gelöscht" 1 "CC-message display" 3 "Sendefunktion nicht in Betrieb";
VAL_ 661 ST_IDC_CC_HVSTO 0 "Kein_Blinken" 1 "Langsamer Takt = 1 Hz" 2 "Schneller Takt = 3 Hz" 3 "Sendefunktion nicht in Betrieb";
VAL_ 822 NO_CC_MESS_1 0 "CC-Meldung \"CC i.O.\"" 65535 "Signal ungültig";
VAL_ 822 NO_CC_MESS_2 65534 "Keine CC-Meldung" 65535 "Signal ungültig";
VAL_ 822 NO_CC_MESS_3 65534 "Keine CC-Meldung" 65535 "Signal ungültig";
VAL_ 780 ST_CC_PMA 0 "Betreffende CC-message wird gelöscht" 1 "CC-message display" 3 "Signal ungültig";
VAL_ 780 ST_IDC_CC_PMA 0 "Kein Blinken" 1 "Langsamer Takt = 1 Hz" 2 "Schneller Takt = 3 Hz" 3 "Signal ungültig";
VAL_ 654 ST_CC_VDC 0 "Betreffende CC-message wird gelöscht" 1 "CC-message display" 3 "Signal ungültig";
VAL_ 654 ST_IDC_CC_VDC 0 "Kein Blinken" 1 "Langsamer Takt = 1 Hz" 2 "Schneller Takt = 3 Hz" 3 "Signal ungültig";
VAL_ 728 DISP_CHGNG_I_EFF 252 "Keine_Anzeige" 253 "SIGNALTAG_FCTIF_NOT_AVAILABLE" 254 "SIGNALTAG_FCT_ERROR" 255 "Sendefunktion nicht in Betrieb";
VAL_ 728 DISP_CHGNG_I_LIM_MOD_2 253 "SIGNALTAG_FCTIF_NOT_AVAILABLE" 254 "SIGNALTAG_FCT_ERROR" 255 "Sendefunktion nicht in Betrieb";
VAL_ 728 DISP_MAX_CHGNG_I_LIM_MOD_2 253 "SIGNALTAG_FCTIF_NOT_AVAILABLE" 254 "SIGNALTAG_FCT_ERROR" 255 "Sendefunktion nicht in Betrieb";
VAL_ 728 DISP_MIN_CHGNG_I_LIM_MOD_2 253 "SIGNALTAG_FCTIF_NOT_AVAILABLE" 254 "SIGNALTAG_FCT_ERROR" 255 "Sendefunktion nicht in Betrieb";
VAL_ 728 DisplayPowerChargingStatus 0 "Init" 1 "Anzeige" 2 "Keine_Anzeige" 3 "Anzeige_und_Degradierung_kalt" 4 "Anzeige_und_Degradierung_heiss" 13 "SIGNALTAG_FCTIF_NOT_AVAILABLE" 14 "SIGNALTAG_FCT_ERROR" 15 "Sendefunktion nicht in Betrieb";
VAL_ 728 DisplayRestTimeEndOfChargingStat 0 "Init" 1 "Anzeige" 2 "Keine_Anzeige" 13 "SIGNALTAG_FCTIF_NOT_AVAILABLE" 14 "SIGNALTAG_FCT_ERROR" 15 "Sendefunktion nicht in Betrieb";
VAL_ 728 DisplayChargingCurrentEffStatus 0 "Init" 1 "Anzeige" 2 "Keine_Anzeige" 13 "SIGNALTAG_FCTIF_NOT_AVAILABLE" 14 "SIGNALTAG_FCT_ERROR" 15 "Sendefunktion nicht in Betrieb";
VAL_ 728 DisplayChargingTimeHrStatus 0 "Init" 1 "Anzeige" 2 "Keine_Anzeige" 13 "SIGNALTAG_FCTIF_NOT_AVAILABLE" 14 "SIGNALTAG_FCT_ERROR" 15 "Sendefunktion nicht in Betrieb";
VAL_ 728 DisplayChargingTimeMnStatus 0 "Init" 1 "Anzeige" 2 "Keine_Anzeige" 13 "SIGNALTAG_FCTIF_NOT_AVAILABLE" 14 "SIGNALTAG_FCT_ERROR" 15 "Sendefunktion nicht in Betrieb";
VAL_ 728 DisplaySoeChargingTargetStatus 0 "Init" 1 "Anzeige" 2 "Keine_Anzeige" 13 "SIGNALTAG_FCTIF_NOT_AVAILABLE" 14 "SIGNALTAG_FCT_ERROR" 15 "Sendefunktion nicht in Betrieb";
VAL_ 728 TechnicalSoeChargingPredictionDe 125 "SIGNALTAG_FCTIF_NOT_AVAILABLE" 126 "SIGNALTAG_FCT_ERROR" 127 "Sendefunktion nicht in Betrieb";
VAL_ 941 DISP_OPMO_DRV_HYB 0 "Zukunftsscreen_ausblenden" 1 "zeitvariantes Boosten" 2 "Assisten" 4 "elektrische Verbraucher" 8 "Rekuperation" 16 "verbrennungsmotorisches Fahren" 32 "elektrisches Fahren" 64 "Verbrennungskraftmaschine" 128 "Lastpunktanhebung" 256 "Fahrzeug fährt" 512 "Vorausschauendes Energiemanagement PHEV aktiv" 1024 "Zukunftsscreen_einblenden" 4095 "Signal ungültig";
VAL_ 941 DISP_HYB_FRSG_DIST 0 "0 Balken" 1 "1 Balken" 2 "2 Balken" 3 "3 Balken" 4 "4 Balken" 5 "5 Balken" 6 "6 Balken" 7 "7 Balken" 8 "8 Balken" 15 "Signal ungültig";
VAL_ 796 RQ_ACTV_PFGS 0 "keine Anforderung" 1 "pFGS aktivieren" 3 "Signal ungültig";
VAL_ 796 QU_FN_EDP 1 "Funktion nicht aktiv" 2 "Funktion nicht aktiv (in diesem Land eingeschränkt verfügbar)" 3 "Funktion nicht aktiv (in diesem Land nicht verfügbar)" 6 "Fehler" 9 "Funktion aktiv" 10 "Funktion aktiv (in diesem Land eingeschränkt verfügbar)" 11 "Funktion aktiv (in diesem Land nicht verfügbar)" 14 "Funktion_nicht_verfügbar" 15 "Sendefunktion nicht in Betrieb";
VAL_ 796 RQ_ACTV_SCW 0 "Keine_Anforderung" 1 "SCW_aktivieren" 3 "Sendefunktion nicht in Betrieb";
VAL_ 796 RQ_ACTV_WARN_LNCH 0 "Keine_Anforderung" 1 "mit Lenkeingriff. Warnzeitpunkt sehr früh." 2 "mit Lenkeingriff. Warnzeitpunkt Kundeneinstellung." 3 "Sendefunktion nicht in Betrieb";
VAL_ 796 CTR_CL_STW_DRS 0 "Aus" 1 "Gruen" 2 "Gelb" 4 "Rot" 13 "SIGNALTAG_FCTIF_NOT_AVAILABLE" 14 "SIGNALTAG_FCT_ERROR" 15 "Sendefunktion nicht in Betrieb";
VAL_ 796 CTR_FOM_STW_DRS 0 "Aus" 1 "Blitzen" 2 "Atmen" 3 "Blinken" 4 "Pulsen" 5 "Dauerleuchten" 13 "SIGNALTAG_FCTIF_NOT_AVAILABLE" 14 "SIGNALTAG_FCT_ERROR" 15 "Sendefunktion nicht in Betrieb";
VAL_ 796 ST_SFN_SLA_FRSG 0 "Funktion_in_diesem_Land_verfuegbar" 1 "Funktion_in_diesem_Land_nicht_verfuegbar" 3 "Sendefunktion nicht in Betrieb";
VAL_ 796 ST_SFN_SLA_MOD 0 "Funktion_in_diesem_Land_verfuegbar" 1 "Funktion_in_diesem_Land_nicht_verfuegbar" 3 "Sendefunktion nicht in Betrieb";
VAL_ 796 ST_SFN_SLA_FRSG_STREET 0 "Funktion_in_diesem_Land_verfuegbar" 1 "Funktion_in_diesem_Land_nicht_verfuegbar" 3 "Sendefunktion nicht in Betrieb";
VAL_ 796 ST_SFN_UCC 0 "Funktion_in_dieser_Region_verfuegbar" 1 "Funktion_in_dieser_Region_nicht_verfuegbar" 2 "Funktion_in_dieser_Region_nur_beschraenkt_verfuegbar" 3 "Sendefunktion nicht in Betrieb";
VAL_ 796 ST_AVAI_QMAN 0 "Funktion_in_diesem_Land_verfuegbar" 1 "Funktion_in_diesem_Land_nicht_verfuegbar" 3 "Sendefunktion nicht in Betrieb";
VAL_ 515 DISP_LAG_ARRWS 0 "Verwendung ab SOP2020." 1 "Pfeil_Rechts_Reduziert" 2 "Pfeil_Rechts_Standard" 3 "Pfeil_Rechts_hervorgehoben" 4 "Pfeil_Rechts_stark_hervorgehoben" 8 "Pfeil_Links_Reduziert" 16 "Pfeil_Links_Standard" 24 "Pfeil_Links_hervorgehoben" 32 "Pfeil_Links_stark_hervorgehoben" 64 "Verwendung ab SOP2020." 253 "I.d.R. keine Interpretation Signal-Tags durch Head Unit oder Kombi. Hinweis: Reserviert für  funktionale Kennung Signal-Tag." 254 "I.d.R. keine Interpretation Signal-Tags durch Head Unit oder Kombi. Hinweis: Reserviert für  funktionale Kennung Signal-Tag." 255 "Sendefunktion nicht in Betrieb";
VAL_ 515 DISP_LAG_NAPA 0 "keine_Anzeige_Engstelle" 1 "Anzeige_Engstelle_Querfuehrung_nicht_aktiv" 2 "Anzeige_Engstelle_Querfuehrung_aktiv" 13 "Hinweis: Reserviert für funktionale Kennung Signal-Tag" 14 "Hinweis: Reserviert für funktionale Kennung Signal-Tag" 15 "Sendefunktion nicht in Betrieb";
VAL_ 515 DISP_LAG_ARRWS_TYP 0 "Pfeil_Standard" 1 "Pfeil_Erweitert" 3 "Sendefunktion nicht in Betrieb";
VAL_ 451 ST_ISA_2 0 "ISA_nicht_aktiv" 1 "ISA mit manueller Übernahme mit Fahrerbetätigung aktiv" 2 "ISA mit automatischer Übernahme ohne Fahrerbetätigung aktiv" 3 "Sendefunktion nicht in Betrieb";
VAL_ 451 DISP_GAPC_MOD 0 "Keine_Anforderung" 1 "Adaptive_Abstandsstufen" 3 "Sendefunktion nicht in Betrieb";
VAL_ 451 DISP_HDC 0 "Keine HDC-Anzeige" 1 "HDC-Standby" 2 "HDC aktiv" 3 "Sendefunktion nicht in Betrieb";
VAL_ 451 DISP_GAP_INFO 0 "Keine Anzeige der AI" 2 "Anzeige der AI" 3 "Sendefunktion nicht in Betrieb";
VAL_ 477 DISP_V_SUG_2 0 "Keine_Anzeige_Tachoband" 253 "Hinweis: Reserviert für funktionale Kennung Signal-Tag." 254 "Hinweis: Reserviert für funktionale Kennung Signal-Tag." 255 "Sendefunktion nicht in Betrieb";
VAL_ 477 DISP_OFFS_BOT_SAIL_2 13 "Hinweis: Reserviert für funktionale Kennung Signal-Tag." 14 "Hinweis: Reserviert für funktionale Kennung Signal-Tag." 15 "Sendefunktion nicht in Betrieb";
VAL_ 477 DISP_OFFS_TOP_SAIL_2 13 "Hinweis: Reserviert für funktionale Kennung Signal-Tag." 14 "Hinweis: Reserviert für funktionale Kennung Signal-Tag." 15 "Sendefunktion nicht in Betrieb";
VAL_ 477 DisplayTakeOverRequestReason 0 "Keine_Fahreruebernahmeaufforderung" 1 "Fahreruebernahmeaufforderung_Ampel_aktiv" 2 "Fahreruebernahmeaufforderung_Stoppschild_aktiv" 13 "Reserviert_nicht_verfuegbar" 14 "Reserviert_Fehler" 15 "Sendefunktion nicht in Betrieb";
VAL_ 868 DRVBH_ECO_CTG_1_ST 0 "Keine Änderung" 1 "Blinkend" 2 "Nicht blinkend" 3 "Signal ungültig";
VAL_ 868 DRVBH_ECO_CTG_2_ST 0 "Keine Änderung" 1 "Blinkend" 2 "Nicht blinkend" 3 "Signal ungültig";
VAL_ 868 DRVBH_ECO_CTG_3_ST 0 "Keine Änderung" 1 "Blinkend" 2 "Nicht blinkend" 3 "Signal ungültig";
VAL_ 1066 DRVBH_2_CTG_1_ST 0 "Kein Highlight" 1 "Verbesserungs-Highlight" 2 "Verschlechterungs-Highlight" 3 "Signal ungültig";
VAL_ 1066 DRVBH_2_CTG_2_ST 0 "Kein Highlight" 1 "Verbesserungs-Highlight" 2 "Verschlechterungs-Highlight" 3 "Signal ungültig";
VAL_ 1066 DRVBH_2_CTG_3_ST 0 "Kein Highlight" 1 "Verbesserungs-Highlight" 2 "Verschlechterungs-Highlight" 3 "Signal ungültig";
VAL_ 1066 DRVBH_2_AVAI 0 "Fahrstilanalyse nicht verfügbar" 1 "Fahrstilanalyse ECO verfügbar" 15 "Signal ungültig";
VAL_ 1066 ECO_TIPS_DISP_2 0 "Kein Tipp" 1 "Langsamer beschleunigen" 2 "Geschwindigkeit reduzieren (km/h)" 3 "Vorrausschauender Bremsen" 4 "Wird nur in Fahrzeugen mit Handschaltung versendet." 5 "Gangwahlschalter in D-Mode bewegen" 6 "Relevant für Handschalter" 7 "Relevant für Automatikgetriebe" 8 "Verzögerungsassistent" 9 "Verzögerungsassistent" 10 "Verzögerungsassistent" 11 "Verzögerungsassistent" 12 "Verzögerungsassistent" 13 "Verzögerungsassistent" 14 "Verzögerungsassistent" 15 "Verzögerungsassistent" 16 "Wird nur ausgelöst wenn kein anderer ECO-Tipp anliegt" 17 "Wird nur ab SP 2009 versendet." 18 "Wird nur ab SP 2009 versendet." 19 "Wird nur in Fahrzeugen mit Automatik versendet." 20 "Geschwindigkeit reduzieren (mph)" 255 "Signal ungültig";
VAL_ 456 DISP_MUX_DT_HVSTO_2 3 "Komfort" 4 "Sport" 5 "Sport +" 7 "Eco Pro" 8 "Eco Pro+" 15 "Signal ungültig";
VAL_ 456 DisplayTempEDriveSystem 253 "SIGNALTAG_FCTIF_NOT_AVAILABLE" 254 "SIGNALTAG_FCT_ERROR" 255 "Sendefunktion nicht in Betrieb";
VAL_ 929 RSDW_DRS_MNV 253 "SIGNALTAG_FCTIF_NOT_AVAILABLE" 254 "SIGNALTAG_FCT_ERROR" 255 "Sendefunktion nicht in Betrieb";
VAL_ 929 DISP_UN_FACT_DRS_MNV 0 "Ausgabe in Maßeinheit: Meter" 1 "Ausgabe in Maßeinheit: Yard" 2 "Ausgabe in Maßeinheit: Fuss" 3 "Sendefunktion nicht in Betrieb";
VAL_ 929 DISP_SYM_RF_DRS_MNV 0 "Kein_Symbol" 1 "Rueckfahrassistent_aktiv" 2 "Anhaengerassistent_aktiv" 13 "SIGNALTAG_FCTIF_NOT_AVAILABLE" 14 "SIGNALTAG_FCT_ERROR" 15 "Sendefunktion nicht in Betrieb";
VAL_ 929 PROCS_SYM_DRS_MNV 0 "Kein_Hinweis_kein_Symbol" 1 "Stopp_Zeichen" 2 "Lenkrad_durchgestrichen" 3 "Pfeil_nach_unten" 4 "Achtung" 5 "Fertig" 6 "Pfeil_nach_oben" 7 "Fahrzeug_abgestellt" 8 "Information" 13 "SIGNALTAG_FCTIF_NOT_AVAILABLE" 14 "SIGNALTAG_FCT_ERROR" 15 "Sendefunktion nicht in Betrieb";
VAL_ 929 AVL_KNAN_TRAI 61 "SIGNALTAG_FCTIF_NOT_AVAILABLE" 62 "SIGNALTAG_FCT_ERROR" 63 "Sendefunktion nicht in Betrieb";
VAL_ 929 RQ_SOU_ISS_DRS_MNV 0 "DEFAULT / Rangiermanöver fordert keinen Ton." 1 "Ausgabe des Rangiermanöver-spezifischen Tons 1 für Handlungshinweise." 2 "Ausgabe des Rangiermanöver -spezifischen Tons 2 nach erfolgreichem Manöver." 3 "Sendefunktion nicht in Betrieb";
VAL_ 929 TAR_KNAN_TRAS 61 "SIGNALTAG_FCTIF_NOT_AVAILABLE" 62 "SIGNALTAG_FCT_ERROR" 63 "Sendefunktion nicht in Betrieb";
VAL_ 929 MAX_KNAN_TRAS 61 "SIGNALTAG_FCTIF_NOT_AVAILABLE" 62 "SIGNALTAG_FCT_ERROR" 63 "Sendefunktion nicht in Betrieb";
VAL_ 929 RSDW_DRS_MNV_2 4093 "SIGNALTAG_FCTIF_NOT_AVAILABLE" 4094 "SIGNALTAG_FCT_ERROR" 4095 "Sendefunktion nicht in Betrieb";
VAL_ 630 ST_DISP_FAS_PKG 0 "Nicht_aktiv" 1 "Zielanzeige_Nicht_Anwaehlbar" 2 "Zielanzeige_Anwaehlbar" 3 "Ziel_ausgewaehlt" 4 "Verfahren" 5 "Ziel_Erreicht" 15 "Sendefunktion nicht in Betrieb";
VAL_ 630 RQ_SOU_ISS_FAS_PKG 0 "DEFAULT / PMA fordert keinen Ton" 1 "Ausgabe des PMA-spezifischen Tons 1 für Handlungshinweise" 2 "Ausgabe des PMA-spezifischen Tons 2 nach erfolgreichem Manöver" 3 "Sendefunktion nicht in Betrieb";
VAL_ 630 PROC_FAS_PKG 0 "Keine_Anzeige" 2 "PDC_Sensoren_vorn_verschmutzt" 3 "PDC_Sensoren_hinten_verschmutzt" 5 "PDC_Sensoren_ausgefallen" 6 "Parkkameras_verschmutzt" 8 "PDC_Sensoren_verschmutzt" 10 "PDC_Sensoren_gestoert" 12 "Zielverfeinerung" 13 "Disclaimer_1" 14 "Disclaimer_2" 15 "Remote_wird_aktiviert" 16 "Fahrbahn_ungeeignet" 17 "Anhaenger_angekoppelt" 18 "Außentemperatur_zu_niedrig" 19 "Remote_unterbrochen" 20 "Schluesselbatterie_entladen" 21 "Verbindung_zum_Fahrzeug_gestoert" 23 "RCP_wird_deaktiviert" 24 "Abstand_zum_Fahrzeug_verringern" 25 "Tuer_offen" 26 "Fahrertuer_offen" 27 "Beifahrertuer_offen" 28 "Motorhaube_offen" 29 "Kofferraum_offen" 30 "Kofferraumscheibe_offen" 31 "Verdeck_wird_verfahren" 32 "Tuer_auf_Fahrerseite_hinten_offen" 33 "Tuer_auf_Beifahrerseite_hinten_offen" 34 "Heckklappe_offen" 35 "Fahrereingriff" 36 "Freigabe_Einparken_und_Remotewechsel" 37 "Freigabe_Ausparken_und_Remotewechsel" 38 "Freigabe_Wiederaufnahme_Einparken_und_Remotewechsel" 39 "Freigabe_Wiederaufnahme_Ausparken_und_Remotewechsel" 40 "Freigabe_Einparken" 41 "Freigabe_Ausparken" 42 "Freigabe_Wiederaufnahme_Einparken" 43 "Freigabe_Wiederaufnahme_Ausparken" 44 "Anfahraufforderung" 50 "Schluessel_im_Fahrzeug" 51 "Aktivierung_unterbrochen" 53 "Fahrzeug_gegen_Wegrollen_sichern" 55 "Parktaste_druecken" 56 "Parken_ausgefallen" 57 "Max_Zeit_ueberschritten" 58 "PDC_Sensoren_vorne_gestoert" 59 "PDC_Sensoren_hinten_gestoert" 60 "PDC_Sensoren_vorne_ausgefallen" 61 "PDC_Sensoren_hinten_ausgefallen" 62 "Max_Fahrtstrecke_ueberschritten" 63 "Remote_aktivieren_Engine_Start" 64 "Remote_aktivieren_Engine_Restart" 65 "Remote_aktivieren_Start" 66 "Remote_anfahren" 67 "Remote_fortfahren" 68 "Abstand_zum_Fahrzeug_verringern" 69 "PMA_aktiv" 70 "Werkstattmodus" 71 "Motor_laeuft" 72 "Motor_laeuft_Engine_Stop" 73 "Beenden_Nachfrage" 74 "Beenden_Innenraum" 75 "Taste_nicht_erlaubt" 76 "Parkangebot_eingeschraenkt" 79 "Falscher Blinker: Parkmanöver abgebrochen" 80 "Lenkrad_nicht_freigaengig" 81 "Geschwindigkeit_zu_hoch" 82 "Falscher_Gang" 83 "Schlupf_erkannt" 84 "Anzeigeverlust_durch_System" 85 "Anzeigeverlust_durch_Fahrer" 86 "Freigabe_zurueckgezogen" 87 "Bremse_betaetigt" 88 "Hindernis_im_Gefahrenbereich" 89 "Fahrpedal_betaetigt" 90 "GWS_betaetigt" 91 "Anfahren_nicht_moeglich" 92 "Endposition_nicht_erreichbar" 93 "Endposition_nicht_erreichbar_gesichert" 94 "Sensor_blind" 95 "Stoerschall_erkannt" 96 "Feststellbremse_aktiv" 97 "Steigung_zu_gross" 98 "Fahrergurt_geoeffnet" 99 "Parkassistent_bereit" 100 "Schlupf_bei_Vermessung" 101 "Weiter_vor_fahren" 102 "Startkorridor_erreicht" 103 "Abfrage_Einparken" 104 "Blinker_setzen" 105 "Kollisionsgefahr" 106 "Haende_weg_R_einlegen" 107 "Haende_weg" 108 "Haende_weg_rueckwaerts_fahren" 109 "Parkvorgang_aktiv" 110 "Rueckwaerts_fahren" 111 "Vorwaerts_fahren" 112 "Fahrzeug_anhalten" 113 "Geschwindigkeitsvorwarnung" 114 "Wiederaufnahme_moeglich" 115 "Wiederaufnahme_nicht_moeglich" 116 "Endposition_erreicht_PMA_Q" 117 "Endposition_erreicht_PMA_LQ" 118 "Endposition_nicht_erreicht_PMA_Q" 119 "Endposition_nicht_erreicht_PMA_LQ" 120 "Endposition_Ausparken_erreicht_PMA_Q" 121 "Endposition_Ausparken_nicht_erreicht_PMA_Q" 122 "Parkassistent_aktivieren" 123 "Parktaste_loesen" 124 "Bremse_betaetigen" 125 "Endposition_Ausparken_erreicht_PMA_LQ" 126 "Endposition_Ausparken_nicht_erreicht_PMA_LQ" 127 "Gurt_anlegen" 128 "Blinker_ruecksetzen" 129 "Parkluecke_auswaehlen" 130 "Warnblinker_ruecksetzen" 131 "Bitte Rückwärtsgang einlegen und Lenkvorgang abwarten" 132 "Bitte Vorwärtsgang einlegen und Lenkvorgang abwarten" 134 "Haende_weg_vorwaerts_fahren" 135 "Ausparkluecke_auswaehlen" 199 "ActivePDC_temporaer_deaktivieren_AHV_ausgefahren" 200 "ActivePDC_temporaer_deaktivieren" 201 "Wechsel_zu_Lokal_Fehler" 202 "Wechsel_Lokal_zu_Remote_Fertig" 203 "Wechsel_Remote_zu_Lokal_Waiting" 248 "Ferngesteuertes_Parken_ausgefallen_selbst_sichern" 249 "Verbindungsaufbau" 250 "Ferngesteuertes_Parken_nicht_aktivierbar" 251 "Verbindung_zum_Fahrzeug_gestoert_selbst_sichern" 253 "SIGNALTAG_FCTIF_NOT_AVAILABLE" 254 "SIGNALTAG_FCT_ERROR" 255 "Sendefunktion nicht in Betrieb";
VAL_ 630 ST_PKOF_FAS_PKG 0 "Keine_Parkangebote" 1 "Hinten_Rechts_Laengs_Einparken" 2 "Hinten_Rechts_Quer_Einparken_Rueckwaerts" 4 "Hinten_Rechts_Quer_Einparken_Vorwaerts" 8 "Hinten_Links_Laengs_Einparken" 16 "Hinten_Links_Quer_Einparken_Rueckwaerts" 32 "Hinten_Links_Quer_Einparken_Vorwaerts" 64 "Vorn_Rechts_Ausparken" 128 "Vorn_Links_Ausparken" 256 "Gerade_1" 512 "Gerade_2" 16777213 "SIGNALTAG_FCTIF_NOT_AVAILABLE" 16777214 "SIGNALTAG_FCT_ERROR" 16777215 "Sendefunktion nicht in Betrieb";
VAL_ 630 DISP_SYM_RF_FAS_PKG 0 "Kein_Symbol" 1 "Parklueckensuche" 2 "Parkluecke_gefunden_keine_Aktivierung" 3 "Parkluecke_gefunden_Aktivierung_vorhanden" 4 "PMA" 5 "PMA LQ" 6 "Situation_Ausparken_erkannt" 7 "PMA" 8 "PMA LQ" 15 "Sendefunktion nicht in Betrieb";
VAL_ 630 ST_SOU_FAS_PKG 0 "keine Tonausgabe bei gefundener Parkluecke." 1 "Tonausgabe bei gefundener Parklueke." 3 "Sendefunktion nicht in Betrieb";
VAL_ 748 DISP_CASC 0 "Keine_Anzeige" 1 "Anzeige_Kaskade" 2 "Nicht_befuellt" 3 "Sendefunktion nicht in Betrieb";
VAL_ 748 UN_V_FRSG 0 "Einheit mph" 1 "Einheit km/h" 3 "Signal ungültig";
VAL_ 748 UN_DIST_FRSG 0 "Einheit meter" 1 "Wird ab SP2018 nicht mehr verwendet." 2 "Wird ab SP2018 nicht mehr verwendet." 3 "Signal ungültig";
VAL_ 748 DISP_V_FRSG_TYP 0 "keine Anzeige" 1 "Gesetzliches Tempolimit" 2 "Richtgeschwindigkeit" 3 "Signal ungültig";
VAL_ 748 DISP_OP_TAO_SUG_V 0 "Kein Übernahmeangebot" 1 "Angebot zur Reduktion der Setzgeschwindigkeit" 2 "Angebot zur Erhöhung der Setzgeschwindigkeit" 3 "Signal ungültig";
VAL_ 748 ST_ISA 0 "ISA_nicht_aktiv" 1 "ISA mit manueller Übernahme mit Fahrerbetätigung aktiv" 2 "ISA mit automatischer Übernahme ohne Fahrerbetätigung aktiv" 3 "Sendefunktion nicht in Betrieb";
VAL_ 748 DISP_ACY_DCRN_ASST_2 0 "VZA auskodiert, Checkbox wird in MMI nicht angezeigt" 1 "VZA verfügbar, Checkbox wird in MMI angezeigt" 2 "VZA verfügbar, Checkbox wird in MMI nicht angezeigt" 3 "Signal ungültig";
VAL_ 755 TAR_TYP_REAS_DCRN_3 0 "Keine_Anzeige" 1 "Geschwindigkeitsbegrenzung" 2 "Strassenverlauf" 3 "Ende Begrenzung Geschwindigkeitslimit, gilt erst ab SP2018" 5 "Abbiegemoeglichkeit" 8 "Fahrtrichtung im Uhrzeigersinn" 10 "Fahrtrichtung gegen Uhrzeigersinn" 16 "Wird nur ab SOP2020 verwendet." 17 "Wird nur ab SOP2020 verwendet." 19 "Stoppschild" 20 "Ampel_ohne_Praediktion" 21 "Ampel_unsicher" 22 "Ampel_rot" 23 "Ampel_rot_gelb" 24 "Ampel_gelb" 25 "Ampel_gruen" 26 "Ampel_gruen_pulsierend" 27 "Ampel_gruen_Schild_rechts_oben" 28 "Ampel_gruen_Schild_rechts_unten" 253 "I.d.R. keine Interpretation Signal-Tags durch Head Unit oder Kombi. Hinweis: Reserviert für funktionale Kennung Signal-Tag." 254 "I.d.R. keine Interpretation Signal-Tags durch Head Unit oder Kombi. Hinweis: Reserviert für funktionale Kennung Signal-Tag." 255 "Sendefunktion nicht in Betrieb";
VAL_ 686 DISP_PWR_DRV_2 4093 "Hinweis: Reserviert für funktionale Kennung Signal-Tag." 4094 "Hinweis: Reserviert für funktionale Kennung Signal-Tag." 4095 "Sendefunktion nicht in Betrieb";
VAL_ 686 QTA_IMME_EENG_DRV_RECUP 253 "Hinweis: Reserviert für funktionale Kennung Signal-Tag." 254 "Hinweis: Reserviert für funktionale Kennung Signal-Tag." 255 "Sendefunktion nicht in Betrieb";
VAL_ 686 DISP_DSTN_SOC 253 "Hinweis: Reserviert für funktionale Kennung Signal-Tag." 254 "Hinweis: Reserviert für funktionale Kennung Signal-Tag." 255 "Sendefunktion nicht in Betrieb";
VAL_ 934 DISP_REPAT_EL_SHTR 0 "Kein Balken" 1 "Ein Balken" 2 "Zwei Balken" 3 "Signal ungültig";
VAL_ 934 DISP_REPAT_EL_RNG_SHTR_BST_2 4093 "SIGNALTAG_FCTIF_NOT_AVAILABLE" 4094 "SIGNALTAG_FCT_ERROR" 4095 "Sendefunktion nicht in Betrieb";
VAL_ 243 DISP_TARG_DRV 0 "Anzeige aus" 1 "1.Gang" 2 "2.Gang" 3 "3.Gang" 4 "4.Gang" 5 "5.Gang" 6 "6.Gang" 7 "7.Gang" 8 "8.Gang" 9 "9. Gang" 14 "N Gang" 15 "Signal ungültig";
VAL_ 243 DISP_GSI_DRV 0 "Anzeige aus" 1 "Runterschalthinweis" 2 "Hochschalthinweis" 3 "Signal ungültig";
VAL_ 243 ReqDispAvailabilityDrivePower 0 "Keine Anzeige der CCM in Kombi" 1 "Anzeige der CCM im Kombi" 3 "Sendefunktion nicht in Betrieb";
VAL_ 243 DISP_GR_PT 0 "Initialisierung" 1 "N" 2 "R" 4 "Dunkelschaltung" 5 "1.Gang" 6 "2.Gang" 7 "3.Gang" 8 "4.Gang" 9 "5.Gang" 10 "6.Gang" 11 "7.Gang" 12 "8.Gang" 13 "(wird derzeit nur in Hybridfahrzeugen verwendet)" 61 "Hinweis: Reserviert für funktionale Kennung Signal-Tag." 62 "Hinweis: Reserviert für funktionale Kennung Signal-Tag." 63 "Sendefunktion nicht in Betrieb";
VAL_ 243 CTR_DISP_PWSPAR 4093 "Hinweis: Reserviert für funktionale Kennung Signal-Tag." 4094 "Hinweis: Reserviert für funktionale Kennung Signal-Tag." 4095 "Sendefunktion nicht in Betrieb.";
VAL_ 595 DISP_S_ENG_TORQ_BS_SCAL_VL 0 "10" 1 "20" 2 "30" 3 "40" 4 "50" 5 "60" 6 "70" 7 "80" 8 "90" 9 "100" 10 "110" 11 "120" 12 "wird im SP2009 und SP2011 nicht verwendet" 13 "wird im SP2009 und SP2011 nicht verwendet" 14 "wird im SP2009 und SP2011 nicht verwendet" 15 "Signal ungültig";
VAL_ 595 DISP_S_ENG_PWR_BS_SCAL_VL 0 "10" 1 "20" 2 "30" 3 "40" 4 "50" 5 "60" 6 "70" 7 "80" 8 "90" 9 "100" 10 "110" 11 "120" 12 "wird im SP2009 und SP2011 nicht verwendet" 13 "wird im SP2009 und SP2011 nicht verwendet" 15 "Signal ungültig";
SIG_GROUP_ 659 e2eGrp_DISP_CC_ARS 1 : CRC_DISP_CC_ARS ALIV_DISP_CC_ARS CHL_DISP_CC_ARS NO_CC_ARS ST_CC_ARS TRANF_CC_ARS ST_IDC_CC_ARS;
SIG_GROUP_ 878 e2eGrp_DISP_CC_BYPA_00 1 : CRC_DISP_CC_BYPA_00 ALIV_DISP_CC_BYPA_00 DISP_CC_BYPA_00_dummy_12_15 NO_CC_BYPA_00 ST_CC_BYPA_00 TRANF_CC_BYPA_00 ST_IDC_CC_BYPA_00;
SIG_GROUP_ 879 e2eGrp_DISP_CC_BYPA_01 1 : CRC_DISP_CC_BYPA_01 ALIV_DISP_CC_BYPA_01 DISP_CC_BYPA_01_dummy_12_15 NO_CC_BYPA_01 ST_CC_BYPA_01 TRANF_CC_BYPA_01 ST_IDC_CC_BYPA_01;
SIG_GROUP_ 809 e2eGrp_DISP_CC_BYPA_02 1 : CRC_DISP_CC_BYPA_02 ALIV_DISP_CC_BYPA_02 DISP_CC_BYPA_02_dummy_12_15 NO_CC_BYPA_02 ST_CC_BYPA_02 TRANF_CC_BYPA_02 ST_IDC_CC_BYPA_02;
SIG_GROUP_ 827 e2eGrp_DISP_CC_BYPA_02 1 : CRC_DISP_CC_BYPA_02 ALIV_DISP_CC_BYPA_02 DISP_CC_BYPA_02_dummy_12_15 NO_CC_BYPA_02 ST_CC_BYPA_02 TRANF_CC_BYPA_02 ST_IDC_CC_BYPA_02;
SIG_GROUP_ 936 e2eGrp_DISP_CC_BYPA_03 1 : CRC_DISP_CC_BYPA_03 ALIV_DISP_CC_BYPA_03 CHL_DISP_CC_BYPA_03 NO_CC_BYPA_03 ST_CC_BYPA_03 TRANF_CC_BYPA_03 ST_IDC_CC_BYPA_03;
SIG_GROUP_ 793 e2eGrp_DISP_CC_CFCT 1 : CRC_DISP_CC_CFCT ALIV_DISP_CC_CFCT CHL_DISP_CC_CFCT NO_CC_CFCT ST_CC_CFCT TRANF_CC_CFCT ST_IDC_CC_CFCT;
SIG_GROUP_ 404 e2eGrp_DISP_CC_DFNS 1 : CRC_DISP_CC_DFNS ALIV_DISP_CC_DFNS CHL_DISP_CC_DFNS NO_CC_DFNS ST_CC_DFNS TRANF_CC_DFNS ST_IDC_CC_DFNS;
SIG_GROUP_ 781 e2eGrp_DISP_CC_DRASY 1 : CRC_DISP_CC_DRASY ALIV_DISP_CC_DRASY DISP_CC_DRASY_dummy_12_15 NO_CC_DRASY ST_CC_DRASY TRANF_CC_DRASY ST_IDC_CC_DRASY;
SIG_GROUP_ 679 e2eGrp_DISP_CC_DRDY_COOTD 1 : CRC_DISP_CC_DRDY_COOTD ALIV_DISP_CC_DRDY_COOTD DISP_CC_DRDY_COOTD_dummy_12_15 NO_CC_DRDY_COOTD ST_CC_DRDY_COOTD TRANF_CC_DRDY_COOTD ST_IDC_CC_DRDY_COOTD;
SIG_GROUP_ 662 e2eGrp_DISP_CC_EHC 1 : CRC_DISP_CC_EHC ALIV_DISP_CC_EHC CHL_DISP_CC_EHC NO_CC_EHC ST_CC_EHC TRANF_CC_EHC ST_IDC_CC_EHC;
SIG_GROUP_ 660 e2eGrp_DISP_CC_EPS 1 : CRC_DISP_CC_EPS ALIV_DISP_CC_EPS CHL_DISP_CC_EPS NO_CC_EPS ST_CC_EPS TRANF_CC_EPS ST_IDC_CC_EPS;
SIG_GROUP_ 416 e2eGrp_DISP_CC_GRB 1 : CRC_DISP_CC_GRB ALIV_DISP_CC_GRB CHL_DISP_CC_GRB NO_CC_GRB ST_CC_GRB TRANF_CC_GRB ST_IDC_CC_GRB;
SIG_GROUP_ 661 e2eGrp_DISP_CC_HVS 1 : CRC_DISP_CC_HVSTO ALIV_DISP_CC_HVSTO CHL_DISP_CC_HVSTO NO_CC_HVSTO ST_CC_HVSTO TRANF_CC_HVSTO ST_IDC_CC_HVSTO DISP_CC_HVS_dummy_40_63;
SIG_GROUP_ 780 e2eGrp_DISP_CC_PMA 1 : CRC_DISP_CC_PMA ALIV_DISP_CC_PMA DISP_CC_PMA_dummy_12_15 NO_CC_PMA ST_CC_PMA TRANF_CC_PMA ST_IDC_CC_PMA;
SIG_GROUP_ 654 e2eGrp_DISP_CC_VDC 1 : CRC_DISP_CC_VDC ALIV_DISP_CC_VDC CHL_DISP_CC_VDC NO_CC_VDC ST_CC_VDC TRANF_CC_VDC ST_IDC_CC_VDC;
SIG_GROUP_ 796 e2eGrp_DISP_DRASY 1 : CRC_DISP_DRASY ALIV_DISP_DRASY DISP_DRASY_dummy_12_13 RQ_ACTV_PFGS DISP_DRASY_dummy_16_31 QU_FN_EDP RQ_ACTV_SCW RQ_ACTV_WARN_LNCH CTR_CL_STW_DRS CTR_FOM_STW_DRS ST_SFN_SLA_FRSG ST_SFN_SLA_MOD ST_SFN_SLA_FRSG_STREET ST_SFN_UCC ST_AVAI_QMAN DISP_DRASY_dummy_58_63;
SIG_GROUP_ 515 e2eGrp_DISP_DRASY_LAG 1 : CRC_DISP_DRASY_LAG ALIV_DISP_DRASY_LAG CHL_DISP_DRASY_LAG DISP_LAG_LNMR DISP_LAG_FRVEH DISP_LAG_STW DISP_LAG_STINTV DISP_LAG_ARRWS DISP_LAG_NAPA DISP_LAG_ARRWS_TYP DISP_DRASY_LAG_dummy_62_63;
SIG_GROUP_ 451 e2eGrp_DISP_DRASY_LNG 1 : CRC_DISP_DRASY_LNG ALIV_DISP_DRASY_LNG CHL_DISP_DRASY_LNG DISP_XCC ACV_FN_DRASY_LDM DISP_SD ST_ISA_2 DISP_GAPC_MOD DISP_HDC DISP_GAP_INFO DISP_GAPC DISP_RQSP VL_RQSP;
SIG_GROUP_ 243 e2eGrp_DISP_RPM_PT 1 : CRC_DISP_RPM_PT ALIV_DISP_RPM_ENG_CRSH DISP_RPM_ENG_CRSH DISP_TARG_DRV DISP_GSI_DRV ReqDispAvailabilityDrivePower DISP_AVL_PWR_REL_RECUP_IGR DISP_RPM_PT_dummy_36_39 DISP_GR_PT DISP_RPM_PT_dummy_46_47 CTR_DISP_PWSPAR DisplayMsaStatus DISP_RPM_PT_dummy_63_63;
